VERSION ""

NS_ :

BS_:

BU_: Engine2 Aftertreatment_1_GasOutlet BrakesSystemController Transmission1 Engine1
VAL_TABLE_ FMI 22 "Data Drifted Low" 21 "Data Drifted High" 20 "Received Network Data In Error" 0 "Above normal (most severe)" 1 "Below normal (most severe)" 2 "Data erratic" 3 "Voltage above normal" 4 "Voltage below normal" 5 "Current below normal" 6 "Current above normal" 7 "Mechanical system not responding" 8 "Abnormal frequency" 9 "Abnormal update rate" 10 "Abnormal rate of change" 11 "Root cause not known" 12 "Bad intelligent device" 13 "Out of calibration" 14 "Special intstructions" 15 "Above normal (least severe)" 16 "Above normal (moderately severe)" 17 "Below normal (least severe)" 18 "Below normal (moderately severe)" 19 "Received network data in error" 31 "Condition Exists" ;
VAL_TABLE_ TireLocation_MUX 51 "TirePress_33_MUX_51" 50 "TirePress_32_MUX_50" 49 "TirePress_31_MUX_49" 48 "TirePress_30_MUX_48" 35 "TirePress_23_MUX_35" 34 "TirePress_22_MUX_34" 33 "TirePress_21_MUX_33" 32 "TirePress_20_MUX_32" 19 "TirePress_13_MUX_19" 18 "TirePress_12_MUX_18" 17 "TirePress_11_MUX_17" 16 "TirePress_10_MUX_16" 1 "TirePress_01_MUX_1" 0 "TirePress_00_MUX_0" ;

BO_ 3221225472 VECTOR__INDEPENDENT_SIG_MSG: 0 Vector__XXX
 SG_ NumberOfMembersInWorkingSet : 0|8@1+ (1,0) [0|0] "" Vector__XXX
 SG_ NncntnuslyMonitoredSystemsStatus : 0|16@1+ (1,0) [0|0] "" Vector__XXX
 SG_ NncntnslyMonitoredSystemsSupport : 0|16@1+ (1,0) [0|0] "" Vector__XXX
 SG_ CntnslyMntrdSystmsSupport_Status : 0|8@1+ (1,0) [0|0] "" Vector__XXX
 SG_ AETCTorqueValue : 0|16@1+ (1,0) [0|64255] "Nm" Vector__XXX
 SG_ TrailerWeight : 0|16@1+ (2,0) [0|128510] "kg" Vector__XXX
 SG_ ReferenceTirePressSetting : 0|8@1+ (8,0) [0|2000] "kPa" Vector__XXX
 SG_ ReferenceTirePress : 0|8@1+ (8,0) [0|2000] "kPa" Vector__XXX
 SG_ TirePressThresholdDetection : 0|3@1+ (1,0) [0|7] "" Vector__XXX
 SG_ TireAirLeakageRate : 0|16@1+ (0.1,0) [0|6425.5] "Pa/s" Vector__XXX
 SG_ CTIWheelEndElectricalFault : 0|2@1+ (1,0) [0|3] "" Vector__XXX
 SG_ CTITireStatus : 0|2@1+ (1,0) [0|3] "" Vector__XXX
 SG_ CTIWheelSensorStatus : 0|2@1+ (1,0) [0|3] "" Vector__XXX
 SG_ TireTemp : 0|16@1+ (0.03125,-273) [-273|1734.96875] "deg C" Vector__XXX
 SG_ TirePress : 0|8@1+ (4,0) [0|1000] "kPa" Vector__XXX
 SG_ EngTurningGearEngaged : 0|2@1+ (1,0) [0|3] "" Vector__XXX
 SG_ AETCSpeedValue : 0|16@1+ (0.125,0) [0|8031.875] "rpm" Vector__XXX
 SG_ DTC5 : 0|32@1+ (1,0) [0|4294967295] "" Vector__XXX
 SG_ DTC4 : 0|32@1+ (1,0) [0|4294967295] "" Vector__XXX
 SG_ DTC3 : 0|32@1+ (1,0) [0|4294967295] "" Vector__XXX
 SG_ DTC2 : 0|32@1+ (1,0) [0|4294967295] "" Vector__XXX
 SG_ DTC5 : 0|32@1+ (1,0) [0|4294967295] "" Vector__XXX
 SG_ DTC4 : 0|32@1+ (1,0) [0|4294967295] "" Vector__XXX
 SG_ DTC3 : 0|32@1+ (1,0) [0|4294967295] "" Vector__XXX
 SG_ DTC2 : 0|32@1+ (1,0) [0|4294967295] "" Vector__XXX

BO_ 2365534462 MOP: 42 Vector__XXX

BO_ 2566834689 DM01_Eng2: 8 Engine2
 SG_ FlashRedStopLamp : 12|2@1+ (1,0) [0|3] "" Vector__XXX
 SG_ FlashProtectLamp : 8|2@1+ (1,0) [0|3] "" Vector__XXX
 SG_ FlashMalfuncIndicatorLamp : 14|2@1+ (1,0) [0|3] "" Vector__XXX
 SG_ FlashAmberWarningLamp : 10|2@1+ (1,0) [0|3] "" Vector__XXX
 SG_ MalfunctionIndicatorLampStatus : 6|2@1+ (1,0) [0|3] "" Vector__XXX
 SG_ AmberWarningLampStatus : 2|2@1+ (1,0) [0|3] "" Vector__XXX
 SG_ RedStopLampState : 4|2@1+ (1,0) [0|3] "" Vector__XXX
 SG_ ProtectLampStatus : 0|2@1+ (1,0) [0|3] "" Vector__XXX
 SG_ DTC5 : 144|32@1+ (1,0) [0|4294967295] "" Vector__XXX
 SG_ DTC4 : 112|32@1+ (1,0) [0|4294967295] "" Vector__XXX
 SG_ DTC3 : 80|32@1+ (1,0) [0|4294967295] "" Vector__XXX
 SG_ DTC2 : 48|32@1+ (1,0) [0|4294967295] "" Vector__XXX
 SG_ DTC1 : 16|32@1+ (1,0) [0|4294967295] "" Vector__XXX

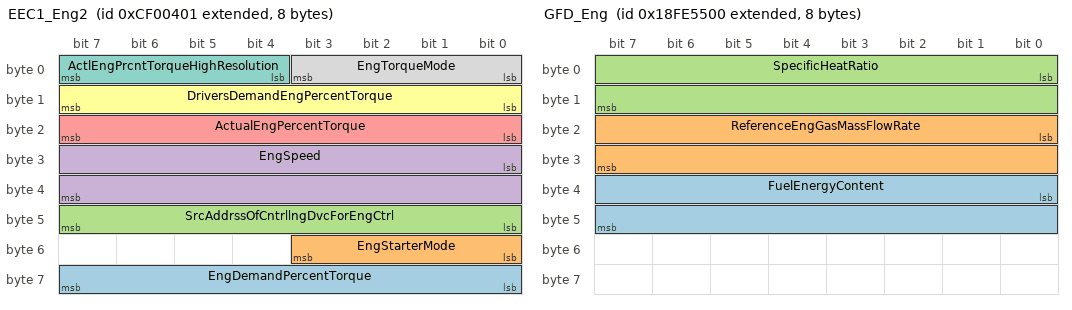
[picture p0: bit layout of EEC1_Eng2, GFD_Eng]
BO_ 2364539905 EEC1_Eng2: 8 Engine2
 SG_ EngDemandPercentTorque : 56|8@1+ (1,-125) [-125|125] "%" Vector__XXX
 SG_ EngStarterMode : 48|4@1+ (1,0) [0|15] "" Vector__XXX
 SG_ SrcAddrssOfCntrllngDvcForEngCtrl : 40|8@1+ (1,0) [0|253] "" Vector__XXX
 SG_ EngSpeed : 24|16@1+ (0.125,0) [0|8031.875] "rpm" Vector__XXX
 SG_ ActualEngPercentTorque : 16|8@1+ (1,-125) [0|125] "%" Vector__XXX
 SG_ DriversDemandEngPercentTorque : 8|8@1+ (1,-125) [0|125] "%" Vector__XXX
 SG_ ActlEngPrcntTorqueHighResolution : 4|4@1+ (0.125,0) [0|0.875] "%" Vector__XXX
 SG_ EngTorqueMode : 0|4@1+ (1,0) [0|15] "" Vector__XXX

BO_ 2364473089 AC_Eng2: 8 Engine2
 SG_ ArbitraryAddressCapable : 63|1@1+ (1,0) [0|1] "" Vector__XXX
 SG_ IndustryGroup M : 60|3@1+ (1,0) [0|7] "" Vector__XXX
 SG_ VehicleSystemInstance : 56|4@1+ (1,0) [0|15] "" Vector__XXX
 SG_ Function : 40|8@1+ (1,0) [0|255] "" Vector__XXX
 SG_ FunctionInstance : 35|5@1+ (1,0) [0|31] "" Vector__XXX
 SG_ ECUInstance : 32|3@1+ (1,0) [0|7] "" Vector__XXX
 SG_ ManufacturerCode : 21|11@1+ (1,0) [0|2047] "" Vector__XXX
 SG_ IdentityNumber : 0|21@1+ (1,0) [0|2097152] "" Vector__XXX
 SG_ VehicleSystem m0 : 49|7@1+ (1,0) [0|127] "" Vector__XXX
 SG_ VehicleSystem5 m5 : 49|7@1+ (1,0) [0|127] "" Vector__XXX
 SG_ VehicleSystem4 m4 : 49|7@1+ (1,0) [0|127] "" Vector__XXX
 SG_ VehicleSystem3 m3 : 49|7@1+ (1,0) [0|127] "" Vector__XXX
 SG_ VehicleSystem2 m2 : 49|7@1+ (1,0) [0|127] "" Vector__XXX
 SG_ VehicleSystem1 m1 : 49|7@1+ (1,0) [0|127] "" Vector__XXX

BO_ 2364145746 RQST_At1Out: 3 Aftertreatment_1_GasOutlet
 SG_ ParameterGroupNumber : 0|24@1+ (1,0) [0|16777215] ""  Engine1

BO_ 2566804736 GFD_Eng: 8 Engine1
 SG_ FuelEnergyContent : 32|16@1+ (0.00390625,0) [0|250.996] "MJ/Nm³" Vector__XXX
 SG_ ReferenceEngGasMassFlowRate : 16|16@1+ (0.05,0) [0|3212.75] "kg/h" Vector__XXX
 SG_ SpecificHeatRatio : 0|16@1+ (0.001,0) [0|2] "" Vector__XXX

BO_ 2633936640 GFC_Eng: 8 Engine1
 SG_ TotalFuelUsed : 32|32@1+ (0.5,0) [0|2105540607.5] "kg" Vector__XXX
 SG_ TripFuel : 0|32@1+ (0.5,0) [0|2105540607.5] "kg" Vector__XXX

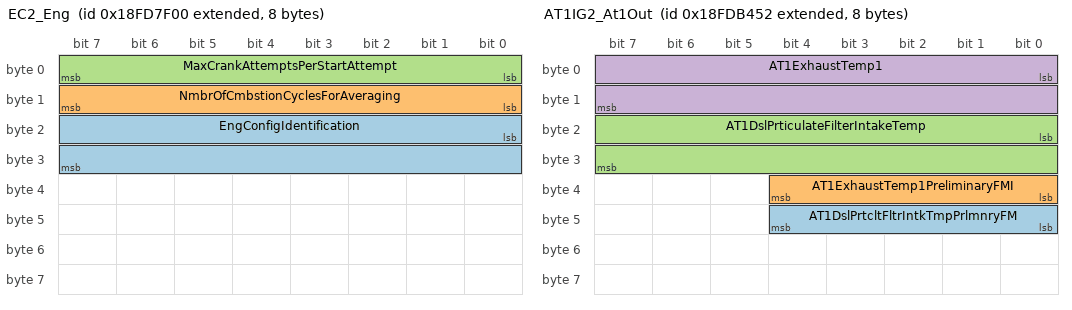
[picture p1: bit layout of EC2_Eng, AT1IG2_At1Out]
BO_ 2566749952 EC2_Eng: 8 Engine1
 SG_ EngConfigIdentification : 16|16@1+ (1,0) [0|64255] "" Vector__XXX
 SG_ NmbrOfCmbstionCyclesForAveraging : 8|8@1+ (1,0) [1|250] "" Vector__XXX
 SG_ MaxCrankAttemptsPerStartAttempt : 0|8@1+ (1,0) [0|250] "" Vector__XXX

BO_ 2566841088 EC1_Eng: 39 Engine1
 SG_ SupportTSC1CtrlPurposeGroup4 : 304|8@1+ (1,0) [0|255] "" Vector__XXX
 SG_ SupportTSC1CtrlPurposeGroup3 : 296|8@1+ (1,0) [0|255] "" Vector__XXX
 SG_ SupportTSC1CtrlPurposeGroup2 : 288|8@1+ (1,0) [0|255] "" Vector__XXX
 SG_ SupportTSC1CtrlPurposeGroup1 : 280|8@1+ (1,0) [0|255] "" Vector__XXX
 SG_ SupportVariableRateTSC1Message : 272|8@1+ (1,0) [0|255] "" Vector__XXX
 SG_ EngDefaultTorqueLimit : 256|16@1+ (1,0) [0|64255] "Nm" Vector__XXX
 SG_ EngMomentOfInertia : 240|16@1+ (0.004,0) [0|257.02] "kg/m²" Vector__XXX
 SG_ EngExRngRqstdSpdCtrlRngUpprLimit : 224|16@1+ (0.125,0) [0|8031.875] "rpm" Vector__XXX
 SG_ EngRqstdTrqueCtrlRangeUpperLimit : 216|8@1+ (1,-125) [0|125] "%" Vector__XXX
 SG_ EngRqstdTrqueCtrlRangeLowerLimit : 208|8@1+ (1,-125) [0|125] "%" Vector__XXX
 SG_ EngRqstdSpeedCtrlRangeUpperLimit : 200|8@1+ (10,0) [0|2500] "rpm" Vector__XXX
 SG_ EngRqstdSpeedCtrlRangeLowerLimit : 192|8@1+ (10,0) [0|2500] "rpm" Vector__XXX
 SG_ EngMaxMomentaryOverrideTimeLimit : 184|8@1+ (0.1,0) [0|25] "s" Vector__XXX
 SG_ EngMxMmentaryOverrideSpeedPoint7 : 168|16@1+ (0.125,0) [0|8031.875] "rpm" Vector__XXX
 SG_ EngReferenceTorque : 152|16@1+ (1,0) [0|64255] "Nm" Vector__XXX
 SG_ EngGain : 136|16@1+ (0.00078125,0) [0|50.2] "%/rpm" Vector__XXX
 SG_ EngSpeedAtHighIdlePoint6 : 120|16@1+ (0.125,0) [0|8031.875] "rpm" Vector__XXX
 SG_ EngPercentTorqueAtPoint5 : 112|8@1+ (1,-125) [0|125] "%" Vector__XXX
 SG_ EngSpeedAtPoint5 : 96|16@1+ (0.125,0) [0|8031.875] "rpm" Vector__XXX
 SG_ EngPercentTorqueAtPoint4 : 88|8@1+ (1,-125) [0|125] "%" Vector__XXX
 SG_ EngSpeedAtPoint4 : 72|16@1+ (0.125,0) [0|8031.875] "rpm" Vector__XXX
 SG_ EngPercentTorqueAtPoint3 : 64|8@1+ (1,-125) [0|125] "%" Vector__XXX
 SG_ EngSpeedAtPoint3 : 48|16@1+ (0.125,0) [0|8031.875] "rpm" Vector__XXX
 SG_ EngPercentTorqueAtPoint2 : 40|8@1+ (1,-125) [0|125] "%" Vector__XXX
 SG_ EngSpeedAtPoint2 : 24|16@1+ (0.125,0) [0|8031.875] "rpm" Vector__XXX
 SG_ EngPercentTorqueAtIdlePoint1 : 16|8@1+ (1,-125) [0|125] "%" Vector__XXX
 SG_ EngSpeedAtIdlePoint1 : 0|16@1+ (0.125,0) [0|8031.875] "rpm" Vector__XXX

BO_ 2566763602 AT1IG2_At1Out: 8 Aftertreatment_1_GasOutlet
 SG_ AT1DslPrtcltFltrIntkTmpPrlmnryFM : 40|5@1+ (1,0) [0|31] "" Vector__XXX
 SG_ AT1ExhaustTemp1PreliminaryFMI : 32|5@1+ (1,0) [0|31] "" Vector__XXX
 SG_ AT1DslPrticulateFilterIntakeTemp : 16|16@1+ (0.03125,-273) [-273|1734.96875] "°C" Vector__XXX
 SG_ AT1ExhaustTemp1 : 0|16@1+ (0.03125,-273) [-273|1734.96875] "°C" Vector__XXX

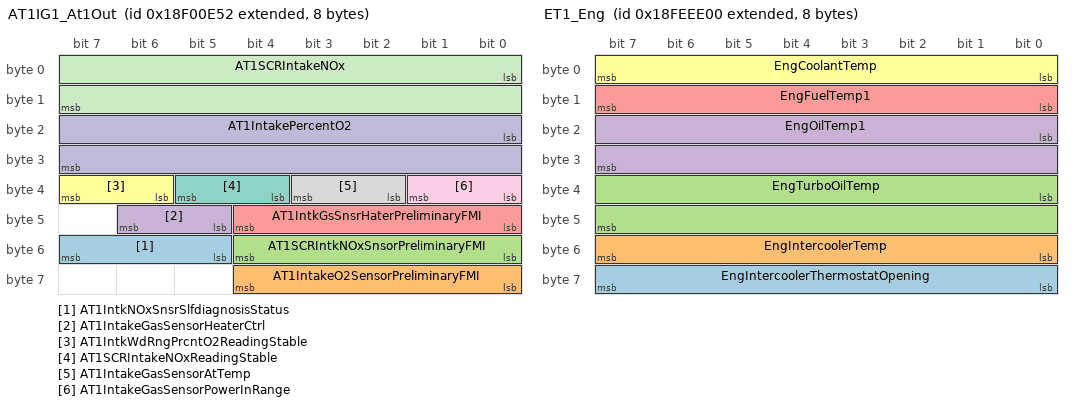
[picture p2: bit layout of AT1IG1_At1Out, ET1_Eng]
BO_ 2565869138 AT1IG1_At1Out: 8 Aftertreatment_1_GasOutlet
 SG_ AT1IntkNOxSnsrSlfdiagnosisStatus : 53|3@1+ (1,0) [0|7] "" Vector__XXX
 SG_ AT1IntakeO2SensorPreliminaryFMI : 56|5@1+ (1,0) [0|31] "" Vector__XXX
 SG_ AT1SCRIntkNOxSnsorPreliminaryFMI : 48|5@1+ (1,0) [0|31] "" Vector__XXX
 SG_ AT1IntakeGasSensorHeaterCtrl : 45|2@1+ (1,0) [0|3] "" Vector__XXX
 SG_ AT1IntkGsSnsrHaterPreliminaryFMI : 40|5@1+ (1,0) [0|31] "" Vector__XXX
 SG_ AT1IntkWdRngPrcntO2ReadingStable : 38|2@1+ (1,0) [0|3] "" Vector__XXX
 SG_ AT1SCRIntakeNOxReadingStable : 36|2@1+ (1,0) [0|3] "" Vector__XXX
 SG_ AT1IntakeGasSensorAtTemp : 34|2@1+ (1,0) [0|3] "" Vector__XXX
 SG_ AT1IntakeGasSensorPowerInRange : 32|2@1+ (1,0) [0|3] "" Vector__XXX
 SG_ AT1IntakePercentO2 : 16|16@1+ (0.000514,-12) [-12|21.02707] "%" Vector__XXX
 SG_ AT1SCRIntakeNOx : 0|16@1+ (0.05,-200) [-200|3012.75] "ppm" Vector__XXX

BO_ 2566670674 AT1HI2_At1Out: 8 Vector__XXX
 SG_ AT1SCRSystmAvrgDstncBtwnSystmCln : 160|32@1+ (0.125,0) [0|526385151.875] "km" Vector__XXX
 SG_ AT1SCRSystmAvrgTmBtwnSystmClnngE : 128|32@1+ (1,0) [0|4211081215] "s" Vector__XXX
 SG_ AT1SCRSystmTtlNmbrOfSystmClnngMn : 96|32@1+ (1,0) [0|4211081215] "" Vector__XXX
 SG_ AT1SCRSystmTtlNmbrOfSystmClnngIn : 64|32@1+ (1,0) [0|4211081215] "" Vector__XXX
 SG_ AT1SCRSystmTtlNmbrOfSystmClnngEv : 32|32@1+ (1,0) [0|4211081215] "" Vector__XXX
 SG_ AT1SCRSystemTotalCleaningTime : 0|32@1+ (1,0) [0|4211081215] "s" Vector__XXX

BO_ 2566756434 AT1HI1_At1Out: 8 Vector__XXX
 SG_ AT1DslPrtcltFltrAvrgDstncBtwnAct : 288|32@1+ (0.125,0) [0|526385151.875] "km" Vector__XXX
 SG_ AT1DslPrtcltFltrAvrgTmBtwnActvRg : 256|32@1+ (1,0) [0|4211081215] "s" Vector__XXX
 SG_ AT1DslPrtcltFltrTtlNmbrOfAct3728 : 224|32@1+ (1,0) [0|4211081215] "" Vector__XXX
 SG_ AT1DslPrtcltFltrTtlNmbrOfActvRgn : 192|32@1+ (1,0) [0|4211081215] "" Vector__XXX
 SG_ AT1DslPrtcltFltrTtlNmbrOfPssvRgn : 160|32@1+ (1,0) [0|4211081215] "" Vector__XXX
 SG_ AT1DslPrtcltFltrTtlPssvRgnrtnTme : 128|32@1+ (1,0) [0|4211081215] "s" Vector__XXX
 SG_ AT1TtlNmberOfActiveRegenerations : 96|32@1+ (1,0) [0|4211081215] "" Vector__XXX
 SG_ AT1TotalDisabledTime : 64|32@1+ (1,0) [0|4211081215] "s" Vector__XXX
 SG_ AT1TotalRegenerationTime : 32|32@1+ (1,0) [0|4211081215] "s" Vector__XXX
 SG_ AT1TotalFuelUsed : 0|32@1+ (0.5,0) [0|2105540607.5] "L" Vector__XXX

BO_ 2566843904 ET1_Eng: 8 Engine1
 SG_ EngIntercoolerThermostatOpening : 56|8@1+ (0.4,0) [0|100] "%" Vector__XXX
 SG_ EngIntercoolerTemp : 48|8@1+ (1,-40) [-40|210] "°C" Vector__XXX
 SG_ EngTurboOilTemp : 32|16@1+ (0.03125,-273) [-273|1734.96875] "°C" Vector__XXX
 SG_ EngOilTemp1 : 16|16@1+ (0.03125,-273) [-273|1734.96875] "°C" Vector__XXX
 SG_ EngFuelTemp1 : 8|8@1+ (1,-40) [-40|210] "°C" Vector__XXX
 SG_ EngCoolantTemp : 0|8@1+ (1,-40) [-40|210] "°C" Vector__XXX

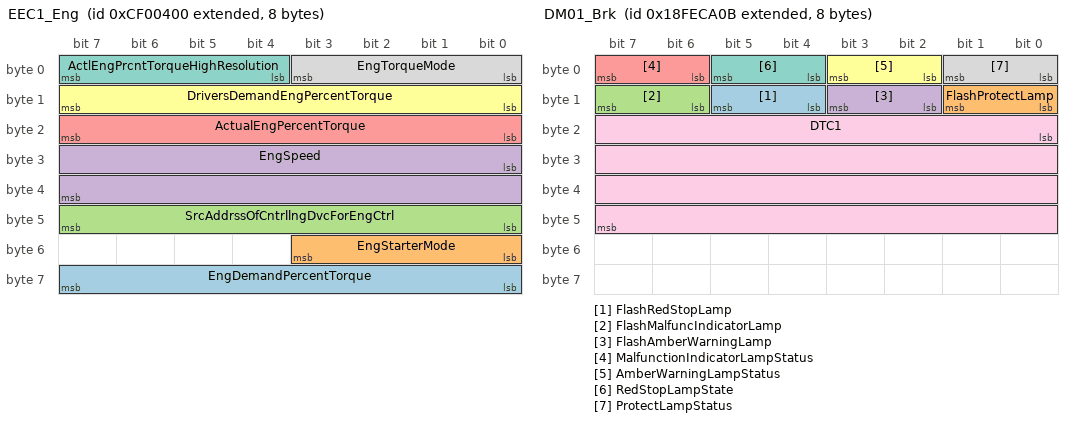
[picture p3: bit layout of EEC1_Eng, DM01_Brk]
BO_ 2364539904 EEC1_Eng: 8 Engine1
 SG_ EngDemandPercentTorque : 56|8@1+ (1,-125) [-125|125] "%" Vector__XXX
 SG_ EngStarterMode : 48|4@1+ (1,0) [0|15] "" Vector__XXX
 SG_ SrcAddrssOfCntrllngDvcForEngCtrl : 40|8@1+ (1,0) [0|253] "" Vector__XXX
 SG_ EngSpeed : 24|16@1+ (0.125,0) [0|8031.875] "rpm" Vector__XXX
 SG_ ActualEngPercentTorque : 16|8@1+ (1,-125) [0|125] "%" Vector__XXX
 SG_ DriversDemandEngPercentTorque : 8|8@1+ (1,-125) [0|125] "%" Vector__XXX
 SG_ ActlEngPrcntTorqueHighResolution : 4|4@1+ (0.125,0) [0|0.875] "%" Vector__XXX
 SG_ EngTorqueMode : 0|4@1+ (1,0) [0|15] "" Vector__XXX

BO_ 2566834770 DM01_At1Out: 14 Aftertreatment_1_GasOutlet
 SG_ FlashRedStopLamp : 12|2@1+ (1,0) [0|3] "" Vector__XXX
 SG_ FlashProtectLamp : 8|2@1+ (1,0) [0|3] "" Vector__XXX
 SG_ FlashMalfuncIndicatorLamp : 14|2@1+ (1,0) [0|3] "" Vector__XXX
 SG_ FlashAmberWarningLamp : 10|2@1+ (1,0) [0|3] "" Vector__XXX
 SG_ MalfunctionIndicatorLampStatus : 6|2@1+ (1,0) [0|3] "" Vector__XXX
 SG_ AmberWarningLampStatus : 2|2@1+ (1,0) [0|3] "" Vector__XXX
 SG_ RedStopLampState : 4|2@1+ (1,0) [0|3] "" Vector__XXX
 SG_ ProtectLampStatus : 0|2@1+ (1,0) [0|3] "" Vector__XXX
 SG_ DTC3 : 80|32@1+ (1,0) [0|4294967295] "" Vector__XXX
 SG_ DTC2 : 48|32@1+ (1,0) [0|4294967295] "" Vector__XXX
 SG_ DTC1 : 16|32@1+ (1,0) [0|4294967295] "" Vector__XXX

BO_ 2566834699 DM01_Brk: 8 BrakesSystemController
 SG_ FlashRedStopLamp : 12|2@1+ (1,0) [0|3] "" Vector__XXX
 SG_ FlashProtectLamp : 8|2@1+ (1,0) [0|3] "" Vector__XXX
 SG_ FlashMalfuncIndicatorLamp : 14|2@1+ (1,0) [0|3] "" Vector__XXX
 SG_ FlashAmberWarningLamp : 10|2@1+ (1,0) [0|3] "" Vector__XXX
 SG_ MalfunctionIndicatorLampStatus : 6|2@1+ (1,0) [0|3] "" Vector__XXX
 SG_ AmberWarningLampStatus : 2|2@1+ (1,0) [0|3] "" Vector__XXX
 SG_ RedStopLampState : 4|2@1+ (1,0) [0|3] "" Vector__XXX
 SG_ ProtectLampStatus : 0|2@1+ (1,0) [0|3] "" Vector__XXX
 SG_ DTC1 : 16|32@1+ (1,0) [0|4294967295] "" Vector__XXX

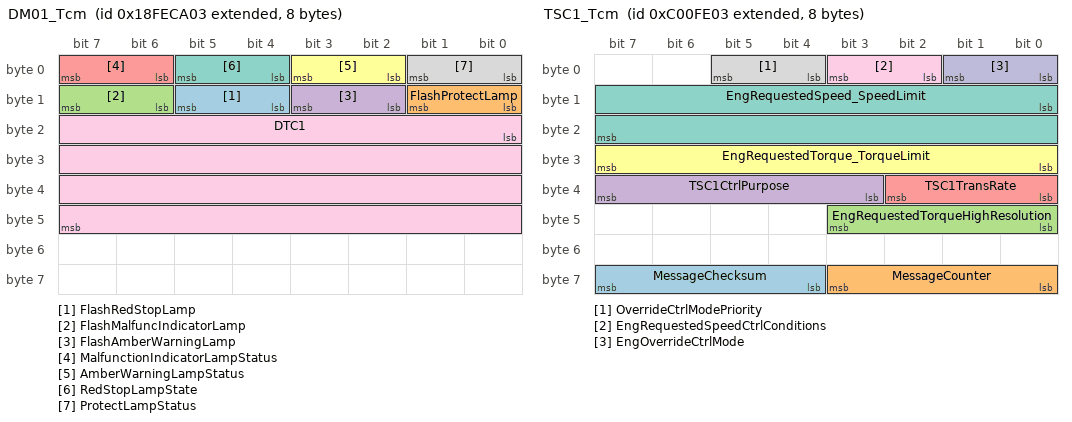
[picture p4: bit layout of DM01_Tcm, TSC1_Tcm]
BO_ 2566834691 DM01_Tcm: 8 Transmission1
 SG_ FlashRedStopLamp : 12|2@1+ (1,0) [0|3] "" Vector__XXX
 SG_ FlashProtectLamp : 8|2@1+ (1,0) [0|3] "" Vector__XXX
 SG_ FlashMalfuncIndicatorLamp : 14|2@1+ (1,0) [0|3] "" Vector__XXX
 SG_ FlashAmberWarningLamp : 10|2@1+ (1,0) [0|3] "" Vector__XXX
 SG_ MalfunctionIndicatorLampStatus : 6|2@1+ (1,0) [0|3] "" Vector__XXX
 SG_ AmberWarningLampStatus : 2|2@1+ (1,0) [0|3] "" Vector__XXX
 SG_ RedStopLampState : 4|2@1+ (1,0) [0|3] "" Vector__XXX
 SG_ ProtectLampStatus : 0|2@1+ (1,0) [0|3] "" Vector__XXX
 SG_ DTC1 : 16|32@1+ (1,0) [0|4294967295] "" Vector__XXX

BO_ 2566834688 DM01_Eng: 8 Engine1
 SG_ FlashRedStopLamp : 12|2@1+ (1,0) [0|3] "" Vector__XXX
 SG_ FlashProtectLamp : 8|2@1+ (1,0) [0|3] "" Vector__XXX
 SG_ FlashMalfuncIndicatorLamp : 14|2@1+ (1,0) [0|3] "" Vector__XXX
 SG_ FlashAmberWarningLamp : 10|2@1+ (1,0) [0|3] "" Vector__XXX
 SG_ MalfunctionIndicatorLampStatus : 6|2@1+ (1,0) [0|3] "" Vector__XXX
 SG_ AmberWarningLampStatus : 2|2@1+ (1,0) [0|3] "" Vector__XXX
 SG_ RedStopLampState : 4|2@1+ (1,0) [0|3] "" Vector__XXX
 SG_ ProtectLampStatus : 0|2@1+ (1,0) [0|3] "" Vector__XXX
 SG_ DTC5 : 144|32@1+ (1,0) [0|4294967295] "" Vector__XXX
 SG_ DTC4 : 112|32@1+ (1,0) [0|4294967295] "" Vector__XXX
 SG_ DTC3 : 80|32@1+ (1,0) [0|4294967295] "" Vector__XXX
 SG_ DTC2 : 48|32@1+ (1,0) [0|4294967295] "" Vector__XXX
 SG_ DTC1 : 16|32@1+ (1,0) [0|4294967295] "" Vector__XXX

BO_ 2348875267 TSC1_Tcm: 8 Transmission1
 SG_ MessageChecksum : 60|4@1+ (1,0) [0|15] "" Vector__XXX
 SG_ MessageCounter : 56|4@1+ (1,0) [0|15] "" Vector__XXX
 SG_ EngRequestedTorqueHighResolution : 40|4@1+ (0.125,0) [0|0.875] "%" Vector__XXX
 SG_ TSC1CtrlPurpose : 35|5@1+ (1,0) [0|31] "" Vector__XXX
 SG_ TSC1TransRate : 32|3@1+ (1,0) [0|7] "" Vector__XXX
 SG_ EngRequestedTorque_TorqueLimit : 24|8@1+ (1,-125) [-125|125] "%" Vector__XXX
 SG_ EngRequestedSpeed_SpeedLimit : 8|16@1+ (0.125,0) [0|8031.875] "rpm" Vector__XXX
 SG_ OverrideCtrlModePriority : 4|2@1+ (1,0) [0|3] "" Vector__XXX
 SG_ EngRequestedSpeedCtrlConditions : 2|2@1+ (1,0) [0|3] "" Vector__XXX
 SG_ EngOverrideCtrlMode : 0|2@1+ (1,0) [0|3] "" Vector__XXX

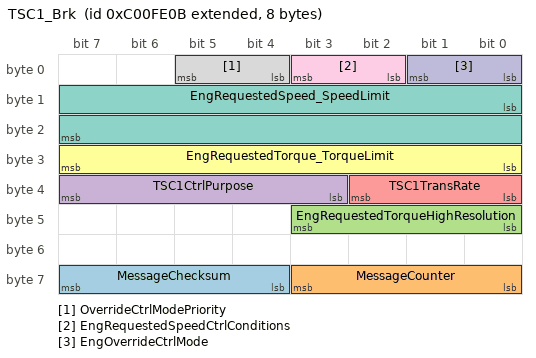
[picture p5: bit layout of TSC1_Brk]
BO_ 2348875275 TSC1_Brk: 8 BrakesSystemController
 SG_ MessageChecksum : 60|4@1+ (1,0) [0|15] "" Vector__XXX
 SG_ MessageCounter : 56|4@1+ (1,0) [0|15] "" Vector__XXX
 SG_ EngRequestedTorqueHighResolution : 40|4@1+ (0.125,0) [0|0.875] "%" Vector__XXX
 SG_ TSC1CtrlPurpose : 35|5@1+ (1,0) [0|31] "" Vector__XXX
 SG_ TSC1TransRate : 32|3@1+ (1,0) [0|7] "" Vector__XXX
 SG_ EngRequestedTorque_TorqueLimit : 24|8@1+ (1,-125) [-125|125] "%" Vector__XXX
 SG_ EngRequestedSpeed_SpeedLimit : 8|16@1+ (0.125,0) [0|8031.875] "rpm" Vector__XXX
 SG_ OverrideCtrlModePriority : 4|2@1+ (1,0) [0|3] "" Vector__XXX
 SG_ EngRequestedSpeedCtrlConditions : 2|2@1+ (1,0) [0|3] "" Vector__XXX
 SG_ EngOverrideCtrlMode : 0|2@1+ (1,0) [0|3] "" Vector__XXX

BO_ 2364473091 AC_Tcm: 8 Transmission1
 SG_ ArbitraryAddressCapable : 63|1@1+ (1,0) [0|1] "" Vector__XXX
 SG_ IndustryGroup M : 60|3@1+ (1,0) [0|7] "" Vector__XXX
 SG_ VehicleSystemInstance : 56|4@1+ (1,0) [0|15] "" Vector__XXX
 SG_ Function : 40|8@1+ (1,0) [0|255] "" Vector__XXX
 SG_ FunctionInstance : 35|5@1+ (1,0) [0|31] "" Vector__XXX
 SG_ ECUInstance : 32|3@1+ (1,0) [0|7] "" Vector__XXX
 SG_ ManufacturerCode : 21|11@1+ (1,0) [0|2047] "" Vector__XXX
 SG_ IdentityNumber : 0|21@1+ (1,0) [0|2097152] "" Vector__XXX
 SG_ VehicleSystem m0 : 49|7@1+ (1,0) [0|127] "" Vector__XXX
 SG_ VehicleSystem5 m5 : 49|7@1+ (1,0) [0|127] "" Vector__XXX
 SG_ VehicleSystem4 m4 : 49|7@1+ (1,0) [0|127] "" Vector__XXX
 SG_ VehicleSystem3 m3 : 49|7@1+ (1,0) [0|127] "" Vector__XXX
 SG_ VehicleSystem2 m2 : 49|7@1+ (1,0) [0|127] "" Vector__XXX
 SG_ VehicleSystem1 m1 : 49|7@1+ (1,0) [0|127] "" Vector__XXX

BO_ 2364473088 AC_Eng: 8 Engine1
 SG_ ArbitraryAddressCapable : 63|1@1+ (1,0) [0|1] "" Vector__XXX
 SG_ IndustryGroup M : 60|3@1+ (1,0) [0|7] "" Vector__XXX
 SG_ VehicleSystemInstance : 56|4@1+ (1,0) [0|15] "" Vector__XXX
 SG_ Function : 40|8@1+ (1,0) [0|255] "" Vector__XXX
 SG_ FunctionInstance : 35|5@1+ (1,0) [0|31] "" Vector__XXX
 SG_ ECUInstance : 32|3@1+ (1,0) [0|7] "" Vector__XXX
 SG_ ManufacturerCode : 21|11@1+ (1,0) [0|2047] "" Vector__XXX
 SG_ IdentityNumber : 0|21@1+ (1,0) [0|2097152] "" Vector__XXX
 SG_ VehicleSystem m0 : 49|7@1+ (1,0) [0|127] "" Vector__XXX
 SG_ VehicleSystem5 m5 : 49|7@1+ (1,0) [0|127] "" Vector__XXX
 SG_ VehicleSystem4 m4 : 49|7@1+ (1,0) [0|127] "" Vector__XXX
 SG_ VehicleSystem3 m3 : 49|7@1+ (1,0) [0|127] "" Vector__XXX
 SG_ VehicleSystem2 m2 : 49|7@1+ (1,0) [0|127] "" Vector__XXX
 SG_ VehicleSystem1 m1 : 49|7@1+ (1,0) [0|127] "" Vector__XXX

BO_ 2364473099 AC_Brk: 8 BrakesSystemController
 SG_ ArbitraryAddressCapable : 63|1@1+ (1,0) [0|1] "" Vector__XXX
 SG_ IndustryGroup M : 60|3@1+ (1,0) [0|7] "" Vector__XXX
 SG_ VehicleSystemInstance : 56|4@1+ (1,0) [0|15] "" Vector__XXX
 SG_ Function : 40|8@1+ (1,0) [0|255] "" Vector__XXX
 SG_ FunctionInstance : 35|5@1+ (1,0) [0|31] "" Vector__XXX
 SG_ ECUInstance : 32|3@1+ (1,0) [0|7] "" Vector__XXX
 SG_ ManufacturerCode : 21|11@1+ (1,0) [0|2047] "" Vector__XXX
 SG_ IdentityNumber : 0|21@1+ (1,0) [0|2097152] "" Vector__XXX
 SG_ VehicleSystem m0 : 49|7@1+ (1,0) [0|127] "" Vector__XXX
 SG_ VehicleSystem5 m5 : 49|7@1+ (1,0) [0|127] "" Vector__XXX
 SG_ VehicleSystem4 m4 : 49|7@1+ (1,0) [0|127] "" Vector__XXX
 SG_ VehicleSystem3 m3 : 49|7@1+ (1,0) [0|127] "" Vector__XXX
 SG_ VehicleSystem2 m2 : 49|7@1+ (1,0) [0|127] "" Vector__XXX
 SG_ VehicleSystem1 m1 : 49|7@1+ (1,0) [0|127] "" Vector__XXX

CM_ BO_ 3221225472 "This is a message for not used signals, created by Vector CANdb++ DBC OLE DB Provider.";
CM_ SG_ 3221225472 NumberOfMembersInWorkingSet "The number of members in a particular Working Set.";
CM_ SG_ 3221225472 NncntnuslyMonitoredSystemsStatus "Identifies the non-continuously monitored systems status. Each bit identifies whether a particular test is complete for a given controller.
";
CM_ SG_ 3221225472 NncntnslyMonitoredSystemsSupport "Identifies the non-continuously monitored systems support.
";
CM_ SG_ 3221225472 CntnslyMntrdSystmsSupport_Status "Identifies the continuously monitored system support and status.
";
CM_ SG_ 3221225472 AETCTorqueValue "Engine torque value of the data points in PGN 64912 – Advertised Engine Torque Curve (AETC).";
CM_ SG_ 3221225472 TrailerWeight "Total mass of freight-carrying vehicle designed to be pulled by truck, including the weight of the contents.";
CM_ SG_ 3221225472 ReferenceTirePressSetting "Reference value of the tire pressure setting as basis for the tire pressure monitoring ...";
CM_ SG_ 3221225472 ReferenceTirePress "Reference value of the tire pressure as basis for the tire pressure monitoring ...";
CM_ SG_ 3221225472 TirePressThresholdDetection "Signal indicating the pressure level of the tire.  The levels defined represent different pressure conditions of the tire: 000 Extreme over pressure - The tire pressure is at a level where the safety of the vehicle may be jeopardised.";
CM_ SG_ 3221225472 TireAirLeakageRate "The pressure loss rate of a tire.";
CM_ SG_ 3221225472 CTIWheelEndElectricalFault "Indicates the status of electrical fault on CTI wheel interface.";
CM_ SG_ 3221225472 CTITireStatus "Indicates the status of the tire.";
CM_ SG_ 3221225472 CTIWheelSensorStatus "Indicates whether the wheel is being monitored by the CTI controller.";
CM_ SG_ 3221225472 TireTemp "Temperature at the surface of the tire sidewall.";
CM_ SG_ 3221225472 TirePress "Pressure at which air is contained in cavity formed by tire and rim.";
CM_ SG_ 3221225472 EngTurningGearEngaged "Status signal which indicates that the turning gear is engaged.  The turning gear is used to turn the flywheel/crankshaft, ...";
CM_ SG_ 3221225472 AETCSpeedValue "Engine speed value of the data points in PGN 64912 – Advertised Engine Torque Curve (AETC).";
CM_ SG_ 3221225472 DTC5 "Diagnostic Trouble CodeDiagnostic Trouble Code";
CM_ SG_ 3221225472 DTC4 "Diagnostic Trouble CodeDiagnostic Trouble Code";
CM_ SG_ 3221225472 DTC3 "Diagnostic Trouble CodeDiagnostic Trouble Code";
CM_ SG_ 3221225472 DTC2 "Diagnostic Trouble CodeDiagnostic Trouble Code";
CM_ BO_ 2566834689 "Active Diagnostic Trouble Codes";
CM_ SG_ 2566834689 FlashRedStopLamp "This parameter provides the capability to flash the RSL


00 - Slow Flash (1 Hz, 50 % duty cycle)
01 - Fast Flash (2 Hz or faster, 50% duty cycle)
10 - Reserved
11 - Unavailable / Do Not Flash";
CM_ SG_ 2566834689 FlashProtectLamp "This parameter provides the capability to flash the engine protect lamp


00 - Slow Flash (1 Hz, 50 % duty cycle)
01 - Fast Flash (2 Hz or faster, 50% duty cycle)
10 - Reserved
11 - Unavailable / Do Not Flash";
CM_ SG_ 2566834689 FlashMalfuncIndicatorLamp "This parameter provides the capability to flash the MIL
00 - Slow Flash (1 Hz, 50 % duty cycle)
01 - Fast Flash (2 Hz or faster, 50% duty cycle)
10 - Class C DTC
11 - Unavailable / Do Not Flash
Note:  State 10 is for WWH OBD discriminatory ...";
CM_ SG_ 2566834689 FlashAmberWarningLamp "This parameter provides the capability to flash the AWL

00 - Slow Flash (1 Hz, 50 % duty cycle)
01 - Fast Flash (2 Hz or faster, 50% duty cycle)
10 - Reserved
11 - Unavailable / Do Not Flash";
CM_ SG_ 2566834689 MalfunctionIndicatorLampStatus "A lamp used to relay only emissions-related trouble code information. This lamp is only illuminated when there is an emission-related trouble code active.
00     Lamp Off
01     Lamp On
10     Short MIL for WWH OBD
11     Not available
Note ...";
CM_ SG_ 2566834689 AmberWarningLampStatus "This lamp is used to relay trouble code information that is reporting a problem with the vehicle system but the vehicle need not be immediately stopped. 

00     Lamp Off
01     Lamp On
10     Reserved
11     Not available";
CM_ SG_ 2566834689 RedStopLampState "This lamp is used to relay trouble code information that is of a severe enough condition that it warrants stopping the vehicle.

00     Lamp Off
01     Lamp On
10     Reserved
11     Not available";
CM_ SG_ 2566834689 ProtectLampStatus "This lamp is used to relay trouble code information that is reporting a problem with a vehicle system that is most probably not electronic subsystem related. For instance, engine coolant temperature is exceeding its prescribed temperature range.
00 ...";
CM_ SG_ 2566834689 DTC5 "Diagnostic Trouble Code";
CM_ SG_ 2566834689 DTC4 "Diagnostic Trouble Code";
CM_ SG_ 2566834689 DTC3 "Diagnostic Trouble Code";
CM_ SG_ 2566834689 DTC2 "Diagnostic Trouble Code";
CM_ SG_ 2566834689 DTC1 "Diagnostic Trouble Code";
CM_ BO_ 2364539905 "Engine related parameters";
CM_ SG_ 2364539905 EngDemandPercentTorque "The requested torque output of the engine by all dynamic internal inputs, including smoke control, noise control and low and high speed governing.";
CM_ SG_ 2364539905 EngStarterMode "There are several phases in a starting action and different reasons why a start cannot take place.
0000 start not requested
0001 starter active, gear not engaged
0010 starter active, gear engaged
0011 start finished; starter not active after ...";
CM_ SG_ 2364539905 SrcAddrssOfCntrllngDvcForEngCtrl "The source address of the SAE J1939 device currently controlling the engine.  It is used to expand the torque mode parameter (see SPN 899) in cases where control is in response to an ECU that is not listed in Table SPN899_A.  Its value may be the ...";
CM_ SG_ 2364539905 EngSpeed "Actual engine speed which is calculated over a minimum crankshaft angle of 720 degrees divided by the number of cylinders.";
CM_ SG_ 2364539905 ActualEngPercentTorque "The calculated output torque of the engine.  The data is transmitted in indicated torque as a percent of reference engine torque (see the engine configuration message, PGN 65251).  The engine percent torque value will not be less than zero and it ...";
CM_ SG_ 2364539905 DriversDemandEngPercentTorque "The requested torque output of the engine by the driver. It is based on input from the following requestors external to the powertrain: operator (via the accelerator pedal), cruise control and/or road speed limit governor. Dynamic commands from ...";
CM_ SG_ 2364539905 ActlEngPrcntTorqueHighResolution "This parameter displays an additional torque in percent of the reference engine torque.
When the MSB is set to 1, this parameter is not available.  When the MSB is set to 0, bits 1 to 3 indicate the desired torque with resolution of 0.125%/bit  ...";
CM_ SG_ 2364539905 EngTorqueMode "State signal which indicates which engine torque mode is currently generating, limiting, or controlling the torque.  Note that the modes are not in prioritized order. Not all modes may be relevant for a given device.  Some devices may not implement ...";
CM_ BO_ 2364473089 "Message used to claim an address for a Controller Application.";
CM_ SG_ 2364473089 IndustryGroup "0 = Global; 
   1  = On-Highway; 
   2  = Agricultural and Forestry; 
   3  = Construction; 
   4  = Marine;
   5  = Industrial - Process
          Control - Stationary (Gen-Sets)
   6  = Reserve for SAE
   7  = Reserve for SAE";
CM_ SG_ 2364473089 ManufacturerCode "Assigned by NMEA 2000 Committee";
CM_ BO_ 2364145746 "This message type, identified by the PGN, provides the capability to request information globally or from a specific destination.";
CM_ SG_ 2364145746 ParameterGroupNumber "Whenever it is necessary to identify a Parameter Group in the data field of a CAN data frame, it will be expressed in 24 bits.  The Parameter Group Number is a 24 bit value that has the following constituent components:  Reserved bit, Data Page bit, ...";
CM_ BO_ 2566804736 "Gaseous Fuel Properties";
CM_ SG_ 2566804736 FuelEnergyContent "Energy content (lower heating value) of the gaseous fuel.
Note:  For gaseous fuels, the fuel's energy content (lower heating value) is commonly defined in terms of energy / volume. The gas volume is defined for regular pressure and temperature ...";
CM_ SG_ 2566804736 ReferenceEngGasMassFlowRate "Configuration of the mass flow rate of gaseous fuel expected for 100% engine fuel valve control command.
Note:  The actuator will request this parameter from the ECU in order to determine what mass fuel flow to associate with a command of 100% from ...";
CM_ SG_ 2566804736 SpecificHeatRatio "The specific heat ratio of the fuel.";
CM_ BO_ 2633936640 "Fuel Consumption (Gaseous)";
CM_ SG_ 2633936640 TotalFuelUsed "Total fuel consumed (trip drive fuel + trip PTO governor moving fuel + trip PTO governor non-moving fuel + trip idle fuel) over the life of the engine.";
CM_ SG_ 2633936640 TripFuel "Total fuel consumed (trip drive fuel + trip PTO governor moving fuel + trip PTO governor non-moving fuel + trip idle fuel) since the last trip reset.";
CM_ BO_ 2566749952 "Contains static information about the engine.  To be used with data that will not change during vehicle operation.
.";
CM_ SG_ 2566749952 EngConfigIdentification "Used to identify the hardware configuration of engine family. Each number will have a reference to set of parameters such as, but not limited to, number of cylinders, piston displacement, bore size and firing angles.";
CM_ SG_ 2566749952 NmbrOfCmbstionCyclesForAveraging "Defined number of combustion cycles used for calculating average parameters of combustion in each cylinder.";
CM_ SG_ 2566749952 MaxCrankAttemptsPerStartAttempt "The number of cranking cycles that will be performed before ending the start attempt.  This is intended to be used in conjunction with Crank Attempt Count on Present Start Attempt, in order to give a FMI 0 diagnostic on the latter.";
CM_ BO_ 2566841088 "This map describes the stationary behavior of the engine and the speed dependent available indicated torque.  This map should reflect the effect of changes due to barometric pressure, engine temperature, and any other stationary changes (sensor ...";
CM_ SG_ 2566841088 SupportTSC1CtrlPurposeGroup4 "This parameter indicates which TSC1 control purposes are supported in group 4 of 4. One bit is used to convey the support of each Control Purpose. A value of 0 equals supported and a value of 1 equals not supported. This bit logic is used to allow ...";
CM_ SG_ 2566841088 SupportTSC1CtrlPurposeGroup3 "This parameter indicates which TSC1 control purposes are supported in group 3 of 4. One bit is used to convey the support of each Control Purpose. A value of 0 equals supported and a value of 1 equals not supported. This bit logic is used to allow ...";
CM_ SG_ 2566841088 SupportTSC1CtrlPurposeGroup2 "This parameter indicates which TSC1 control purposes are supported in group 2 of 4. One bit is used to convey the support of each Control Purpose. A value of 0 equals supported and a value of 1 equals not supported. This bit logic is used to allow ...";
CM_ SG_ 2566841088 SupportTSC1CtrlPurposeGroup1 "This parameter indicates which TSC1 control purposes are supported in group 1 of 4. One bit is used to convey the support of each Control Purpose. A value of 0 equals supported and a value of 1 equals not supported. This bit logic is used to allow ...";
CM_ SG_ 2566841088 SupportVariableRateTSC1Message "This parameter indicates which TSC1 transmission rates are supported by the engine ECU in addition to the required 10ms transmission rate for temporary powertrain control purposes.
Bit Position      Transmission Rate
1                      1000 ms ...";
CM_ SG_ 2566841088 EngDefaultTorqueLimit "Companion parameter to Transmission Torque Limit (SPN 1845).  This “echo” parameter provides confirmation to the transmission that the engine has received and will invoke the requested Transmission Torque Limit in the event that J1939 communication ...";
CM_ SG_ 2566841088 EngMomentOfInertia "Moment of inertia for the engine, including items driven full-time by the engine such as fuel, oil and cooling pumps.  The inertia from the following items are not included: flywheel, alternator, compressor, fan, and other engine-driven accessories.";
CM_ SG_ 2566841088 EngExRngRqstdSpdCtrlRngUpprLimit "The maximum engine speed regardless of load that the engine will allow when operating in a speed control/limit mode, excluding any maximum momentary engine override speed, if supported.
When the limit is higher than 2500 RPM the 'Requested Speed ...";
CM_ SG_ 2566841088 EngRqstdTrqueCtrlRangeUpperLimit "The maximum engine torque that the engine will allow when operating in a torque control/limit mode.";
CM_ SG_ 2566841088 EngRqstdTrqueCtrlRangeLowerLimit "The minimum engine torque that the engine will allow when operating in a torque control/limit mode.";
CM_ SG_ 2566841088 EngRqstdSpeedCtrlRangeUpperLimit "The maximum engine speed regardless of load that the engine will allow when operating in a speed control/limit mode, excluding any maximum momentary engine override speed, if supported.";
CM_ SG_ 2566841088 EngRqstdSpeedCtrlRangeLowerLimit "The minimum engine speed that the engine will allow when operating in a speed control/limit mode.";
CM_ SG_ 2566841088 EngMaxMomentaryOverrideTimeLimit "The maximum time limit allowed to override the engine's high idle speed.";
CM_ SG_ 2566841088 EngMxMmentaryOverrideSpeedPoint7 "The maximum engine speed above high idle allowed by the engine control during a momentary high idle override.  This duration of the override is limited by the maximum momentary override time limit, SPN 534.";
CM_ SG_ 2566841088 EngReferenceTorque "This parameter is the 100% reference value for all defined indicated engine torque parameters.  It is only defined once and doesn't change if a different engine torque map becomes valid.";
CM_ SG_ 2566841088 EngGain "The endspeed governor is defined as a linear line with the following equations (Capital letters mean physical values, small letters mean normalized values).  Refer to Figures PGN65251_A and PGN65251_B.
The gain KP/kp is defined as a positive value ...";
CM_ SG_ 2566841088 EngSpeedAtHighIdlePoint6 "Engine speed of high idle (point 6) of the engine torque map (see PGN 65251 and supporting document).  In engine configuration mode 3 (see Figure PGN65251_C), point 6 is not defined by the engine torque map but by the governor characteristic and the ...";
CM_ SG_ 2566841088 EngPercentTorqueAtPoint5 "The torque limit that indicates the available engine torque which can be provided by the engine at point 3, 4, and 5 of the engine map (see PGN 65251 and supporting documents).  It is required that one of these points indicate the peak torque point ...";
CM_ SG_ 2566841088 EngSpeedAtPoint5 "Engine speed of point 3, 4, and 5 of the engine torque map (see PGN 65251 and supporting document).  It is recommended that one of these points indicate the peak torque point for the current engine torque map.  Points 3, 4, and 5 are optional and ...";
CM_ SG_ 2566841088 EngPercentTorqueAtPoint4 "The torque limit that indicates the available engine torque which can be provided by the engine at point 3, 4, and 5 of the engine map (see PGN 65251 and supporting documents).  It is required that one of these points indicate the peak torque point ...";
CM_ SG_ 2566841088 EngSpeedAtPoint4 "Engine speed of point 3, 4, and 5 of the engine torque map (see PGN 65251 and supporting document).  It is recommended that one of these points indicate the peak torque point for the current engine torque map.  Points 3, 4, and 5 are optional and ...";
CM_ SG_ 2566841088 EngPercentTorqueAtPoint3 "The torque limit that indicates the available engine torque which can be provided by the engine at point 3, 4, and 5 of the engine map (see PGN 65251 and supporting documents)..  It is required that one of these points indicate the peak torque point ...";
CM_ SG_ 2566841088 EngSpeedAtPoint3 "Engine speed of point 3, 4, and 5 of the engine torque map (see PGN 65251 and supporting document).  It is recommended that one of these points indicate the peak torque point for the current engine torque map.  Points 3, 4, and 5 are optional and ...";
CM_ SG_ 2566841088 EngPercentTorqueAtPoint2 "The torque limit that indicates the available engine torque which can be provided by the engine at point 2 of the engine map (see PGN 65251 and supporting documents).  In engine configuration mode 1 and 3 (see Table PGN65251_A see PGN 65251), point ...";
CM_ SG_ 2566841088 EngSpeedAtPoint2 "Engine speed of point 2 of the engine torque map (see PGN 65251 and supporting document).  In engine configuration mode 1 and 3, point 2 is defined as the kick-in point from which torque is reduced to zero.  In mode 2 (see Table PGN65251_A), there ...";
CM_ SG_ 2566841088 EngPercentTorqueAtIdlePoint1 "The torque limit that indicates the available engine torque which can be provided by the engine at idle speed.  This parameter may be influenced by engine temperature (after power up) and other stationary changes (calibration offsets, sensor ...";
CM_ SG_ 2566841088 EngSpeedAtIdlePoint1 "Stationary low idle speed of engine which includes influences due to engine temperature (after power up) and other stationary changes (calibration offsets, sensor failures, etc).  This parameter is point 1 of the engine configuration map (see PGN ...";
CM_ BO_ 2566763602 "The purpose of this PGN is to group the aftertreatment intake gas temperature messages for bank 1.";
CM_ SG_ 2566763602 AT1DslPrtcltFltrIntkTmpPrlmnryFM "Used to identify the applicable J1939-73 FMI detected in the diesel particulate filter intake temperature sensor by the manufacturer’s sensor control software in exhaust bank 1.  When there is no failure FMI 31 is sent.  In the case of multiple ...";
CM_ SG_ 2566763602 AT1ExhaustTemp1PreliminaryFMI "Used to identify the applicable J1939-73 FMI detected in the exhaust temperature 1 sensor by the manufacturer’s sensor control software in exhaust bank 1.  When there is no failure FMI 31 is sent.  In the case of multiple failures the most severe is ...";
CM_ SG_ 2566763602 AT1DslPrticulateFilterIntakeTemp "Temperature of engine combustion byproducts entering the diesel particulate filter in exhaust bank 1.";
CM_ SG_ 2566763602 AT1ExhaustTemp1 "The reading from the exhaust temperature sensor located farthest upstream in the aftertreatment system in exhaust bank 1.";
CM_ BO_ 2565869138 "The purpose of this PGN is to group the aftertreatment intake sensor data for bank 1.  These values include the NOx, %O2 , Status's of the sensors with respect to the power being supplied and the heating element, errors and stability of the ...";
CM_ SG_ 2565869138 AT1IntkNOxSnsrSlfdiagnosisStatus "Self-diagnosis result status for NOx sensor ATI1 (Aftertreatment Intake Bank 1)
000 Diagnosis not active
001 NOx Sensor ATI1 Self Diagnosis active flag
010 NOx Sensor ATI1 Self Diagnosis Result Complete
011 NOx Sensor ATI1 Self Diagnosis aborted
 ...";
CM_ SG_ 2565869138 AT1IntakeO2SensorPreliminaryFMI "Used to identify the applicable J1939-73 FMI detected in the aftertreatment intake oxygen sensor by the manufacturer’s sensor control software in exhaust bank 1.  When there is no failure FMI 31 is sent.  In the case of multiple failures the most ...";
CM_ SG_ 2565869138 AT1SCRIntkNOxSnsorPreliminaryFMI "Used to identify the applicable J1939-73 FMI detected in the aftertreatment intake NOx sensor by the manufacturer’s sensor control software in exhaust bank 1.  When there is no failure FMI 31 is sent.  In the case of multiple failures the most ...";
CM_ SG_ 2565869138 AT1IntakeGasSensorHeaterCtrl "Indicates the heater status in the warm-up process.  Upon receiving a power-up command, the gas sensor ramps up according to a manufacturer defined profile.  The Preheat 1, Preheat 2, and Automatic messages are regions within this profile in exhaust ...";
CM_ SG_ 2565869138 AT1IntkGsSnsrHaterPreliminaryFMI "Used to identify the applicable J1939-73 FMI detected in the heater of the intake exhaust gas sensor, either NOx or O2, by the manufacturer’s sensor control software in exhaust bank 1.  When there is no failure FMI 31 is sent.  In the case of ...";
CM_ SG_ 2565869138 AT1IntkWdRngPrcntO2ReadingStable "Indicates that the %O2 reading of the aftertreatment intake gas sensor, either NOx or O2, is stable as determined by the manufacturer's control software in exhaust bank 1.

00 - Not stable
01 - Stable
10 - Error
11 - Not available";
CM_ SG_ 2565869138 AT1SCRIntakeNOxReadingStable "Indicates that the NOx reading of the aftertreatment intake NOx sensor is stable as determined by the manufacturer’s control software in exhaust bank 1.

00 - Not stable
01 - Stable
10 - Error
11 - Not available";
CM_ SG_ 2565869138 AT1IntakeGasSensorAtTemp "Indicates that the heater element of the aftertreatment intake gas sensor, either NOx or O2, is within the manufacturer’s specified range for accurate measurements in exhaust bank 1.
00 - Not in range
01 - In range
10 - Error
11 - Not available
 ...";
CM_ SG_ 2565869138 AT1IntakeGasSensorPowerInRange "Indicates that the power supplied to the aftertreatment intake gas sensor, either NOx or O2, is within the manufacturer’s specification in exhaust bank 1.  This parameter reports the status as reported by the sensor.
00 - Not in range
01 - In ...";
CM_ SG_ 2565869138 AT1IntakePercentO2 "The actual oxidation factor (%O2) of the gas within the exhaust stream.  For positive values, the parameter represents the percent oxygen in excess of the amount required for stoichiometric combustion.  For negative values, the parameter is ...";
CM_ SG_ 2565869138 AT1SCRIntakeNOx "The amount of combined NO and NO2 in the exhaust entering the aftertreatment system measured by a NOx sensor at the aftertreatment intake, represented in NOx molecule parts per million non-NOx molecules in exhaust bank 1.
SPN 3216 shall display the ...";
CM_ BO_ 2566670674 "Contains information about the history of the aftertreatment 1 system";
CM_ SG_ 2566670674 AT1SCRSystmAvrgDstncBtwnSystmCln "Indicates the average distance since last reset between cleaning events for the SCR system in bank 1.

If the manufacturer allows this parameter to be reset, this distance is the average since last reset.";
CM_ SG_ 2566670674 AT1SCRSystmAvrgTmBtwnSystmClnngE "Indicates the average time since last reset between cleaning events for the SCR system in bank 1.
 
If the manufacturer allows this parameter to be reset, this time is the average since last reset.";
CM_ SG_ 2566670674 AT1SCRSystmTtlNmbrOfSystmClnngMn "Total number of manual cleaning requests on the SCR system in bank 1 by the operator over the lifetime of the device.";
CM_ SG_ 2566670674 AT1SCRSystmTtlNmbrOfSystmClnngIn "Total number of cleaning inhibit requests on the SCR system in bank 1 by the operator over the lifetime of the device.";
CM_ SG_ 2566670674 AT1SCRSystmTtlNmbrOfSystmClnngEv "Total number of cleaning events that have occurred on the SCR system in bank 1 over the lifetime of the device.";
CM_ SG_ 2566670674 AT1SCRSystemTotalCleaningTime "Total amount of time that a cleaning event has been active in the SCR system in bank 1 over the lifetime of the device.";
CM_ BO_ 2566756434 "Contains information about the history of the aftertreatment 1 system";
CM_ SG_ 2566756434 AT1DslPrtcltFltrAvrgDstncBtwnAct "Indicates the average distance since last reset between active regenerations, that have not been forced to occur by manual request, for aftertreatment device 1.
If the manufacturer allows this parameter to be reset, this distance is the average ...";
CM_ SG_ 2566756434 AT1DslPrtcltFltrAvrgTmBtwnActvRg "Indicates the average time since last reset between active regenerations, that have not been forced to occur by manual request, for Aftertreatment device 1.
If the manufacturer allows this parameter to be reset, this time is the average since last ...";
CM_ SG_ 2566756434 AT1DslPrtcltFltrTtlNmbrOfAct3728 "Total number of aftertreatment device 1 active regeneration manual requests by the operator over the lifetime of the device.";
CM_ SG_ 2566756434 AT1DslPrtcltFltrTtlNmbrOfActvRgn "Total number of aftertreatment device 1 active regeneration inhibit requests by the operator over the lifetime of the device.";
CM_ SG_ 2566756434 AT1DslPrtcltFltrTtlNmbrOfPssvRgn "Total number of passive regenerations by aftertreatment device 1 over the lifetime of the device.";
CM_ SG_ 2566756434 AT1DslPrtcltFltrTtlPssvRgnrtnTme "Total amount of time that aftertreatment 1 diesel particulate filter has been in passive regeneration over the lifetime of the device.";
CM_ SG_ 2566756434 AT1TtlNmberOfActiveRegenerations "Total number of active regenerations by aftertreatment device 1 over the lifetime of the device.";
CM_ SG_ 2566756434 AT1TotalDisabledTime "Total amount of time that aftertreatment 1 regeneration has been manually disabled.";
CM_ SG_ 2566756434 AT1TotalRegenerationTime "Total amount of time that aftertreatment device 1 has been regenerating over the lifetime of the device.";
CM_ SG_ 2566756434 AT1TotalFuelUsed "Total amount of fuel used by aftertreatment device 1 over the lifetime of the device.";
CM_ BO_ 2566843904 "Engine Temperature 1";
CM_ SG_ 2566843904 EngIntercoolerThermostatOpening "The current position of the thermostat used to regulate the temperature of the engine charge air cooler.  A value of 0% represents the thermostat being completely closed and 100% represents the thermostat being completely open.";
CM_ SG_ 2566843904 EngIntercoolerTemp "Temperature of liquid found in the intercooler located after the turbocharger.";
CM_ SG_ 2566843904 EngTurboOilTemp "Temperature of the turbocharger lubricant.";
CM_ SG_ 2566843904 EngOilTemp1 "Temperature of the engine lubricant.
Note:  If there is only one engine oil temperature measurement, this SPN should be used.  This is the SPN that is typically displayed on an on-highway truck instrument cluster.
See also SPNs 1135 and 5925 for ...";
CM_ SG_ 2566843904 EngFuelTemp1 "Temperature of fuel (or gas) passing through the first fuel control system.  See SPN 3468 for the second control system";
CM_ SG_ 2566843904 EngCoolantTemp "Temperature of liquid found in engine cooling system.";
CM_ BO_ 2364539904 "Engine related parameters";
CM_ SG_ 2364539904 EngDemandPercentTorque "The requested torque output of the engine by all dynamic internal inputs, including smoke control, noise control and low and high speed governing.";
CM_ SG_ 2364539904 EngStarterMode "There are several phases in a starting action and different reasons why a start cannot take place.
0000 start not requested
0001 starter active, gear not engaged
0010 starter active, gear engaged
0011 start finished; starter not active after ...";
CM_ SG_ 2364539904 SrcAddrssOfCntrllngDvcForEngCtrl "The source address of the SAE J1939 device currently controlling the engine.  It is used to expand the torque mode parameter (see SPN 899) in cases where control is in response to an ECU that is not listed in Table SPN899_A.  Its value may be the ...";
CM_ SG_ 2364539904 EngSpeed "Actual engine speed which is calculated over a minimum crankshaft angle of 720 degrees divided by the number of cylinders.";
CM_ SG_ 2364539904 ActualEngPercentTorque "The calculated output torque of the engine.  The data is transmitted in indicated torque as a percent of reference engine torque (see the engine configuration message, PGN 65251).  The engine percent torque value will not be less than zero and it ...";
CM_ SG_ 2364539904 DriversDemandEngPercentTorque "The requested torque output of the engine by the driver. It is based on input from the following requestors external to the powertrain: operator (via the accelerator pedal), cruise control and/or road speed limit governor. Dynamic commands from ...";
CM_ SG_ 2364539904 ActlEngPrcntTorqueHighResolution "This parameter displays an additional torque in percent of the reference engine torque.
When the MSB is set to 1, this parameter is not available.  When the MSB is set to 0, bits 1 to 3 indicate the desired torque with resolution of 0.125%/bit  ...";
CM_ SG_ 2364539904 EngTorqueMode "State signal which indicates which engine torque mode is currently generating, limiting, or controlling the torque.  Note that the modes are not in prioritized order. Not all modes may be relevant for a given device.  Some devices may not implement ...";
CM_ BO_ 2566834770 "Active Diagnostic Trouble Codes";
CM_ SG_ 2566834770 FlashRedStopLamp "This parameter provides the capability to flash the RSL


00 - Slow Flash (1 Hz, 50 % duty cycle)
01 - Fast Flash (2 Hz or faster, 50% duty cycle)
10 - Reserved
11 - Unavailable / Do Not Flash";
CM_ SG_ 2566834770 FlashProtectLamp "This parameter provides the capability to flash the engine protect lamp


00 - Slow Flash (1 Hz, 50 % duty cycle)
01 - Fast Flash (2 Hz or faster, 50% duty cycle)
10 - Reserved
11 - Unavailable / Do Not Flash";
CM_ SG_ 2566834770 FlashMalfuncIndicatorLamp "This parameter provides the capability to flash the MIL
00 - Slow Flash (1 Hz, 50 % duty cycle)
01 - Fast Flash (2 Hz or faster, 50% duty cycle)
10 - Class C DTC
11 - Unavailable / Do Not Flash
Note:  State 10 is for WWH OBD discriminatory ...";
CM_ SG_ 2566834770 FlashAmberWarningLamp "This parameter provides the capability to flash the AWL

00 - Slow Flash (1 Hz, 50 % duty cycle)
01 - Fast Flash (2 Hz or faster, 50% duty cycle)
10 - Reserved
11 - Unavailable / Do Not Flash";
CM_ SG_ 2566834770 MalfunctionIndicatorLampStatus "A lamp used to relay only emissions-related trouble code information. This lamp is only illuminated when there is an emission-related trouble code active.
00     Lamp Off
01     Lamp On
10     Short MIL for WWH OBD
11     Not available
Note ...";
CM_ SG_ 2566834770 AmberWarningLampStatus "This lamp is used to relay trouble code information that is reporting a problem with the vehicle system but the vehicle need not be immediately stopped. 

00     Lamp Off
01     Lamp On
10     Reserved
11     Not available";
CM_ SG_ 2566834770 RedStopLampState "This lamp is used to relay trouble code information that is of a severe enough condition that it warrants stopping the vehicle.

00     Lamp Off
01     Lamp On
10     Reserved
11     Not available";
CM_ SG_ 2566834770 ProtectLampStatus "This lamp is used to relay trouble code information that is reporting a problem with a vehicle system that is most probably not electronic subsystem related. For instance, engine coolant temperature is exceeding its prescribed temperature range.
00 ...";
CM_ SG_ 2566834770 DTC3 "Diagnostic Trouble Code";
CM_ SG_ 2566834770 DTC2 "Diagnostic Trouble Code";
CM_ SG_ 2566834770 DTC1 "Diagnostic Trouble Code";
CM_ BO_ 2566834699 "Active Diagnostic Trouble Codes";
CM_ SG_ 2566834699 FlashRedStopLamp "This parameter provides the capability to flash the RSL


00 - Slow Flash (1 Hz, 50 % duty cycle)
01 - Fast Flash (2 Hz or faster, 50% duty cycle)
10 - Reserved
11 - Unavailable / Do Not Flash";
CM_ SG_ 2566834699 FlashProtectLamp "This parameter provides the capability to flash the engine protect lamp


00 - Slow Flash (1 Hz, 50 % duty cycle)
01 - Fast Flash (2 Hz or faster, 50% duty cycle)
10 - Reserved
11 - Unavailable / Do Not Flash";
CM_ SG_ 2566834699 FlashMalfuncIndicatorLamp "This parameter provides the capability to flash the MIL
00 - Slow Flash (1 Hz, 50 % duty cycle)
01 - Fast Flash (2 Hz or faster, 50% duty cycle)
10 - Class C DTC
11 - Unavailable / Do Not Flash
Note:  State 10 is for WWH OBD discriminatory ...";
CM_ SG_ 2566834699 FlashAmberWarningLamp "This parameter provides the capability to flash the AWL

00 - Slow Flash (1 Hz, 50 % duty cycle)
01 - Fast Flash (2 Hz or faster, 50% duty cycle)
10 - Reserved
11 - Unavailable / Do Not Flash";
CM_ SG_ 2566834699 MalfunctionIndicatorLampStatus "A lamp used to relay only emissions-related trouble code information. This lamp is only illuminated when there is an emission-related trouble code active.
00     Lamp Off
01     Lamp On
10     Short MIL for WWH OBD
11     Not available
Note ...";
CM_ SG_ 2566834699 AmberWarningLampStatus "This lamp is used to relay trouble code information that is reporting a problem with the vehicle system but the vehicle need not be immediately stopped. 

00     Lamp Off
01     Lamp On
10     Reserved
11     Not available";
CM_ SG_ 2566834699 RedStopLampState "This lamp is used to relay trouble code information that is of a severe enough condition that it warrants stopping the vehicle.

00     Lamp Off
01     Lamp On
10     Reserved
11     Not available";
CM_ SG_ 2566834699 ProtectLampStatus "This lamp is used to relay trouble code information that is reporting a problem with a vehicle system that is most probably not electronic subsystem related. For instance, engine coolant temperature is exceeding its prescribed temperature range.
00 ...";
CM_ SG_ 2566834699 DTC1 "Diagnostic Trouble Code";
CM_ BO_ 2566834691 "Active Diagnostic Trouble Codes";
CM_ SG_ 2566834691 FlashRedStopLamp "This parameter provides the capability to flash the RSL


00 - Slow Flash (1 Hz, 50 % duty cycle)
01 - Fast Flash (2 Hz or faster, 50% duty cycle)
10 - Reserved
11 - Unavailable / Do Not Flash";
CM_ SG_ 2566834691 FlashProtectLamp "This parameter provides the capability to flash the engine protect lamp


00 - Slow Flash (1 Hz, 50 % duty cycle)
01 - Fast Flash (2 Hz or faster, 50% duty cycle)
10 - Reserved
11 - Unavailable / Do Not Flash";
CM_ SG_ 2566834691 FlashMalfuncIndicatorLamp "This parameter provides the capability to flash the MIL
00 - Slow Flash (1 Hz, 50 % duty cycle)
01 - Fast Flash (2 Hz or faster, 50% duty cycle)
10 - Class C DTC
11 - Unavailable / Do Not Flash
Note:  State 10 is for WWH OBD discriminatory ...";
CM_ SG_ 2566834691 FlashAmberWarningLamp "This parameter provides the capability to flash the AWL

00 - Slow Flash (1 Hz, 50 % duty cycle)
01 - Fast Flash (2 Hz or faster, 50% duty cycle)
10 - Reserved
11 - Unavailable / Do Not Flash";
CM_ SG_ 2566834691 MalfunctionIndicatorLampStatus "A lamp used to relay only emissions-related trouble code information. This lamp is only illuminated when there is an emission-related trouble code active.
00     Lamp Off
01     Lamp On
10     Short MIL for WWH OBD
11     Not available
Note ...";
CM_ SG_ 2566834691 AmberWarningLampStatus "This lamp is used to relay trouble code information that is reporting a problem with the vehicle system but the vehicle need not be immediately stopped. 

00     Lamp Off
01     Lamp On
10     Reserved
11     Not available";
CM_ SG_ 2566834691 RedStopLampState "This lamp is used to relay trouble code information that is of a severe enough condition that it warrants stopping the vehicle.

00     Lamp Off
01     Lamp On
10     Reserved
11     Not available";
CM_ SG_ 2566834691 ProtectLampStatus "This lamp is used to relay trouble code information that is reporting a problem with a vehicle system that is most probably not electronic subsystem related. For instance, engine coolant temperature is exceeding its prescribed temperature range.
00 ...";
CM_ SG_ 2566834691 DTC1 "Diagnostic Trouble Code";
CM_ BO_ 2566834688 "Active Diagnostic Trouble Codes";
CM_ SG_ 2566834688 FlashRedStopLamp "This parameter provides the capability to flash the RSL


00 - Slow Flash (1 Hz, 50 % duty cycle)
01 - Fast Flash (2 Hz or faster, 50% duty cycle)
10 - Reserved
11 - Unavailable / Do Not Flash";
CM_ SG_ 2566834688 FlashProtectLamp "This parameter provides the capability to flash the engine protect lamp


00 - Slow Flash (1 Hz, 50 % duty cycle)
01 - Fast Flash (2 Hz or faster, 50% duty cycle)
10 - Reserved
11 - Unavailable / Do Not Flash";
CM_ SG_ 2566834688 FlashMalfuncIndicatorLamp "This parameter provides the capability to flash the MIL
00 - Slow Flash (1 Hz, 50 % duty cycle)
01 - Fast Flash (2 Hz or faster, 50% duty cycle)
10 - Class C DTC
11 - Unavailable / Do Not Flash
Note:  State 10 is for WWH OBD discriminatory ...";
CM_ SG_ 2566834688 FlashAmberWarningLamp "This parameter provides the capability to flash the AWL

00 - Slow Flash (1 Hz, 50 % duty cycle)
01 - Fast Flash (2 Hz or faster, 50% duty cycle)
10 - Reserved
11 - Unavailable / Do Not Flash";
CM_ SG_ 2566834688 MalfunctionIndicatorLampStatus "A lamp used to relay only emissions-related trouble code information. This lamp is only illuminated when there is an emission-related trouble code active.
00     Lamp Off
01     Lamp On
10     Short MIL for WWH OBD
11     Not available
Note ...";
CM_ SG_ 2566834688 AmberWarningLampStatus "This lamp is used to relay trouble code information that is reporting a problem with the vehicle system but the vehicle need not be immediately stopped. 

00     Lamp Off
01     Lamp On
10     Reserved
11     Not available";
CM_ SG_ 2566834688 RedStopLampState "This lamp is used to relay trouble code information that is of a severe enough condition that it warrants stopping the vehicle.

00     Lamp Off
01     Lamp On
10     Reserved
11     Not available";
CM_ SG_ 2566834688 ProtectLampStatus "This lamp is used to relay trouble code information that is reporting a problem with a vehicle system that is most probably not electronic subsystem related. For instance, engine coolant temperature is exceeding its prescribed temperature range.
00 ...";
CM_ SG_ 2566834688 DTC5 "Diagnostic Trouble Code";
CM_ SG_ 2566834688 DTC4 "Diagnostic Trouble Code";
CM_ SG_ 2566834688 DTC3 "Diagnostic Trouble Code";
CM_ SG_ 2566834688 DTC2 "Diagnostic Trouble Code";
CM_ SG_ 2566834688 DTC1 "Diagnostic Trouble Code";
CM_ BO_ 2348875267 "NOTE - Retarder may be disabled by commanding a torque limit of 0%.  Use of the limit mode allows the use of the retarder only up to the limit specified in the request.  This can be used to permit retarding of up to 50%, for example, if that limit ...";
CM_ SG_ 2348875267 MessageChecksum "The message checksum is used to verify the signal path from the transmitting device to the receiving device.
The message checksum is calculated using the first 7 data bytes, the message counter and the bytes of the message identifier. It is ...";
CM_ SG_ 2348875267 MessageCounter "The message counter is used to detect situations where the transmitting ECU malfunction repeats the same frame all the time.  The receiver of the information may use the counter parameter to detect this situation.  The transmitting device will ...";
CM_ SG_ 2348875267 EngRequestedTorqueHighResolution "This parameter displays an additional torque in percent of the reference engine torque.
When the MSB is set to 1, this parameter is not available.  When the MSB is set to 0, bits 1 to 3 indicate the desired torque with resolution of 0.125%/bit  ...";
CM_ SG_ 2348875267 TSC1CtrlPurpose "State signal which indicates which control mode the sending device is using to generate the TSC1 command.  Note that the modes are not in prioritized order. Not all modes may be relevant for a given device. Some devices may not implement all ...";
CM_ SG_ 2348875267 TSC1TransRate "This parameter indicates the transmission rate at which the sending device will transmit the TSC1 message.  The engine shall adjust its timeout for TSC1 messages accordingly. Variable TSC1 transmission rates shall only apply to messages sent to the ...";
CM_ SG_ 2348875267 EngRequestedTorque_TorqueLimit "Parameter provided to the engine or retarder in the torque/speed control message for controlling or limiting the output torque.
Requested torque to the engine is measured in indicated torque as a percentage of reference engine torque (see the ...";
CM_ SG_ 2348875267 EngRequestedSpeed_SpeedLimit "Parameter provided to the engine from external sources in the torque/speed control message.  This is the engine speed which the engine is expected to operate at if the speed control mode is active or the engine speed which the engine is not expected ...";
CM_ SG_ 2348875267 OverrideCtrlModePriority "This field is used as an input to the engine or retarder to determine the priority of the Override Control Mode received in the Torque/Speed Control message (see PGN 0).  The default is 11 (Low priority).  It is not required to use the same priority ...";
CM_ SG_ 2348875267 EngRequestedSpeedCtrlConditions "This mode tells the engine control system the governor characteristics that are desired during speed control.  The four characteristics defined are:
00 Transient Optimized for driveline disengaged and non-lockup conditions
01 Stability Optimized ...";
CM_ SG_ 2348875267 EngOverrideCtrlMode "The override control mode defines which sort of command is used:
00 Override disabled - Disable any existing control commanded by the source of this command.
01 Speed control - Govern speed to the included “desired speed” value.
10 Torque control ...";
CM_ BO_ 2348875275 "NOTE - Retarder may be disabled by commanding a torque limit of 0%.  Use of the limit mode allows the use of the retarder only up to the limit specified in the request.  This can be used to permit retarding of up to 50%, for example, if that limit ...";
CM_ SG_ 2348875275 MessageChecksum "The message checksum is used to verify the signal path from the transmitting device to the receiving device.
The message checksum is calculated using the first 7 data bytes, the message counter and the bytes of the message identifier. It is ...";
CM_ SG_ 2348875275 MessageCounter "The message counter is used to detect situations where the transmitting ECU malfunction repeats the same frame all the time.  The receiver of the information may use the counter parameter to detect this situation.  The transmitting device will ...";
CM_ SG_ 2348875275 EngRequestedTorqueHighResolution "This parameter displays an additional torque in percent of the reference engine torque.
When the MSB is set to 1, this parameter is not available.  When the MSB is set to 0, bits 1 to 3 indicate the desired torque with resolution of 0.125%/bit  ...";
CM_ SG_ 2348875275 TSC1CtrlPurpose "State signal which indicates which control mode the sending device is using to generate the TSC1 command.  Note that the modes are not in prioritized order. Not all modes may be relevant for a given device. Some devices may not implement all ...";
CM_ SG_ 2348875275 TSC1TransRate "This parameter indicates the transmission rate at which the sending device will transmit the TSC1 message.  The engine shall adjust its timeout for TSC1 messages accordingly. Variable TSC1 transmission rates shall only apply to messages sent to the ...";
CM_ SG_ 2348875275 EngRequestedTorque_TorqueLimit "Parameter provided to the engine or retarder in the torque/speed control message for controlling or limiting the output torque.
Requested torque to the engine is measured in indicated torque as a percentage of reference engine torque (see the ...";
CM_ SG_ 2348875275 EngRequestedSpeed_SpeedLimit "Parameter provided to the engine from external sources in the torque/speed control message.  This is the engine speed which the engine is expected to operate at if the speed control mode is active or the engine speed which the engine is not expected ...";
CM_ SG_ 2348875275 OverrideCtrlModePriority "This field is used as an input to the engine or retarder to determine the priority of the Override Control Mode received in the Torque/Speed Control message (see PGN 0).  The default is 11 (Low priority).  It is not required to use the same priority ...";
CM_ SG_ 2348875275 EngRequestedSpeedCtrlConditions "This mode tells the engine control system the governor characteristics that are desired during speed control.  The four characteristics defined are:
00 Transient Optimized for driveline disengaged and non-lockup conditions
01 Stability Optimized ...";
CM_ SG_ 2348875275 EngOverrideCtrlMode "The override control mode defines which sort of command is used:
00 Override disabled - Disable any existing control commanded by the source of this command.
01 Speed control - Govern speed to the included “desired speed” value.
10 Torque control ...";
CM_ BO_ 2364473091 "Message used to claim an address for a Controller Application.";
CM_ SG_ 2364473091 IndustryGroup "0 = Global; 
   1  = On-Highway; 
   2  = Agricultural and Forestry; 
   3  = Construction; 
   4  = Marine;
   5  = Industrial - Process
          Control - Stationary (Gen-Sets)
   6  = Reserve for SAE
   7  = Reserve for SAE";
CM_ SG_ 2364473091 ManufacturerCode "Assigned by NMEA 2000 Committee";
CM_ BO_ 2364473088 "Message used to claim an address for a Controller Application.";
CM_ SG_ 2364473088 IndustryGroup "0 = Global; 
   1  = On-Highway; 
   2  = Agricultural and Forestry; 
   3  = Construction; 
   4  = Marine;
   5  = Industrial - Process
          Control - Stationary (Gen-Sets)
   6  = Reserve for SAE
   7  = Reserve for SAE";
CM_ SG_ 2364473088 ManufacturerCode "Assigned by NMEA 2000 Committee";
CM_ BO_ 2364473099 "Message used to claim an address for a Controller Application.";
CM_ SG_ 2364473099 IndustryGroup "0 = Global; 
   1  = On-Highway; 
   2  = Agricultural and Forestry; 
   3  = Construction; 
   4  = Marine;
   5  = Industrial - Process
          Control - Stationary (Gen-Sets)
   6  = Reserve for SAE
   7  = Reserve for SAE";
CM_ SG_ 2364473099 ManufacturerCode "Assigned by NMEA 2000 Committee";
BA_DEF_ SG_  "SigType" ENUM  "Default","Range","RangeSigned","ASCII","Discrete","Control","ReferencePGN","DTC","StringDelimiter","StringLength","StringLengthControl","MessageCounter","MessageChecksum";
BA_DEF_ SG_  "GenSigStartValue" INT 0 10000;
BA_DEF_ SG_  "GenSigSendType" ENUM  "Cyclic","OnWrite","OnWriteWithRepetition","OnChange","OnChangeWithRepetition","IfActive","IfActiveWithRepetition","NoSigSendType";
BA_DEF_ SG_  "GenSigILSupport" ENUM  "No","Yes";
BA_DEF_ SG_  "GenSigEVName" STRING ;
BA_DEF_ SG_  "SPN" INT 0 524287;
BA_DEF_ BO_  "TpJ1939VarDlc" ENUM  "No","Yes";
BA_DEF_ BO_  "GenMsgStartDelayTime" INT 0 100000;
BA_DEF_ BO_  "GenMsgILSupport" ENUM  "No","Yes";
BA_DEF_ BO_  "GenMsgDelayTime" INT 0 1000;
BA_DEF_ BO_  "GenMsgRequestable" INT 0 1;
BA_DEF_ BO_  "GenMsgSendType" ENUM  "cyclic","NotUsed","NotUsed","NotUsed","NotUsed","NotUsed","NotUsed","IfActive","noMsgSendType";
BA_DEF_ BO_  "VFrameFormat" ENUM  "StandardCAN","ExtendedCAN","reserved","J1939PG";
BA_DEF_ BO_  "GenMsgCycleTime" INT 0 3600000;
BA_DEF_ BU_  "NodeLayerModules" STRING ;
BA_DEF_ BU_  "NmStationAddress" INT 0 255;
BA_DEF_ BU_  "NmJ1939IndustryGroup" INT 0 7;
BA_DEF_ BU_  "NmJ1939Function" INT 0 255;
BA_DEF_ BU_  "NmJ1939FunctionInstance" INT 0 7;
BA_DEF_ BU_  "NmJ1939ECUInstance" INT 0 3;
BA_DEF_ BU_  "NmJ1939ManufacturerCode" INT 0 2047;
BA_DEF_ BU_  "NmJ1939IdentityNumber" INT 0 2097151;
BA_DEF_  "SAE_J1939_DA_SpecVersion" STRING ;
BA_DEF_  "SAE_J1939_81_SpecVersion" STRING ;
BA_DEF_  "DatabaseVersion" STRING ;
BA_DEF_  "BusType" STRING ;
BA_DEF_  "ProtocolType" STRING ;
BA_DEF_  "SAE_J1939_75_SpecVersion" STRING ;
BA_DEF_  "SAE_J1939_21_SpecVersion" STRING ;
BA_DEF_  "SAE_J1939_73_SpecVersion" STRING ;
BA_DEF_  "SAE_J1939_71_SpecVersion" STRING ;
BA_DEF_ SG_  "SystemSignalLongSymbol" STRING ;
BA_DEF_DEF_  "SigType" "Default";
BA_DEF_DEF_  "GenSigStartValue" 0;
BA_DEF_DEF_  "GenSigSendType" "NoSigSendType";
BA_DEF_DEF_  "GenSigILSupport" "Yes";
BA_DEF_DEF_  "GenSigEVName" "Env@Nodename_@Signame";
BA_DEF_DEF_  "SPN" 0;
BA_DEF_DEF_  "TpJ1939VarDlc" "No";
BA_DEF_DEF_  "GenMsgStartDelayTime" 0;
BA_DEF_DEF_  "GenMsgILSupport" "Yes";
BA_DEF_DEF_  "GenMsgDelayTime" 0;
BA_DEF_DEF_  "GenMsgRequestable" 1;
BA_DEF_DEF_  "GenMsgSendType" "noMsgSendType";
BA_DEF_DEF_  "VFrameFormat" "J1939PG";
BA_DEF_DEF_  "GenMsgCycleTime" 0;
BA_DEF_DEF_  "NodeLayerModules" "J1939_IL.dll";
BA_DEF_DEF_  "NmStationAddress" 254;
BA_DEF_DEF_  "NmJ1939IndustryGroup" 0;
BA_DEF_DEF_  "NmJ1939Function" 0;
BA_DEF_DEF_  "NmJ1939FunctionInstance" 0;
BA_DEF_DEF_  "NmJ1939ECUInstance" 0;
BA_DEF_DEF_  "NmJ1939ManufacturerCode" 0;
BA_DEF_DEF_  "NmJ1939IdentityNumber" 0;
BA_DEF_DEF_  "SAE_J1939_DA_SpecVersion" "";
BA_DEF_DEF_  "SAE_J1939_81_SpecVersion" "";
BA_DEF_DEF_  "DatabaseVersion" "";
BA_DEF_DEF_  "BusType" "";
BA_DEF_DEF_  "ProtocolType" "";
BA_DEF_DEF_  "SAE_J1939_75_SpecVersion" "";
BA_DEF_DEF_  "SAE_J1939_21_SpecVersion" "";
BA_DEF_DEF_  "SAE_J1939_73_SpecVersion" "";
BA_DEF_DEF_  "SAE_J1939_71_SpecVersion" "";
BA_DEF_DEF_  "SystemSignalLongSymbol" "";
BA_ "SAE_J1939_71_SpecVersion" "2012-10";
BA_ "SAE_J1939_73_SpecVersion" "2012-10";
BA_ "SAE_J1939_21_SpecVersion" "2006-10";
BA_ "SAE_J1939_75_SpecVersion" "2012-05";
BA_ "ProtocolType" "J1939";
BA_ "BusType" "CAN";
BA_ "DatabaseVersion" "8.2 SP3";
BA_ "SAE_J1939_81_SpecVersion" "2012-05";
BA_ "SAE_J1939_DA_SpecVersion" "2014-07";
BA_ "NmStationAddress" BU_ Engine2 1;
BA_ "NmJ1939IndustryGroup" BU_ Engine2 1;
BA_ "NmJ1939ManufacturerCode" BU_ Engine2 1861;
BA_ "NmJ1939IdentityNumber" BU_ Engine2 23221;
BA_ "NmJ1939ECUInstance" BU_ Aftertreatment_1_GasOutlet 1;
BA_ "NmJ1939Function" BU_ Aftertreatment_1_GasOutlet 68;
BA_ "NmStationAddress" BU_ Aftertreatment_1_GasOutlet 82;
BA_ "NmJ1939Function" BU_ BrakesSystemController 9;
BA_ "NmStationAddress" BU_ BrakesSystemController 11;
BA_ "NmJ1939Function" BU_ Transmission1 3;
BA_ "NmStationAddress" BU_ Transmission1 3;
BA_ "NmStationAddress" BU_ Engine1 0;
BA_ "NmJ1939ManufacturerCode" BU_ Engine1 1861;
BA_ "NmJ1939IdentityNumber" BU_ Engine1 122143;
BA_ "GenMsgCycleTime" BO_ 2566834689 1000;
BA_ "GenMsgSendType" BO_ 2566834689 0;
BA_ "GenMsgCycleTime" BO_ 2364539905 100;
BA_ "GenMsgSendType" BO_ 2364539905 0;
BA_ "GenMsgRequestable" BO_ 2364145746 0;
BA_ "GenMsgSendType" BO_ 2566841088 0;
BA_ "GenMsgCycleTime" BO_ 2566841088 5000;
BA_ "GenMsgCycleTime" BO_ 2566763602 500;
BA_ "GenMsgSendType" BO_ 2566763602 0;
BA_ "GenMsgCycleTime" BO_ 2565869138 50;
BA_ "GenMsgSendType" BO_ 2565869138 0;
BA_ "GenMsgCycleTime" BO_ 2566843904 1000;
BA_ "GenMsgSendType" BO_ 2566843904 0;
BA_ "GenMsgCycleTime" BO_ 2364539904 100;
BA_ "GenMsgSendType" BO_ 2364539904 0;
BA_ "GenMsgStartDelayTime" BO_ 2364539904 420;
BA_ "GenMsgCycleTime" BO_ 2566834770 1000;
BA_ "GenMsgStartDelayTime" BO_ 2566834770 60;
BA_ "GenMsgSendType" BO_ 2566834770 0;
BA_ "GenMsgSendType" BO_ 2566834699 0;
BA_ "GenMsgCycleTime" BO_ 2566834699 1000;
BA_ "GenMsgSendType" BO_ 2566834691 0;
BA_ "GenMsgCycleTime" BO_ 2566834691 1000;
BA_ "GenMsgStartDelayTime" BO_ 2566834691 287;
BA_ "GenMsgSendType" BO_ 2566834688 0;
BA_ "GenMsgCycleTime" BO_ 2566834688 1000;
BA_ "GenMsgStartDelayTime" BO_ 2566834688 121;
BA_ "GenMsgCycleTime" BO_ 2348875267 70;
BA_ "GenMsgSendType" BO_ 2348875267 0;
BA_ "GenMsgCycleTime" BO_ 2348875275 110;
BA_ "GenMsgSendType" BO_ 2348875275 0;
BA_ "SPN" SG_ 3221225472 NumberOfMembersInWorkingSet 2409;
BA_ "SigType" SG_ 3221225472 NumberOfMembersInWorkingSet 3;
BA_ "SPN" SG_ 3221225472 NncntnuslyMonitoredSystemsStatus 1223;
BA_ "SPN" SG_ 3221225472 NncntnslyMonitoredSystemsSupport 1222;
BA_ "SPN" SG_ 3221225472 CntnslyMntrdSystmsSupport_Status 1221;
BA_ "SPN" SG_ 3221225472 AETCTorqueValue 3561;
BA_ "SigType" SG_ 3221225472 AETCTorqueValue 1;
BA_ "SPN" SG_ 3221225472 TrailerWeight 180;
BA_ "SigType" SG_ 3221225472 TrailerWeight 1;
BA_ "SPN" SG_ 3221225472 ReferenceTirePressSetting 3193;
BA_ "SPN" SG_ 3221225472 ReferenceTirePress 3191;
BA_ "SPN" SG_ 3221225472 TirePressThresholdDetection 2587;
BA_ "SPN" SG_ 3221225472 TireAirLeakageRate 2586;
BA_ "SigType" SG_ 3221225472 TireAirLeakageRate 1;
BA_ "SPN" SG_ 3221225472 CTIWheelEndElectricalFault 1697;
BA_ "SigType" SG_ 3221225472 CTIWheelEndElectricalFault 4;
BA_ "SPN" SG_ 3221225472 CTITireStatus 1698;
BA_ "SigType" SG_ 3221225472 CTITireStatus 4;
BA_ "SPN" SG_ 3221225472 CTIWheelSensorStatus 1699;
BA_ "SigType" SG_ 3221225472 CTIWheelSensorStatus 4;
BA_ "SPN" SG_ 3221225472 TireTemp 242;
BA_ "SigType" SG_ 3221225472 TireTemp 1;
BA_ "SPN" SG_ 3221225472 TirePress 241;
BA_ "SigType" SG_ 3221225472 TirePress 1;
BA_ "SPN" SG_ 3221225472 EngTurningGearEngaged 1206;
BA_ "SigType" SG_ 3221225472 EngTurningGearEngaged 4;
BA_ "SPN" SG_ 3221225472 AETCSpeedValue 3560;
BA_ "SigType" SG_ 3221225472 AETCSpeedValue 1;
BA_ "SigType" SG_ 3221225472 DTC5 7;
BA_ "SigType" SG_ 3221225472 DTC4 7;
BA_ "SigType" SG_ 3221225472 DTC3 7;
BA_ "SigType" SG_ 3221225472 DTC2 7;
BA_ "SPN" SG_ 2566834689 FlashRedStopLamp 3039;
BA_ "SigType" SG_ 2566834689 FlashRedStopLamp 5;
BA_ "SPN" SG_ 2566834689 FlashProtectLamp 3041;
BA_ "SigType" SG_ 2566834689 FlashProtectLamp 5;
BA_ "SPN" SG_ 2566834689 FlashMalfuncIndicatorLamp 3038;
BA_ "SigType" SG_ 2566834689 FlashMalfuncIndicatorLamp 5;
BA_ "SPN" SG_ 2566834689 FlashAmberWarningLamp 3040;
BA_ "SigType" SG_ 2566834689 FlashAmberWarningLamp 5;
BA_ "SPN" SG_ 2566834689 MalfunctionIndicatorLampStatus 1213;
BA_ "SigType" SG_ 2566834689 MalfunctionIndicatorLampStatus 5;
BA_ "SPN" SG_ 2566834689 AmberWarningLampStatus 624;
BA_ "SigType" SG_ 2566834689 AmberWarningLampStatus 5;
BA_ "SPN" SG_ 2566834689 RedStopLampState 623;
BA_ "SigType" SG_ 2566834689 RedStopLampState 4;
BA_ "SPN" SG_ 2566834689 ProtectLampStatus 987;
BA_ "SigType" SG_ 2566834689 ProtectLampStatus 5;
BA_ "SigType" SG_ 2566834689 DTC5 7;
BA_ "SigType" SG_ 2566834689 DTC4 7;
BA_ "SigType" SG_ 2566834689 DTC3 7;
BA_ "SigType" SG_ 2566834689 DTC2 7;
BA_ "SigType" SG_ 2566834689 DTC1 7;
BA_ "SPN" SG_ 2364539905 EngDemandPercentTorque 2432;
BA_ "SigType" SG_ 2364539905 EngDemandPercentTorque 1;
BA_ "SPN" SG_ 2364539905 EngStarterMode 1675;
BA_ "SPN" SG_ 2364539905 SrcAddrssOfCntrllngDvcForEngCtrl 1483;
BA_ "SPN" SG_ 2364539905 EngSpeed 190;
BA_ "SigType" SG_ 2364539905 EngSpeed 1;
BA_ "SPN" SG_ 2364539905 ActualEngPercentTorque 513;
BA_ "GenSigStartValue" SG_ 2364539905 ActualEngPercentTorque 125;
BA_ "SigType" SG_ 2364539905 ActualEngPercentTorque 1;
BA_ "SPN" SG_ 2364539905 DriversDemandEngPercentTorque 512;
BA_ "GenSigStartValue" SG_ 2364539905 DriversDemandEngPercentTorque 125;
BA_ "SigType" SG_ 2364539905 DriversDemandEngPercentTorque 1;
BA_ "SPN" SG_ 2364539905 ActlEngPrcntTorqueHighResolution 4154;
BA_ "SPN" SG_ 2364539905 EngTorqueMode 899;
BA_ "SPN" SG_ 2364473089 ArbitraryAddressCapable 2844;
BA_ "SPN" SG_ 2364473089 IndustryGroup 2846;
BA_ "SPN" SG_ 2364473089 VehicleSystemInstance 2843;
BA_ "SPN" SG_ 2364473089 Function 2841;
BA_ "SPN" SG_ 2364473089 FunctionInstance 2839;
BA_ "SPN" SG_ 2364473089 ECUInstance 2840;
BA_ "SPN" SG_ 2364473089 ManufacturerCode 2838;
BA_ "SigType" SG_ 2364473089 ManufacturerCode 1;
BA_ "SPN" SG_ 2364473089 IdentityNumber 2837;
BA_ "SPN" SG_ 2364145746 ParameterGroupNumber 2540;
BA_ "SigType" SG_ 2364145746 ParameterGroupNumber 6;
BA_ "GenSigSendType" SG_ 2364145746 ParameterGroupNumber 1;
BA_ "SPN" SG_ 2566804736 FuelEnergyContent 4245;
BA_ "SigType" SG_ 2566804736 FuelEnergyContent 1;
BA_ "SPN" SG_ 2566804736 ReferenceEngGasMassFlowRate 5684;
BA_ "SigType" SG_ 2566804736 ReferenceEngGasMassFlowRate 1;
BA_ "SPN" SG_ 2566804736 SpecificHeatRatio 1767;
BA_ "SigType" SG_ 2566804736 SpecificHeatRatio 1;
BA_ "SPN" SG_ 2633936640 TotalFuelUsed 1040;
BA_ "SigType" SG_ 2633936640 TotalFuelUsed 1;
BA_ "SPN" SG_ 2633936640 TripFuel 1039;
BA_ "SigType" SG_ 2633936640 TripFuel 1;
BA_ "SPN" SG_ 2566749952 EngConfigIdentification 6395;
BA_ "SigType" SG_ 2566749952 EngConfigIdentification 1;
BA_ "SPN" SG_ 2566749952 NmbrOfCmbstionCyclesForAveraging 6394;
BA_ "GenSigStartValue" SG_ 2566749952 NmbrOfCmbstionCyclesForAveraging 1;
BA_ "SigType" SG_ 2566749952 NmbrOfCmbstionCyclesForAveraging 1;
BA_ "SPN" SG_ 2566749952 MaxCrankAttemptsPerStartAttempt 3670;
BA_ "SigType" SG_ 2566749952 MaxCrankAttemptsPerStartAttempt 1;
BA_ "SPN" SG_ 2566841088 SupportTSC1CtrlPurposeGroup4 3348;
BA_ "SPN" SG_ 2566841088 SupportTSC1CtrlPurposeGroup3 3347;
BA_ "SPN" SG_ 2566841088 SupportTSC1CtrlPurposeGroup2 3346;
BA_ "SPN" SG_ 2566841088 SupportTSC1CtrlPurposeGroup1 3345;
BA_ "SPN" SG_ 2566841088 SupportVariableRateTSC1Message 3344;
BA_ "SPN" SG_ 2566841088 EngDefaultTorqueLimit 1846;
BA_ "SigType" SG_ 2566841088 EngDefaultTorqueLimit 1;
BA_ "SPN" SG_ 2566841088 EngMomentOfInertia 1794;
BA_ "SigType" SG_ 2566841088 EngMomentOfInertia 1;
BA_ "SPN" SG_ 2566841088 EngExRngRqstdSpdCtrlRngUpprLimit 1712;
BA_ "SigType" SG_ 2566841088 EngExRngRqstdSpdCtrlRngUpprLimit 1;
BA_ "SPN" SG_ 2566841088 EngRqstdTrqueCtrlRangeUpperLimit 538;
BA_ "GenSigStartValue" SG_ 2566841088 EngRqstdTrqueCtrlRangeUpperLimit 125;
BA_ "SigType" SG_ 2566841088 EngRqstdTrqueCtrlRangeUpperLimit 1;
BA_ "SPN" SG_ 2566841088 EngRqstdTrqueCtrlRangeLowerLimit 537;
BA_ "GenSigStartValue" SG_ 2566841088 EngRqstdTrqueCtrlRangeLowerLimit 125;
BA_ "SigType" SG_ 2566841088 EngRqstdTrqueCtrlRangeLowerLimit 1;
BA_ "SPN" SG_ 2566841088 EngRqstdSpeedCtrlRangeUpperLimit 536;
BA_ "SigType" SG_ 2566841088 EngRqstdSpeedCtrlRangeUpperLimit 1;
BA_ "SPN" SG_ 2566841088 EngRqstdSpeedCtrlRangeLowerLimit 535;
BA_ "SigType" SG_ 2566841088 EngRqstdSpeedCtrlRangeLowerLimit 1;
BA_ "SPN" SG_ 2566841088 EngMaxMomentaryOverrideTimeLimit 534;
BA_ "SigType" SG_ 2566841088 EngMaxMomentaryOverrideTimeLimit 1;
BA_ "SPN" SG_ 2566841088 EngMxMmentaryOverrideSpeedPoint7 533;
BA_ "SigType" SG_ 2566841088 EngMxMmentaryOverrideSpeedPoint7 1;
BA_ "SPN" SG_ 2566841088 EngReferenceTorque 544;
BA_ "SigType" SG_ 2566841088 EngReferenceTorque 1;
BA_ "SPN" SG_ 2566841088 EngGain 545;
BA_ "SigType" SG_ 2566841088 EngGain 1;
BA_ "SPN" SG_ 2566841088 EngSpeedAtHighIdlePoint6 532;
BA_ "SigType" SG_ 2566841088 EngSpeedAtHighIdlePoint6 1;
BA_ "SPN" SG_ 2566841088 EngPercentTorqueAtPoint5 543;
BA_ "GenSigStartValue" SG_ 2566841088 EngPercentTorqueAtPoint5 125;
BA_ "SigType" SG_ 2566841088 EngPercentTorqueAtPoint5 1;
BA_ "SPN" SG_ 2566841088 EngSpeedAtPoint5 531;
BA_ "SigType" SG_ 2566841088 EngSpeedAtPoint5 1;
BA_ "SPN" SG_ 2566841088 EngPercentTorqueAtPoint4 542;
BA_ "GenSigStartValue" SG_ 2566841088 EngPercentTorqueAtPoint4 125;
BA_ "SigType" SG_ 2566841088 EngPercentTorqueAtPoint4 1;
BA_ "SPN" SG_ 2566841088 EngSpeedAtPoint4 530;
BA_ "SigType" SG_ 2566841088 EngSpeedAtPoint4 1;
BA_ "SPN" SG_ 2566841088 EngPercentTorqueAtPoint3 541;
BA_ "GenSigStartValue" SG_ 2566841088 EngPercentTorqueAtPoint3 125;
BA_ "SigType" SG_ 2566841088 EngPercentTorqueAtPoint3 1;
BA_ "SPN" SG_ 2566841088 EngSpeedAtPoint3 529;
BA_ "SigType" SG_ 2566841088 EngSpeedAtPoint3 1;
BA_ "SPN" SG_ 2566841088 EngPercentTorqueAtPoint2 540;
BA_ "GenSigStartValue" SG_ 2566841088 EngPercentTorqueAtPoint2 125;
BA_ "SigType" SG_ 2566841088 EngPercentTorqueAtPoint2 1;
BA_ "SPN" SG_ 2566841088 EngSpeedAtPoint2 528;
BA_ "SigType" SG_ 2566841088 EngSpeedAtPoint2 1;
BA_ "SPN" SG_ 2566841088 EngPercentTorqueAtIdlePoint1 539;
BA_ "GenSigStartValue" SG_ 2566841088 EngPercentTorqueAtIdlePoint1 125;
BA_ "SigType" SG_ 2566841088 EngPercentTorqueAtIdlePoint1 1;
BA_ "SPN" SG_ 2566841088 EngSpeedAtIdlePoint1 188;
BA_ "SigType" SG_ 2566841088 EngSpeedAtIdlePoint1 1;
BA_ "SPN" SG_ 2566763602 AT1DslPrtcltFltrIntkTmpPrlmnryFM 3244;
BA_ "SPN" SG_ 2566763602 AT1ExhaustTemp1PreliminaryFMI 3243;
BA_ "SPN" SG_ 2566763602 AT1DslPrticulateFilterIntakeTemp 3242;
BA_ "SigType" SG_ 2566763602 AT1DslPrticulateFilterIntakeTemp 1;
BA_ "SPN" SG_ 2566763602 AT1ExhaustTemp1 3241;
BA_ "SigType" SG_ 2566763602 AT1ExhaustTemp1 1;
BA_ "SPN" SG_ 2565869138 AT1IntkNOxSnsrSlfdiagnosisStatus 5714;
BA_ "SPN" SG_ 2565869138 AT1IntakeO2SensorPreliminaryFMI 3225;
BA_ "SPN" SG_ 2565869138 AT1SCRIntkNOxSnsorPreliminaryFMI 3224;
BA_ "SPN" SG_ 2565869138 AT1IntakeGasSensorHeaterCtrl 3223;
BA_ "SigType" SG_ 2565869138 AT1IntakeGasSensorHeaterCtrl 5;
BA_ "SPN" SG_ 2565869138 AT1IntkGsSnsrHaterPreliminaryFMI 3222;
BA_ "SPN" SG_ 2565869138 AT1IntkWdRngPrcntO2ReadingStable 3221;
BA_ "SigType" SG_ 2565869138 AT1IntkWdRngPrcntO2ReadingStable 5;
BA_ "SPN" SG_ 2565869138 AT1SCRIntakeNOxReadingStable 3220;
BA_ "SigType" SG_ 2565869138 AT1SCRIntakeNOxReadingStable 5;
BA_ "SPN" SG_ 2565869138 AT1IntakeGasSensorAtTemp 3219;
BA_ "SigType" SG_ 2565869138 AT1IntakeGasSensorAtTemp 5;
BA_ "SPN" SG_ 2565869138 AT1IntakeGasSensorPowerInRange 3218;
BA_ "SigType" SG_ 2565869138 AT1IntakeGasSensorPowerInRange 5;
BA_ "SPN" SG_ 2565869138 AT1IntakePercentO2 3217;
BA_ "SigType" SG_ 2565869138 AT1IntakePercentO2 1;
BA_ "SPN" SG_ 2565869138 AT1SCRIntakeNOx 3216;
BA_ "SigType" SG_ 2565869138 AT1SCRIntakeNOx 1;
BA_ "SPN" SG_ 2566670674 AT1SCRSystmAvrgDstncBtwnSystmCln 6940;
BA_ "SigType" SG_ 2566670674 AT1SCRSystmAvrgDstncBtwnSystmCln 1;
BA_ "SPN" SG_ 2566670674 AT1SCRSystmAvrgTmBtwnSystmClnngE 6939;
BA_ "SigType" SG_ 2566670674 AT1SCRSystmAvrgTmBtwnSystmClnngE 1;
BA_ "SPN" SG_ 2566670674 AT1SCRSystmTtlNmbrOfSystmClnngMn 6938;
BA_ "SigType" SG_ 2566670674 AT1SCRSystmTtlNmbrOfSystmClnngMn 1;
BA_ "SPN" SG_ 2566670674 AT1SCRSystmTtlNmbrOfSystmClnngIn 6937;
BA_ "SigType" SG_ 2566670674 AT1SCRSystmTtlNmbrOfSystmClnngIn 1;
BA_ "SPN" SG_ 2566670674 AT1SCRSystmTtlNmbrOfSystmClnngEv 6936;
BA_ "SigType" SG_ 2566670674 AT1SCRSystmTtlNmbrOfSystmClnngEv 1;
BA_ "SPN" SG_ 2566670674 AT1SCRSystemTotalCleaningTime 6935;
BA_ "SigType" SG_ 2566670674 AT1SCRSystemTotalCleaningTime 1;
BA_ "SPN" SG_ 2566756434 AT1DslPrtcltFltrAvrgDstncBtwnAct 5827;
BA_ "SigType" SG_ 2566756434 AT1DslPrtcltFltrAvrgDstncBtwnAct 1;
BA_ "SPN" SG_ 2566756434 AT1DslPrtcltFltrAvrgTmBtwnActvRg 5454;
BA_ "SigType" SG_ 2566756434 AT1DslPrtcltFltrAvrgTmBtwnActvRg 1;
BA_ "SPN" SG_ 2566756434 AT1DslPrtcltFltrTtlNmbrOfAct3728 3728;
BA_ "SigType" SG_ 2566756434 AT1DslPrtcltFltrTtlNmbrOfAct3728 1;
BA_ "SPN" SG_ 2566756434 AT1DslPrtcltFltrTtlNmbrOfActvRgn 3727;
BA_ "SigType" SG_ 2566756434 AT1DslPrtcltFltrTtlNmbrOfActvRgn 1;
BA_ "SPN" SG_ 2566756434 AT1DslPrtcltFltrTtlNmbrOfPssvRgn 3726;
BA_ "SigType" SG_ 2566756434 AT1DslPrtcltFltrTtlNmbrOfPssvRgn 1;
BA_ "SPN" SG_ 2566756434 AT1DslPrtcltFltrTtlPssvRgnrtnTme 3725;
BA_ "SigType" SG_ 2566756434 AT1DslPrtcltFltrTtlPssvRgnrtnTme 1;
BA_ "SPN" SG_ 2566756434 AT1TtlNmberOfActiveRegenerations 3525;
BA_ "SigType" SG_ 2566756434 AT1TtlNmberOfActiveRegenerations 1;
BA_ "SPN" SG_ 2566756434 AT1TotalDisabledTime 3524;
BA_ "SigType" SG_ 2566756434 AT1TotalDisabledTime 1;
BA_ "SPN" SG_ 2566756434 AT1TotalRegenerationTime 3523;
BA_ "SigType" SG_ 2566756434 AT1TotalRegenerationTime 1;
BA_ "SPN" SG_ 2566756434 AT1TotalFuelUsed 3522;
BA_ "SigType" SG_ 2566756434 AT1TotalFuelUsed 1;
BA_ "SPN" SG_ 2566843904 EngIntercoolerThermostatOpening 1134;
BA_ "SigType" SG_ 2566843904 EngIntercoolerThermostatOpening 1;
BA_ "SPN" SG_ 2566843904 EngIntercoolerTemp 52;
BA_ "SigType" SG_ 2566843904 EngIntercoolerTemp 1;
BA_ "SPN" SG_ 2566843904 EngTurboOilTemp 176;
BA_ "SigType" SG_ 2566843904 EngTurboOilTemp 1;
BA_ "SPN" SG_ 2566843904 EngOilTemp1 175;
BA_ "SigType" SG_ 2566843904 EngOilTemp1 1;
BA_ "SPN" SG_ 2566843904 EngFuelTemp1 174;
BA_ "SigType" SG_ 2566843904 EngFuelTemp1 1;
BA_ "SPN" SG_ 2566843904 EngCoolantTemp 110;
BA_ "SigType" SG_ 2566843904 EngCoolantTemp 1;
BA_ "SPN" SG_ 2364539904 EngDemandPercentTorque 2432;
BA_ "SigType" SG_ 2364539904 EngDemandPercentTorque 1;
BA_ "SPN" SG_ 2364539904 EngStarterMode 1675;
BA_ "SPN" SG_ 2364539904 SrcAddrssOfCntrllngDvcForEngCtrl 1483;
BA_ "SPN" SG_ 2364539904 EngSpeed 190;
BA_ "SigType" SG_ 2364539904 EngSpeed 1;
BA_ "SPN" SG_ 2364539904 ActualEngPercentTorque 513;
BA_ "GenSigStartValue" SG_ 2364539904 ActualEngPercentTorque 125;
BA_ "SigType" SG_ 2364539904 ActualEngPercentTorque 1;
BA_ "SPN" SG_ 2364539904 DriversDemandEngPercentTorque 512;
BA_ "GenSigStartValue" SG_ 2364539904 DriversDemandEngPercentTorque 125;
BA_ "SigType" SG_ 2364539904 DriversDemandEngPercentTorque 1;
BA_ "SPN" SG_ 2364539904 ActlEngPrcntTorqueHighResolution 4154;
BA_ "SPN" SG_ 2364539904 EngTorqueMode 899;
BA_ "SPN" SG_ 2566834770 FlashRedStopLamp 3039;
BA_ "SigType" SG_ 2566834770 FlashRedStopLamp 5;
BA_ "SPN" SG_ 2566834770 FlashProtectLamp 3041;
BA_ "SigType" SG_ 2566834770 FlashProtectLamp 5;
BA_ "SPN" SG_ 2566834770 FlashMalfuncIndicatorLamp 3038;
BA_ "SigType" SG_ 2566834770 FlashMalfuncIndicatorLamp 5;
BA_ "SPN" SG_ 2566834770 FlashAmberWarningLamp 3040;
BA_ "SigType" SG_ 2566834770 FlashAmberWarningLamp 5;
BA_ "SPN" SG_ 2566834770 MalfunctionIndicatorLampStatus 1213;
BA_ "SigType" SG_ 2566834770 MalfunctionIndicatorLampStatus 5;
BA_ "SPN" SG_ 2566834770 AmberWarningLampStatus 624;
BA_ "SigType" SG_ 2566834770 AmberWarningLampStatus 5;
BA_ "SPN" SG_ 2566834770 RedStopLampState 623;
BA_ "SigType" SG_ 2566834770 RedStopLampState 4;
BA_ "SPN" SG_ 2566834770 ProtectLampStatus 987;
BA_ "SigType" SG_ 2566834770 ProtectLampStatus 5;
BA_ "SigType" SG_ 2566834770 DTC3 7;
BA_ "SigType" SG_ 2566834770 DTC2 7;
BA_ "SigType" SG_ 2566834770 DTC1 7;
BA_ "SPN" SG_ 2566834699 FlashRedStopLamp 3039;
BA_ "SigType" SG_ 2566834699 FlashRedStopLamp 5;
BA_ "SPN" SG_ 2566834699 FlashProtectLamp 3041;
BA_ "SigType" SG_ 2566834699 FlashProtectLamp 5;
BA_ "SPN" SG_ 2566834699 FlashMalfuncIndicatorLamp 3038;
BA_ "SigType" SG_ 2566834699 FlashMalfuncIndicatorLamp 5;
BA_ "SPN" SG_ 2566834699 FlashAmberWarningLamp 3040;
BA_ "SigType" SG_ 2566834699 FlashAmberWarningLamp 5;
BA_ "SPN" SG_ 2566834699 MalfunctionIndicatorLampStatus 1213;
BA_ "SigType" SG_ 2566834699 MalfunctionIndicatorLampStatus 5;
BA_ "SPN" SG_ 2566834699 AmberWarningLampStatus 624;
BA_ "SigType" SG_ 2566834699 AmberWarningLampStatus 5;
BA_ "SPN" SG_ 2566834699 RedStopLampState 623;
BA_ "SigType" SG_ 2566834699 RedStopLampState 4;
BA_ "SPN" SG_ 2566834699 ProtectLampStatus 987;
BA_ "SigType" SG_ 2566834699 ProtectLampStatus 5;
BA_ "SigType" SG_ 2566834699 DTC1 7;
BA_ "SPN" SG_ 2566834691 FlashRedStopLamp 3039;
BA_ "SigType" SG_ 2566834691 FlashRedStopLamp 5;
BA_ "SPN" SG_ 2566834691 FlashProtectLamp 3041;
BA_ "SigType" SG_ 2566834691 FlashProtectLamp 5;
BA_ "SPN" SG_ 2566834691 FlashMalfuncIndicatorLamp 3038;
BA_ "SigType" SG_ 2566834691 FlashMalfuncIndicatorLamp 5;
BA_ "SPN" SG_ 2566834691 FlashAmberWarningLamp 3040;
BA_ "SigType" SG_ 2566834691 FlashAmberWarningLamp 5;
BA_ "SPN" SG_ 2566834691 MalfunctionIndicatorLampStatus 1213;
BA_ "SigType" SG_ 2566834691 MalfunctionIndicatorLampStatus 5;
BA_ "SPN" SG_ 2566834691 AmberWarningLampStatus 624;
BA_ "SigType" SG_ 2566834691 AmberWarningLampStatus 5;
BA_ "SPN" SG_ 2566834691 RedStopLampState 623;
BA_ "SigType" SG_ 2566834691 RedStopLampState 4;
BA_ "SPN" SG_ 2566834691 ProtectLampStatus 987;
BA_ "SigType" SG_ 2566834691 ProtectLampStatus 5;
BA_ "SigType" SG_ 2566834691 DTC1 7;
BA_ "SPN" SG_ 2566834688 FlashRedStopLamp 3039;
BA_ "SigType" SG_ 2566834688 FlashRedStopLamp 5;
BA_ "SPN" SG_ 2566834688 FlashProtectLamp 3041;
BA_ "SigType" SG_ 2566834688 FlashProtectLamp 5;
BA_ "SPN" SG_ 2566834688 FlashMalfuncIndicatorLamp 3038;
BA_ "SigType" SG_ 2566834688 FlashMalfuncIndicatorLamp 5;
BA_ "SPN" SG_ 2566834688 FlashAmberWarningLamp 3040;
BA_ "SigType" SG_ 2566834688 FlashAmberWarningLamp 5;
BA_ "SPN" SG_ 2566834688 MalfunctionIndicatorLampStatus 1213;
BA_ "SigType" SG_ 2566834688 MalfunctionIndicatorLampStatus 5;
BA_ "SPN" SG_ 2566834688 AmberWarningLampStatus 624;
BA_ "SigType" SG_ 2566834688 AmberWarningLampStatus 5;
BA_ "SPN" SG_ 2566834688 RedStopLampState 623;
BA_ "SigType" SG_ 2566834688 RedStopLampState 4;
BA_ "SPN" SG_ 2566834688 ProtectLampStatus 987;
BA_ "SigType" SG_ 2566834688 ProtectLampStatus 5;
BA_ "SigType" SG_ 2566834688 DTC5 7;
BA_ "SigType" SG_ 2566834688 DTC4 7;
BA_ "SigType" SG_ 2566834688 DTC3 7;
BA_ "SigType" SG_ 2566834688 DTC2 7;
BA_ "SigType" SG_ 2566834688 DTC1 7;
BA_ "SPN" SG_ 2348875267 MessageChecksum 4207;
BA_ "SigType" SG_ 2348875267 MessageChecksum 12;
BA_ "SPN" SG_ 2348875267 MessageCounter 4206;
BA_ "SigType" SG_ 2348875267 MessageCounter 11;
BA_ "SPN" SG_ 2348875267 EngRequestedTorqueHighResolution 4191;
BA_ "SPN" SG_ 2348875267 TSC1CtrlPurpose 3350;
BA_ "SPN" SG_ 2348875267 TSC1TransRate 3349;
BA_ "SPN" SG_ 2348875267 EngRequestedTorque_TorqueLimit 518;
BA_ "SigType" SG_ 2348875267 EngRequestedTorque_TorqueLimit 1;
BA_ "SPN" SG_ 2348875267 EngRequestedSpeed_SpeedLimit 898;
BA_ "SigType" SG_ 2348875267 EngRequestedSpeed_SpeedLimit 1;
BA_ "SPN" SG_ 2348875267 OverrideCtrlModePriority 897;
BA_ "SigType" SG_ 2348875267 OverrideCtrlModePriority 5;
BA_ "SPN" SG_ 2348875267 EngRequestedSpeedCtrlConditions 696;
BA_ "SigType" SG_ 2348875267 EngRequestedSpeedCtrlConditions 5;
BA_ "SPN" SG_ 2348875267 EngOverrideCtrlMode 695;
BA_ "SigType" SG_ 2348875267 EngOverrideCtrlMode 5;
BA_ "SPN" SG_ 2348875275 MessageChecksum 4207;
BA_ "SigType" SG_ 2348875275 MessageChecksum 12;
BA_ "SPN" SG_ 2348875275 MessageCounter 4206;
BA_ "SigType" SG_ 2348875275 MessageCounter 11;
BA_ "SPN" SG_ 2348875275 EngRequestedTorqueHighResolution 4191;
BA_ "SPN" SG_ 2348875275 TSC1CtrlPurpose 3350;
BA_ "SPN" SG_ 2348875275 TSC1TransRate 3349;
BA_ "SPN" SG_ 2348875275 EngRequestedTorque_TorqueLimit 518;
BA_ "SigType" SG_ 2348875275 EngRequestedTorque_TorqueLimit 1;
BA_ "SPN" SG_ 2348875275 EngRequestedSpeed_SpeedLimit 898;
BA_ "SigType" SG_ 2348875275 EngRequestedSpeed_SpeedLimit 1;
BA_ "SPN" SG_ 2348875275 OverrideCtrlModePriority 897;
BA_ "SigType" SG_ 2348875275 OverrideCtrlModePriority 5;
BA_ "SPN" SG_ 2348875275 EngRequestedSpeedCtrlConditions 696;
BA_ "SigType" SG_ 2348875275 EngRequestedSpeedCtrlConditions 5;
BA_ "SPN" SG_ 2348875275 EngOverrideCtrlMode 695;
BA_ "SigType" SG_ 2348875275 EngOverrideCtrlMode 5;
BA_ "SPN" SG_ 2364473091 ArbitraryAddressCapable 2844;
BA_ "SPN" SG_ 2364473091 IndustryGroup 2846;
BA_ "SPN" SG_ 2364473091 VehicleSystemInstance 2843;
BA_ "SPN" SG_ 2364473091 Function 2841;
BA_ "SPN" SG_ 2364473091 FunctionInstance 2839;
BA_ "SPN" SG_ 2364473091 ECUInstance 2840;
BA_ "SPN" SG_ 2364473091 ManufacturerCode 2838;
BA_ "SigType" SG_ 2364473091 ManufacturerCode 1;
BA_ "SPN" SG_ 2364473091 IdentityNumber 2837;
BA_ "SPN" SG_ 2364473088 ArbitraryAddressCapable 2844;
BA_ "SPN" SG_ 2364473088 IndustryGroup 2846;
BA_ "SPN" SG_ 2364473088 VehicleSystemInstance 2843;
BA_ "SPN" SG_ 2364473088 Function 2841;
BA_ "SPN" SG_ 2364473088 FunctionInstance 2839;
BA_ "SPN" SG_ 2364473088 ECUInstance 2840;
BA_ "SPN" SG_ 2364473088 ManufacturerCode 2838;
BA_ "SigType" SG_ 2364473088 ManufacturerCode 1;
BA_ "SPN" SG_ 2364473088 IdentityNumber 2837;
BA_ "SPN" SG_ 2364473099 ArbitraryAddressCapable 2844;
BA_ "SPN" SG_ 2364473099 IndustryGroup 2846;
BA_ "SPN" SG_ 2364473099 VehicleSystemInstance 2843;
BA_ "SPN" SG_ 2364473099 Function 2841;
BA_ "SPN" SG_ 2364473099 FunctionInstance 2839;
BA_ "SPN" SG_ 2364473099 ECUInstance 2840;
BA_ "SPN" SG_ 2364473099 ManufacturerCode 2838;
BA_ "SigType" SG_ 2364473099 ManufacturerCode 1;
BA_ "SPN" SG_ 2364473099 IdentityNumber 2837;
VAL_ 3221225472 TirePressThresholdDetection 7 "Not available" 6 "Error indicator" 5 "Not defined" 4 "Extreme under pressure  The tire pressure is at a level where the safety of the vehicle may be jeopardised" 3 "Under pressure  The tire pressure is lower than the pressure defined by the vehicle or tire manufacturer" 2 "No warning pressure  The tire pressure is within the thresholds defined by the vehicle or tire manufacturer" 1 "Over pressure  The tire pressure is higher than the pressure defined by the vehicle or tire manufacturer" 0 "Extreme over pressure  The tire pressure is at a level where the safety of the vehicle may be jeopardised" ;
VAL_ 3221225472 CTIWheelEndElectricalFault 3 "Not Supported" 2 "Error" 1 "Not Defined" 0 "Ok  No Fault" ;
VAL_ 3221225472 CTITireStatus 3 "Not Supported" 2 "Error" 1 "Tire leak detected" 0 "Ok no fault" ;
VAL_ 3221225472 CTIWheelSensorStatus 3 "Not Supported" 2 "Not Defined" 1 "On tire is polled" 0 "Off / isolated from CTI Pressure Controller" ;
VAL_ 3221225472 EngTurningGearEngaged 1 "Engaged" 0 "Not engaged" 3 "Not available" 2 "Error" ;
VAL_ 2566834689 FlashRedStopLamp 3 "Unavailable / Do Not Flash" 2 "Reserved" 1 "Fast Flash" 0 "Slow Flash" ;
VAL_ 2566834689 FlashProtectLamp 3 "Unavailable / Do Not Flash" 2 "Reserved" 1 "Fast Flash" 0 "Slow Flash" ;
VAL_ 2566834689 FlashMalfuncIndicatorLamp 3 "Unavailable / Do Not Flash" 2 "Reserved" 1 "Fast Flash" 0 "Slow Flash" ;
VAL_ 2566834689 FlashAmberWarningLamp 3 "Unavailable / Do Not Flash" 2 "Reserved" 1 "Fast Flash" 0 "Slow Flash" ;
VAL_ 2566834689 MalfunctionIndicatorLampStatus 3 "Not available" 2 "Reserved" 1 "Lamp on" 0 "Lamp off" ;
VAL_ 2566834689 AmberWarningLampStatus 3 "Not available" 2 "Reserved" 1 "Lamp on" 0 "Lamp off" ;
VAL_ 2566834689 RedStopLampState 3 "Not available" 2 "Reserved" 1 "Lamp on" 0 "Lamp off" ;
VAL_ 2566834689 ProtectLampStatus 3 "Not available" 2 "Reserved" 1 "Lamp on" 0 "Lamp off" ;
VAL_ 2364539905 EngStarterMode 11 "Reserved" 10 "starter inhibited due to active SCR inducement" 9 "starter inhibited due to intake air shutoff valve being active" 13 "error legacy implementation only use 1110" 15 "not available" 14 "error" 12 "starter inhibited  reason unknown" 8 "starter inhibited due to starter overtemp" 7 "starter inhibited due to active immobilizer" 6 "starter inhibited due to driveline engaged or other transmission inhibit" 5 "starter inhibited due to engine not ready for start preheating" 4 "starter inhibited due to engine already running" 3 "start finished starter not active after having been actively engaged after 50ms mode goes to 0000" 2 "starter active gear engaged" 1 "starter active gear not engaged" 0 "start not requested" ;
VAL_ 2364539905 ActlEngPrcntTorqueHighResolution 7 "0875" 1 "0125" 0 "0000" ;
VAL_ 2364473089 IndustryGroup 6 "Reserved for SAE" 7 "Reserved for SAE" 5 "IndustrialProcessCtrlStationary" 4 "Marine" 3 "Construction" 2 "Agricultural and Forestry" 1 "On-Highway" 0 "Global" ;
VAL_ 2364473089 Function 127 "Reserved" 126 "Reserved" 125 "Reserved" 124 "Reserved" 123 "Reserved" 122 "Reserved" 121 "Reserved" 120 "Reserved" 119 "Reserved" 118 "Reserved" 117 "Reserved" 116 "Reserved" 115 "Reserved" 114 "Reserved" 113 "Reserved" 112 "Reserved" 111 "Reserved" 110 "Reserved" 109 "Reserved" 108 "Reserved" 107 "Reserved" 106 "Reserved" 105 "Reserved" 104 "Reserved" 103 "Reserved" 102 "Reserved" 101 "Reserved" 42 "Water Pump Control" 41 "Lighting - Operator Controls" 40 "Seat Control" 39 "Ignition Control Module" 38 "Tire Pressure Control" 37 "Cab Controller" 36 "Pneumatic - System Controller" 35 "Suspension - System Controller" 34 "Hydraulic Pump Controller" 33 "System Monitor" 32 "Headway Controller" 31 "Propulsion Battery Charger" 30 "Management Computer" 29 "Virtual Terminal (in cab)" 28 "Off Vehicle Gateway" 27 "Power TakeOff (Secondary or Front)" 26 "Body Controller" 25 "Network Interconnect ECU" 24 "Vehicle Security" 23 "Vehicle Navigation" 22 "Aerodynamic Control" 21 "Cab Climate Control" 20 "Trip Recorder" 19 "Instrument Cluster" 18 "Suspension - Drive Axle" 17 "Suspension - Steer Axle" 16 "Steering Controller" 15 "Fuel System" 14 "Cruise Control" 13 "Retarder - Driveline" 12 "Retarder - Engine" 11 "Brakes - Drive Axle" 10 "Brakes - Steer Axle" 9 "Brakes - System Controller" 8 "Axle - Drive" 7 "Axle - Steering" 6 "Power TakeOff - (Main or Rear)" 5 "Shift Control/Console" 4 "Battery Pack Monitor" 3 "Transmission" 2 "Electric Propulsion Control" 1 "Auxiliary Power Unit (APU)" 0 "Engine" 100 "Reserved" 99 "Reserved" 98 "Reserved" 97 "Reserved" 96 "Reserved" 95 "Reserved" 94 "Reserved" 93 "Reserved" 92 "Reserved" 91 "Reserved" 90 "Reserved" 89 "Reserved" 88 "Reserved" 87 "Reserved" 86 "Reserved" 85 "Reserved" 84 "Reserved" 83 "Reserved" 82 "Reserved" 81 "Reserved" 80 "Reserved" 79 "Reserved" 78 "Fire Suppression System" 77 "Fuel Properties Sensor" 76 "Temperature Sensor" 75 "Supplemental Fan" 74 "Lubrication System" 73 "Rollover Detection Control" 72 "Coolant Valve Controller" 71 "Transfer Case Control" 70 "Auxiliary Regeneration Device" 69 "Engine Emission Aftertreatement System" 68 "Aftertreatment system gas measurement" 67 "Electrical System Controller" 66 "I/O Controller" 65 "Gas Flow Measurement" 64 "Endurance Braking" 63 "Engine Valve Controller" 62 "On-Board Diagnostic Unit" 61 "File Server/Printer" 60 "Cab Display" 59 "Starter" 58 "Fan Drive Control" 57 "Steering Column Unit" 56 "Communications Unit, Radio" 55 "Communications Unit, Satellite" 54 "Communications Unit, Cellular" 53 "Alternator/Charging System" 52 "Chassis Controller" 51 "Forward-Looking Collision Warning System" 50 "Auxiliary Heater" 49 "Clutch/Converter Control" 48 "Ramp Control" 47 "Information System Controller" 46 "Oil Sensor Unit" 45 "Vehicle Dynamic Stability Control" 44 "Exhaust Emission Control" 43 "Transmission Display" ;
VAL_ 2364473089 ManufacturerCode 454 "NGK Spark Plug Co. Ltd" 453 "Cooper Bussmann" 452 "WIKA Alexander Wiegand SE & Co. KG" 451 "Parker Hannifin Corp" 450 "Dycor Technologies Ltd." 449 "Polaris Industries Inc" 448 "Stanadyne Corporation, Electronics Systems" 447 "Great Plains Mfg." 446 "CertTech, L.L.C." 445 "KAT MECHATRONIC, Electronic Product Division" 444 "ITT Power Solutions" 443 "SignalQuest, Inc." 442 "Horsch Maschinen GmbH" 441 "PTG Reifendruckregelsysteme GmbH" 440 "Cummins Power Generation" 439 "Hyundai Heavy Industries" 438 "Comar Systems Ltd" 437 "Digital Yacht Limited" 436 "Kinze Manufacturing" 435 "Zunhammer GmbH" 434 "Stored Energy Systems" 433 "Rowe Electronics" 432 "S&A Systems, Inc." 431 "Tohatsu Corporation" 430 "Auteq Telematica S.A." 520 "Trapeze" 519 "Peeters Landbouwmachines b.v." 518 "Transas USA Inc." 517 "Noland Engineering" 516 "AVAT Automation GmbH" 515 "GINAF Trucks Nederland B.V." 514 "DISTek Integration, Inc." 513 "FarmscanAg" 512 "Inpower LLC" 511 "Sulky" 510 "Marinesoft Co. Ltd" 509 "MOTORTECH GmbH" 508 "Transtech Innovations" 507 "Test Center ISOBUS" 506 "IHI STAR Machinery Corporation" 505 "Yetter Farm Equipment" 504 "Vesper Marine" 503 "Naviop S.R.L." 502 "Attwood Corporation" 501 "Agrotronix S.A." 500 "Oxbo International Corporation" 499 "LCJ Capteurs" 498 "Innovative Design Solutions, Inc" 497 "SENTRON Sistemas Embarcados" 496 "W. Gessmann GmbH" 495 "HOLMER Maschinenbau GmbH" 494 "Synerject" 493 "Watcheye" 492 "Inergy Automotive Systems" 491 "Penny and Giles Ltd" 490 "QuikQ" 489 "Appareo Systems" 488 "The Charles Machine Works, Inc." 487 "DSE Test Solutions A/S" 486 "Westport Innovations Inc." 485 "MATT automotive" 484 "Headsight Inc." 483 "Valeo" 482 "Tricon Electronics" 481 "Chetco Digital Instruments" 480 "EnerDel, Inc." 479 "Vapor Bus International" 478 "OceanSat BV" 477 "OilQuick AB" 476 "Hummingbird Marine Electronics" 475 "GME" 474 "Persen Technologies Inc." 473 "Boss Industries, Inc." 472 "Tenneco Inc." 471 "Sea Cross Marine AB" 470 "SI-TEX Marine Electronics" 469 "RA Consulting GmbH" 468 "Tyco Fire Protection Products" 467 "Lely Industries N.V." 466 "Veethree Electronics and Marine LLC" 465 "Ashcroft Inc" 464 "Leach International Corporation" 463 "PROBOTIQ" 462 "IHI Shibaura Machinery Corporation" 461 "HAWE Hydraulik SE" 460 "San Giorgio S.E.I.N." 459 "Alltek Marine Electronics Corp" 458 "Control Solutions, Inc." 457 "RUSELPROM-ElectricDrive Ltd" 456 "General Kinetics" 455 "ADZ NAGANO GmbH" 429 "Rota Engineering Ltd." 428 "Mfg_428" 427 "em-trak Marine Electronics Ltd" 426 "Egersund Marine Electronics AS" 425 "Methode Electronics Inc, MDI" 424 "Odyne LLC" 423 "BSM Wireless, Inc." 422 "True Heading AB" 421 "Vertex Standard Co, Ltd" 420 "Vermeer Corporation, ACS Group" 419 "Fusion Electronics Ltd" 418 "Intellistick Inc" 417 "KZValve" 416 "Kubota Corporation" 415 "Valid Manufacturing Ltd." 414 "Cattron Group International" 413 "Datapross Nijbroek bv" 412 "WebTech Wireless Inc." 411 "Hy-Drive Technologies Ltd." 410 "COBO S.p.A. Divisione 3B6" 409 "Transfluid S.r.L." 408 "Corvus Energy Ltd." 407 "Comtech Mobile Datacom" 406 "Vecima Networks Inc." 405 "Wema System AS" 404 "Com Nav Marine Ltd" 403 "Trackwell ADS, Inc." 402 "Simma Software, Inc." 401 "Torqeedo GmbH" 400 "Livorsi Marine" 399 "ISEKI & Co., Ltd." 398 "Hilite International" 397 "Sanyo-kiki Co Ltd." 396 "Beyond Measure" 395 "GENTEC S.R.L." 394 "Capi 2 Nederland BV" 393 "Harvest Tec, Inc" 392 "Tianyuan Technology Co Ltd." 391 "Electronic Design for Industry, Inc" 390 "Partech Inc." 389 "Benchmark Electronics, Minnesota Division" 388 "Innomatix, LLC" 387 "Orscheln Products, LLC" 386 "JLG Automation BVBA" 385 "Johnson Outdoor Marine Electronics" 384 "Camano Light" 383 "MCL Industries" 382 "National Agricultural and Food Research Organization" 380 "Suntech International Ltd." 379 "Yamabiko Corporation" 378 "Glendinning Marine Products" 377 "ifm electronic gmbh" 376 "Quake Global" 375 "Williams Controls Inc." 372 "Delphi" 381 "B&G" 374 "Northern Lights, Inc." 373 "Electronic Design Inc." 371 "Heinzmann GmbH & Co. KG" 370 "Rolls-Royce Marine AS" 369 "Power Torque Engineering Ltd" 368 "HANSENHOF_electronic" 367 "Fliegl Agrartechnik" 366 "Viewnyx Corp." 365 "Digi-Star, LLC" 364 "OEM Controls Inc." 363 "BEI Duncan" 362 "Alois Poettinger Maschinenfabrik GmbH" 361 "InMach" 360 "HJS Emission Technology GmbH & Co KG" 359 "Ludwig Bergmann GmbH" 358 "Victron Energy BV" 357 "Hardi International A/S" 356 "Fischer Panda Generators, Inc" 355 "Mastervolt International B.V." 354 "Junkkari OY" 353 "Hegemon Electronics, Inc." 352 "SAME DEUTZ-FAHR" 351 "Thrane & Thrane" 350 "Noris Marine Systems GmbH & Co KG" 349 "Suonentiet" 348 "Amazonen Werke H. Dreyer" 347 "Honeywell" 346 "Control Solutions" 345 "Korean Maritime University" 344 "Parvus Corporation" 343 "Baumer Group" 342 "THOMAS MAGNETE GmbH" 341 "Boning GmbH & Co" 340 "Continental AG" 339 "Competence Center ISOBUS e.V." 338 "GRAF-SYTECO" 337 "Carraro S.p.A." 336 "APE s.r.o." 335 "Evo Electric Ltd" 334 "Takata-Petri AG" 333 "Hadley Products Corporation" 332 "HWH Corporation" 331 "Horton, Inc." 330 "Kidde Aerospace and Defense" 329 "Deif A/S" 328 "Qwerty Electronik AB" 252 "Sensor-Technik Wiedemann GmbH" 251 "German Agricultural Society" 250 "Kuhn Group" 249 "Schaltbau GmbH" 233 "Yacht Monitoring Solutions Inc." 232 "TSD Integrated Controls" 1863 "Thomas G. Faria Co." 1862 "Sanshin" 1861 "Vector CANtech" 1860 "MMP" 1859 "Kvasar AB" 1858 "Litton" 1857 "Simrad" 1856 "Trimble" 1855 "Furuno USA" 1854 "Northstar Technologies" 1853 "Japan Radio Co." 1852 "Navionics" 1851 "Raymarine" 1850 "Teleflex" 222 "Generac Power Systems, Inc." 221 "SiE" 220 "Beede Electrical Instrument Company, Inc." 219 "Cat OEM Solutions" 218 "Gits Manufacturing Company" 217 "RM Michaelides Software & Elektronik GmbH" 216 "Paneltronics Inc." 215 "Aetna Engineering/Fireboy-Xintex" 214 "MC elettronica Srl" 213 "CNH Belgium N.V." 212 "Sure Power Industries, Inc." 211 "DNA Group" 210 "Iteris, Inc." 209 "Bell Equip. Co. SA (PTY) LTD" 208 "Drew Technologies, Inc." 207 "Otto Engineering" 206 "port GmbH" 205 "SmarTire Systems Inc" 204 "The Morey Corporation" 203 "MILtronik GmbH" 202 "Curtis Instruments, Inc." 201 "Disenos y Tecnologia S.A." 200 "MGM Brakes" 199 "Actia Corp." 198 "Mystic Valley Communications" 197 "Mechron Power Systems" 196 "LEMKEN GmbH & Co. KG" 195 "General Engine Products" 194 "TriMark Corporation" 193 "Nobletec" 192 "Floscan" 191 "XRS Corporation" 190 "Hella KGaA Hueck & Co." 189 "QUALCOMM" 188 "EMP Corp." 187 "Air-Weigh" 186 "Altronic, Inc." 185 "Beede Electrical Instrument Company" 184 "EIA Electronics" 183 "KDS Controls, Inc." 182 "Vehicle Systems Engineering B.V." 181 "Coretronics, Inc." 180 "Smart Power Systems" 179 "TeeJet Technologies Denmark" 178 "Siemens VDO Automotive AG" 177 "Diagnostic System Associates" 176 "Moritz Aerospace" 175 "Veris Technologies, Inc." 174 "AB Volvo Penta" 173 "Ryeso, Inc." 172 "Yanmar Marine USA" 171 "Wachendorff Elektronik GmbH & Co. KG" 170 "Computronics Corporation Ltd." 169 "Marlin Technologies Inc." 168 "Xantrex" 167 "JLG Industries Inc." 166 "Phoenix International" 165 "CPAC Systems AB" 164 "DaimlerChrysler Off-Highway" 163 "BRP Inc." 162 "Axiomatic Technologies" 161 "Offshore Systems (UK) Limited" 160 "Nido" 159 "NTech Industries Inc." 158 "Firestone Industrial Products Company" 157 "ISSPRO Inc." 156 "ITT Industries - Cannon" 155 "Vetronix Corporation" 154 "Westerbeke Corporation" 153 "Woodward, Industrial Controls Division" 152 "elobau GmbH & Co. KG" 151 "Raven Industries Inc. - Flow Controls Division" 150 "Fleetguard" 149 "Holset" 148 "Blue Water Data, Inc." 147 "Nautibus Electronic GmbH" 146 "Maxima Technologies" 145 "MurCal Controls" 144 "Mercury Marine" 143 "W. Gmeiner GmbH & Co." 142 "TRW Automotive (Commercial Steering Systems)" 141 "Thales Navigation Ltd." 140 "Lowrance Electronics, Inc." 139 "Caterpillar Trimble Control Technologies (CTCT), LLC" 138 "Georg Fritzmeier GmbH & Co. KG" 137 "Maretron" 136 "Komatsu Ltd." 135 "Airmar Technology Corporation" 134 "Iris Technology Ltd." 133 "Bucher Schoerling GmbH" 132 "Mulag-Fahrzeugwerk" 131 "ITT Industries" 130 "Nido - Universal Machines B.V." 129 "OMNEX Control Systems, Inc." 128 "Gerhard Duecker GmbH & Co. KG" 127 "Holland USA" 126 "Driver Tech" 125 "Nevada Automotive Test Center" 124 "Hydac Electronic" 123 "Basler Electric" 122 "FG Wilson (Engineering) Limited" 121 "HED (Hydro Electronic Devices, Inc.)" 120 "RDS Technology Ltd." 119 "IntegriNautics" 118 "Intron GmbH" 117 "HUSCO International" 116 "BEELINE Technologies" 115 "NACCO Materials Handling Group, Inc." 114 "EControls, Inc." 113 "Stress-Tek, Inc." 112 "MECALAC" 111 "Maschinenfabrik Bernard Krone GmbH" 110 "EPIQ Sensor-Nite" 109 "TeeJet Technologies Denmark" 108 "WTK-Elecktronik GmbH" 107 "Grimme Landmaschinen GmbH & Co. KG" 106 "BAE Systems Controls, Inc." 105 "Kiepe Elektrik GmbH & Co. KG" 104 "Claas Selbstfahrende Erntemaschinen GmbH" 103 "CLAAS Agrosystems GmbH & Co. KG" 102 "AGCO GmbH & Co." 101 "Sensoria" 100 "VDO Technik AG" 99 "International Transmissions Ltd (ITL)" 98 "Mueller-Elektronik GmbH & Co." 97 "Ag Leader Technology, Inc." 96 "Mech@tronic IT GmbH" 95 "Pacific Insight Electronics Corp." 94 "CNH Global N.V." 93 "Perkins Engines Company Ltd." 92 "Ag-Chem Equipment Co., Inc." 91 "BSG Bodensee Steuergeraete GmbH" 90 "Knorr-Bremse SfN GmbH" 89 "Kverneland Group, Electronics Division" 88 "Satloc Precision GPS" 87 "J.C. Bamford Excavators Ltd (JCB)" 86 "C.E. Niehoff & Company" 85 "Kohler Co." 84 "New Holland UK Limited" 83 "Bendix VORAD Technologies" 82 "Bobcat/Ingersoll-Rand" 81 "Fire Research Corp" 80 "Twin Disc, Inc." 79 "Daimler Benz AG - Engine Division (PBM)" 78 "Frank W. Murphy Manufacturing, Inc." 77 "Deere Power Systems Group" 76 "unused" 75 "Deere & Co. Agricultural Division" 74 "Eaton Axle-Brake Division" 73 "LeTourneau, Inc." 72 "Sisu Corporation" 71 "Vansco Electronics Ltd." 70 "Flex-Coil Limited" 69 "Trimble Navigation" 68 "Scania" 67 "Funk Manufacturing Company" 66 "John Deere Construction Equipment Division" 65 "MAN Nutzfahrzeuge AG" 64 "unused" 63 "ZF Industries Inc." 62 "Wabco" 61 "Volvo Truck Corp." 60 "Volvo Trucks North America Inc." 59 "VES Inc." 58 "SPX Corporation, OTC Division" 57 "Sauer-Danfoss Co." 56 "SAIC" 55 "Ryder System Inc." 54 "Meritor Wabco" 53 "Continental Automotive Systems US, Inc." 52 "Meritor Automotive, Inc." 51 "Robert Bosch GmbH" 50 "Robert Bosch Corp" 49 "RE America Inc." 48 "Pollak Alphabet" 47 "Phillips Semiconductor" 46 "Noregon Systems, Inc" 45 "PACCAR" 44 "Nippondenso Co. Ltd." 43 "International Truck and Engine Corp. Vehicle Electronics" 42 "International Truck and Engine Corp. Engine Electronics" 41 "Motorola Inc." 40 "Motorola AIEG Inc." 39 "Microfirm Inc." 38 "Micro Processor Systems Inc." 37 "Mack Trucks Inc." 36 "Lucas Ltd." 35 "Kenworth Truck Co." 34 "Kelsey Hayes Co." 33 "John Deere" 32 "Jacobs Vehicle Systems" 31 "J Pollak Corp." 30 "Isuzu Motors Ltd." 29 "Hino Motors Ltd." 28 "Grote Ind. Inc." 27 "GMC" 26 "General Motors Corp., Service Technology Group" 25 "Daimler Trucks North America LLC" 24 "Ford Motor Co., Vehicle Controls" 23 "Ford Motor Co., Heavy Truck" 22 "Ford Motor Co., Electronic Concepts $ Systems" 21 "Echilin Inc., Midland Brake Inc." 20 "Eaton Ltd" 19 "Eaton Corp. Trucking Info Services" 18 "Eaton Corp, Transmission Division" 17 "Eaton Corp. Res & Dev" 16 "Eaton Corp." 15 "Dickey-John Corp." 14 "Detroit Diesel Corporation" 13 "Delco Electronics" 12 "Deere & Company, Precision Farming" 11 "Dearborn Group Inc." 10 "Cummins Engine Co." 9 "Chrysler Corp." 8 "Caterpillar Inc." 7 "Case Corp." 6 "Berifors Electronics AB" 5 "AMP Inc." 4 "Ametek-Dixson" 3 "Ametek, US Gauge Division" 2 "Allison Transmission, GMC" 1 "Allied Signal Inc." 0 "Reserved" 231 "Topcon Positioning Systems, Inc." 230 "Saucon Technologies" 229 "Garmin International Inc." 228 "ZF Marine Electronics" 227 "Lykketronic A/S" 226 "Monaco Coach Corporation" 225 "SKF" 224 "EMMI Network, S.L." 223 "Vaueo Retarder Co., Ltd." 263 "IMMI" 262 "HydraForce, Inc" 261 "Red Dot Corporation" 260 "Reichhardt GmbH" 259 "Jetter AG" 258 "ARAG" 257 "Honda Motor Co., Ltd" 256 "Tyco Electronics AMP" 255 "MEAS France" 254 "GE Sensing" 253 "Mobile Control Systems" 298 "Holley Performance" 297 "Zonar Systems Inc" 296 "micro dynamics GmbH" 295 "BEP Marine" 294 "Grayhill Inc." 293 "Spyder Controls Corp." 292 "IKUSI - Angel Iglesias S.A." 291 "Groeneveld Transport Efficiency BV" 290 "Kuebler GmbH" 289 "Watlow" 288 "Mitsubishi FUSO Truck & Bus Corp." 287 "NTech Industries, Inc" 286 "Coelmo srl" 285 "Sea Recovery Corp" 284 "Mobile Tech Chile" 283 "CWF Hamilton & Co Ltd" 282 "Medallion Instrumentation Systems" 281 "Precision Governors LLC" 311 "Patrick Power Products" 310 "TECNORD srl" 309 "Krauss-Maffei Wegmann GmbH & Co. KG" 308 "Cyntrx" 307 "MBW Technologies" 306 "Sleipner Motor AB" 305 "NovAtel Inc" 304 "EmpirBus AB" 303 "CTS Corporation" 302 "Nissin Kogyo Co., LTD" 301 "Parker Hannifin (UK) Ltd FDE group" 300 "Systron Donner Automotive" 299 "Rauch Landmaschinen GmbH" 280 "Leica Geosystems Pty Ltd" 279 "Geometris LP" 278 "Takata Electronics" 277 "LHP Telematics" 276 "Aqua-Hot Heating Systems" 275 "Navico Egersund AS" 274 "LTW Technology Co., LTD" 273 "Active Research Limited" 272 "Gross Mechanical Laboratories, Inc" 327 "Sonceboz SA" 326 "Akron Brass Company" 325 "ASM Automation Sensorik Messtechnik GmbH" 324 "Snap-on Diagnostics" 323 "Mobileye Vision Technologies Ltd." 322 "MICHENKA s.r.o." 321 "Ultra Electronics, Electrics" 320 "Miedema Landbouwwerktuigenfabriek B.V." 319 "Cadec Global" 318 "SAT Plan" 317 "Navtronics Bvba" 316 "ITT Flow Control" 315 "Icom Incorporated" 314 "CSM GmbH" 313 "Ilmor Engineering, Inc" 312 "Lectronix, Inc." 271 "Cole Hersee" 270 "Tennant" 269 "Saft America Inc.,  Space & Defense Division" 268 "Accurate Technologies" 267 "Red Lion Controls, Inc" 266 "International Thermal Research Ltd" 265 "MTS Sensor Technologie GmbH" 264 "Autolync" 248 "Cooper Standard Automotive Active Systems Group" 247 "ePULSE" 246 "Class 1, Inc" 245 "Capstan Ag Systems, Inc." 244 "Techno-Matic" 243 "eRide, Inc." 242 "Kokusandenki Co. Ltd" 241 "Schneider Automation SAS " 240 "Vanair Mfg" 239 "May & Scofield Ltd" 238 "ZF Friedrichshafen AG" 237 "Agtron Enterprises Inc" 236 "Norac Systems International Inc" 235 "SailorMade Marine Telemetry - Tetra Technology Ltd." 234 "Mondial electronic GmbH" ;
VAL_ 2364473089 VehicleSystem 0 "Non-specific System" 127 "Not Available" ;
VAL_ 2364473089 VehicleSystem5 127 "Not Available" 0 "Ind. Process Control Stationary" ;
VAL_ 2364473089 VehicleSystem4 125 "Entertainment" 120 "Display" 85 "External Environment" 75 "Sensor Communication Interface" 35 "Electrical Generation" 100 "Deck, Cargo and Fishing Equipment" 90 "Internal Environment" 80 "Instrumentation/General Systems (deprecate)" 70 "Communications" 60 "Navigation" 50 "Propulsion" 40 "Steering and Control Surfaces" 30 "Electrical Distribution" 25 "Inter/Intranetwork Device" 20 "Safety Systems" 10 "System Tools" 127 "Not Available" 0 "Non-specific System" ;
VAL_ 2364473089 VehicleSystem3 8 "Grader" 7 "Four Wheel Drive Loader" 6 "Forklift" 5 "Excavator" 4 "Crawler" 3 "Backhoe" 2 "Articulated Dump Truck" 1 "Skid Steer Loader" 127 "Not Available" 0 "Non-specific System" ;
VAL_ 2364473089 VehicleSystem2 25 "Slurry Applicators" 24 "Utility Vehicles" 23 "Mulchers" 22 "Timber Processing Machines" 21 "Timber loaders" 20 "Forwarders" 19 "Timber Harvesters" 17 "Sensor Systems" 16 "Skidder" 15 "Earth Work" 14 "Special Crops" 13 "Powered Auxiliary Device" 12 "Farm Yard Operations" 11 "Transport/Trailer" 10 "Irrigation" 9 "Forage" 8 "Root Harvesters" 7 "Harvesters" 6 "Sprayers" 5 "Fertilizers" 4 "Planters/Seeders" 3 "Secondary Tillage" 2 "Tillage" 1 "Tractor" 127 "Not Available" 0 "Non-specific System" ;
VAL_ 2364473089 VehicleSystem1 2 "Trailer" 1 "Tractor" 127 "Not Available" 0 "Non-specific System" ;
VAL_ 2565869138 AT1IntkNOxSnsrSlfdiagnosisStatus 7 "Not Supported" 4 "NOx Sensor ATI1 Self Diagnosis not possible" 3 "NOx Sensor ATI1 Self Diagnosis aborted" 2 "NOx Sensor ATI1 Self Diagnosis Result Complete" 1 "NOx Sensor ATI1 Self Diagnosis active flag" 0 "Diagnosis not active" ;
VAL_ 2565869138 AT1IntakeGasSensorHeaterCtrl 3 "Heater off" 2 "Preheat 1" 1 "Preheat 2" 0 "Automatic" ;
VAL_ 2565869138 AT1IntkWdRngPrcntO2ReadingStable 3 "Not available" 2 "Error" 1 "Stable" 0 "Not stable" ;
VAL_ 2565869138 AT1SCRIntakeNOxReadingStable 3 "Not available" 2 "Error" 1 "Stable" 0 "Not stable" ;
VAL_ 2565869138 AT1IntakeGasSensorAtTemp 3 "Not available" 2 "Error" 1 "In range" 0 "Not in range" ;
VAL_ 2565869138 AT1IntakeGasSensorPowerInRange 3 "Not available" 2 "Error" 1 "In range" 0 "Not in range" ;
VAL_ 2364539904 EngStarterMode 11 "Reserved" 10 "starter inhibited due to active SCR inducement" 9 "starter inhibited due to intake air shutoff valve being active" 13 "error legacy implementation only use 1110" 15 "not available" 14 "error" 12 "starter inhibited  reason unknown" 8 "starter inhibited due to starter overtemp" 7 "starter inhibited due to active immobilizer" 6 "starter inhibited due to driveline engaged or other transmission inhibit" 5 "starter inhibited due to engine not ready for start preheating" 4 "starter inhibited due to engine already running" 3 "start finished starter not active after having been actively engaged after 50ms mode goes to 0000" 2 "starter active gear engaged" 1 "starter active gear not engaged" 0 "start not requested" ;
VAL_ 2364539904 ActlEngPrcntTorqueHighResolution 7 "0875" 1 "0125" 0 "0000" ;
VAL_ 2566834770 FlashRedStopLamp 3 "Unavailable / Do Not Flash" 2 "Reserved" 1 "Fast Flash" 0 "Slow Flash" ;
VAL_ 2566834770 FlashProtectLamp 3 "Unavailable / Do Not Flash" 2 "Reserved" 1 "Fast Flash" 0 "Slow Flash" ;
VAL_ 2566834770 FlashMalfuncIndicatorLamp 3 "Unavailable / Do Not Flash" 2 "Reserved" 1 "Fast Flash" 0 "Slow Flash" ;
VAL_ 2566834770 FlashAmberWarningLamp 3 "Unavailable / Do Not Flash" 2 "Reserved" 1 "Fast Flash" 0 "Slow Flash" ;
VAL_ 2566834770 MalfunctionIndicatorLampStatus 3 "Not available" 2 "Reserved" 1 "Lamp on" 0 "Lamp off" ;
VAL_ 2566834770 AmberWarningLampStatus 3 "Not available" 2 "Reserved" 1 "Lamp on" 0 "Lamp off" ;
VAL_ 2566834770 RedStopLampState 3 "Not available" 2 "Reserved" 1 "Lamp on" 0 "Lamp off" ;
VAL_ 2566834770 ProtectLampStatus 3 "Not available" 2 "Reserved" 1 "Lamp on" 0 "Lamp off" ;
VAL_ 2566834699 FlashRedStopLamp 3 "Unavailable / Do Not Flash" 2 "Reserved" 1 "Fast Flash" 0 "Slow Flash" ;
VAL_ 2566834699 FlashProtectLamp 3 "Unavailable / Do Not Flash" 2 "Reserved" 1 "Fast Flash" 0 "Slow Flash" ;
VAL_ 2566834699 FlashMalfuncIndicatorLamp 3 "Unavailable / Do Not Flash" 2 "Reserved" 1 "Fast Flash" 0 "Slow Flash" ;
VAL_ 2566834699 FlashAmberWarningLamp 3 "Unavailable / Do Not Flash" 2 "Reserved" 1 "Fast Flash" 0 "Slow Flash" ;
VAL_ 2566834699 MalfunctionIndicatorLampStatus 3 "Not available" 2 "Reserved" 1 "Lamp on" 0 "Lamp off" ;
VAL_ 2566834699 AmberWarningLampStatus 3 "Not available" 2 "Reserved" 1 "Lamp on" 0 "Lamp off" ;
VAL_ 2566834699 RedStopLampState 3 "Not available" 2 "Reserved" 1 "Lamp on" 0 "Lamp off" ;
VAL_ 2566834699 ProtectLampStatus 3 "Not available" 2 "Reserved" 1 "Lamp on" 0 "Lamp off" ;
VAL_ 2566834691 FlashRedStopLamp 3 "Unavailable / Do Not Flash" 2 "Reserved" 1 "Fast Flash" 0 "Slow Flash" ;
VAL_ 2566834691 FlashProtectLamp 3 "Unavailable / Do Not Flash" 2 "Reserved" 1 "Fast Flash" 0 "Slow Flash" ;
VAL_ 2566834691 FlashMalfuncIndicatorLamp 3 "Unavailable / Do Not Flash" 2 "Reserved" 1 "Fast Flash" 0 "Slow Flash" ;
VAL_ 2566834691 FlashAmberWarningLamp 3 "Unavailable / Do Not Flash" 2 "Reserved" 1 "Fast Flash" 0 "Slow Flash" ;
VAL_ 2566834691 MalfunctionIndicatorLampStatus 3 "Not available" 2 "Reserved" 1 "Lamp on" 0 "Lamp off" ;
VAL_ 2566834691 AmberWarningLampStatus 3 "Not available" 2 "Reserved" 1 "Lamp on" 0 "Lamp off" ;
VAL_ 2566834691 RedStopLampState 3 "Not available" 2 "Reserved" 1 "Lamp on" 0 "Lamp off" ;
VAL_ 2566834691 ProtectLampStatus 3 "Not available" 2 "Reserved" 1 "Lamp on" 0 "Lamp off" ;
VAL_ 2566834688 FlashRedStopLamp 3 "Unavailable / Do Not Flash" 2 "Reserved" 1 "Fast Flash" 0 "Slow Flash" ;
VAL_ 2566834688 FlashProtectLamp 3 "Unavailable / Do Not Flash" 2 "Reserved" 1 "Fast Flash" 0 "Slow Flash" ;
VAL_ 2566834688 FlashMalfuncIndicatorLamp 3 "Unavailable / Do Not Flash" 2 "Reserved" 1 "Fast Flash" 0 "Slow Flash" ;
VAL_ 2566834688 FlashAmberWarningLamp 3 "Unavailable / Do Not Flash" 2 "Reserved" 1 "Fast Flash" 0 "Slow Flash" ;
VAL_ 2566834688 MalfunctionIndicatorLampStatus 3 "Not available" 2 "Reserved" 1 "Lamp on" 0 "Lamp off" ;
VAL_ 2566834688 AmberWarningLampStatus 3 "Not available" 2 "Reserved" 1 "Lamp on" 0 "Lamp off" ;
VAL_ 2566834688 RedStopLampState 3 "Not available" 2 "Reserved" 1 "Lamp on" 0 "Lamp off" ;
VAL_ 2566834688 ProtectLampStatus 3 "Not available" 2 "Reserved" 1 "Lamp on" 0 "Lamp off" ;
VAL_ 2348875267 EngRequestedTorqueHighResolution 7 "0875" 1 "0125" 0 "0000" ;
VAL_ 2348875267 TSC1CtrlPurpose 31 "P32  Temporary Power Train Control Original use of TSC1 Command" 4 "P5  Engine Protection" 3 "P4  Road Speed Governor" 2 "P3  PTO Governor" 1 "P2  Cruise Control" 0 "P1  Accelerator Pedal/Operator Selection" ;
VAL_ 2348875267 TSC1TransRate 7 "Use standard TSC1 transmission rates of 10 ms to engine" 6 "20 ms transmission rate" 5 "50 ms transmission rate" 4 "100 ms transmission rate" 3 "250 ms transmission rate" 2 "500 ms transmission rate" 1 "750 ms transmission rate" 0 "1000 ms transmission rate" ;
VAL_ 2348875267 OverrideCtrlModePriority 3 "Low priority" 2 "Medium priority" 1 "High priority" 0 "Highest priority" ;
VAL_ 2348875267 EngRequestedSpeedCtrlConditions 2 "Stability Optimized for driveline engaged and/or in lockup condition 1 eg vehicle driveline" 3 "Stability Optimized for driveline engaged and/or in lockup condition 2 eg PTO driveline" 1 "Stability Optimized for driveline disengaged and nonlockup conditions" 0 "Transient Optimized for driveline disengaged and nonlockup conditions" ;
VAL_ 2348875267 EngOverrideCtrlMode 3 "Speed/torque limit control  Limit speed and/or torque based on the included limit values  The speed limit governor is" 2 "Torque control  Control torque to the included desired torque value" 1 "Speed control  Govern speed to the included desired speed value" 0 "Override disabled  Disable any existing control commanded by the source of this command" ;
VAL_ 2348875275 EngRequestedTorqueHighResolution 7 "0875" 1 "0125" 0 "0000" ;
VAL_ 2348875275 TSC1CtrlPurpose 31 "P32  Temporary Power Train Control Original use of TSC1 Command" 4 "P5  Engine Protection" 3 "P4  Road Speed Governor" 2 "P3  PTO Governor" 1 "P2  Cruise Control" 0 "P1  Accelerator Pedal/Operator Selection" ;
VAL_ 2348875275 TSC1TransRate 7 "Use standard TSC1 transmission rates of 10 ms to engine" 6 "20 ms transmission rate" 5 "50 ms transmission rate" 4 "100 ms transmission rate" 3 "250 ms transmission rate" 2 "500 ms transmission rate" 1 "750 ms transmission rate" 0 "1000 ms transmission rate" ;
VAL_ 2348875275 OverrideCtrlModePriority 3 "Low priority" 2 "Medium priority" 1 "High priority" 0 "Highest priority" ;
VAL_ 2348875275 EngRequestedSpeedCtrlConditions 2 "Stability Optimized for driveline engaged and/or in lockup condition 1 eg vehicle driveline" 3 "Stability Optimized for driveline engaged and/or in lockup condition 2 eg PTO driveline" 1 "Stability Optimized for driveline disengaged and nonlockup conditions" 0 "Transient Optimized for driveline disengaged and nonlockup conditions" ;
VAL_ 2348875275 EngOverrideCtrlMode 3 "Speed/torque limit control  Limit speed and/or torque based on the included limit values  The speed limit governor is" 2 "Torque control  Control torque to the included desired torque value" 1 "Speed control  Govern speed to the included desired speed value" 0 "Override disabled  Disable any existing control commanded by the source of this command" ;
VAL_ 2364473091 IndustryGroup 6 "Reserved for SAE" 7 "Reserved for SAE" 5 "IndustrialProcessCtrlStationary" 4 "Marine" 3 "Construction" 2 "Agricultural and Forestry" 1 "On-Highway" 0 "Global" ;
VAL_ 2364473091 Function 127 "Reserved" 126 "Reserved" 125 "Reserved" 124 "Reserved" 123 "Reserved" 122 "Reserved" 121 "Reserved" 120 "Reserved" 119 "Reserved" 118 "Reserved" 117 "Reserved" 116 "Reserved" 115 "Reserved" 114 "Reserved" 113 "Reserved" 112 "Reserved" 111 "Reserved" 110 "Reserved" 109 "Reserved" 108 "Reserved" 107 "Reserved" 106 "Reserved" 105 "Reserved" 104 "Reserved" 103 "Reserved" 102 "Reserved" 101 "Reserved" 42 "Water Pump Control" 41 "Lighting - Operator Controls" 40 "Seat Control" 39 "Ignition Control Module" 38 "Tire Pressure Control" 37 "Cab Controller" 36 "Pneumatic - System Controller" 35 "Suspension - System Controller" 34 "Hydraulic Pump Controller" 33 "System Monitor" 32 "Headway Controller" 31 "Propulsion Battery Charger" 30 "Management Computer" 29 "Virtual Terminal (in cab)" 28 "Off Vehicle Gateway" 27 "Power TakeOff (Secondary or Front)" 26 "Body Controller" 25 "Network Interconnect ECU" 24 "Vehicle Security" 23 "Vehicle Navigation" 22 "Aerodynamic Control" 21 "Cab Climate Control" 20 "Trip Recorder" 19 "Instrument Cluster" 18 "Suspension - Drive Axle" 17 "Suspension - Steer Axle" 16 "Steering Controller" 15 "Fuel System" 14 "Cruise Control" 13 "Retarder - Driveline" 12 "Retarder - Engine" 11 "Brakes - Drive Axle" 10 "Brakes - Steer Axle" 9 "Brakes - System Controller" 8 "Axle - Drive" 7 "Axle - Steering" 6 "Power TakeOff - (Main or Rear)" 5 "Shift Control/Console" 4 "Battery Pack Monitor" 3 "Transmission" 2 "Electric Propulsion Control" 1 "Auxiliary Power Unit (APU)" 0 "Engine" 100 "Reserved" 99 "Reserved" 98 "Reserved" 97 "Reserved" 96 "Reserved" 95 "Reserved" 94 "Reserved" 93 "Reserved" 92 "Reserved" 91 "Reserved" 90 "Reserved" 89 "Reserved" 88 "Reserved" 87 "Reserved" 86 "Reserved" 85 "Reserved" 84 "Reserved" 83 "Reserved" 82 "Reserved" 81 "Reserved" 80 "Reserved" 79 "Reserved" 78 "Fire Suppression System" 77 "Fuel Properties Sensor" 76 "Temperature Sensor" 75 "Supplemental Fan" 74 "Lubrication System" 73 "Rollover Detection Control" 72 "Coolant Valve Controller" 71 "Transfer Case Control" 70 "Auxiliary Regeneration Device" 69 "Engine Emission Aftertreatement System" 68 "Aftertreatment system gas measurement" 67 "Electrical System Controller" 66 "I/O Controller" 65 "Gas Flow Measurement" 64 "Endurance Braking" 63 "Engine Valve Controller" 62 "On-Board Diagnostic Unit" 61 "File Server/Printer" 60 "Cab Display" 59 "Starter" 58 "Fan Drive Control" 57 "Steering Column Unit" 56 "Communications Unit, Radio" 55 "Communications Unit, Satellite" 54 "Communications Unit, Cellular" 53 "Alternator/Charging System" 52 "Chassis Controller" 51 "Forward-Looking Collision Warning System" 50 "Auxiliary Heater" 49 "Clutch/Converter Control" 48 "Ramp Control" 47 "Information System Controller" 46 "Oil Sensor Unit" 45 "Vehicle Dynamic Stability Control" 44 "Exhaust Emission Control" 43 "Transmission Display" ;
VAL_ 2364473091 ManufacturerCode 454 "NGK Spark Plug Co. Ltd" 453 "Cooper Bussmann" 452 "WIKA Alexander Wiegand SE & Co. KG" 451 "Parker Hannifin Corp" 450 "Dycor Technologies Ltd." 449 "Polaris Industries Inc" 448 "Stanadyne Corporation, Electronics Systems" 447 "Great Plains Mfg." 446 "CertTech, L.L.C." 445 "KAT MECHATRONIC, Electronic Product Division" 444 "ITT Power Solutions" 443 "SignalQuest, Inc." 442 "Horsch Maschinen GmbH" 441 "PTG Reifendruckregelsysteme GmbH" 440 "Cummins Power Generation" 439 "Hyundai Heavy Industries" 438 "Comar Systems Ltd" 437 "Digital Yacht Limited" 436 "Kinze Manufacturing" 435 "Zunhammer GmbH" 434 "Stored Energy Systems" 433 "Rowe Electronics" 432 "S&A Systems, Inc." 431 "Tohatsu Corporation" 430 "Auteq Telematica S.A." 520 "Trapeze" 519 "Peeters Landbouwmachines b.v." 518 "Transas USA Inc." 517 "Noland Engineering" 516 "AVAT Automation GmbH" 515 "GINAF Trucks Nederland B.V." 514 "DISTek Integration, Inc." 513 "FarmscanAg" 512 "Inpower LLC" 511 "Sulky" 510 "Marinesoft Co. Ltd" 509 "MOTORTECH GmbH" 508 "Transtech Innovations" 507 "Test Center ISOBUS" 506 "IHI STAR Machinery Corporation" 505 "Yetter Farm Equipment" 504 "Vesper Marine" 503 "Naviop S.R.L." 502 "Attwood Corporation" 501 "Agrotronix S.A." 500 "Oxbo International Corporation" 499 "LCJ Capteurs" 498 "Innovative Design Solutions, Inc" 497 "SENTRON Sistemas Embarcados" 496 "W. Gessmann GmbH" 495 "HOLMER Maschinenbau GmbH" 494 "Synerject" 493 "Watcheye" 492 "Inergy Automotive Systems" 491 "Penny and Giles Ltd" 490 "QuikQ" 489 "Appareo Systems" 488 "The Charles Machine Works, Inc." 487 "DSE Test Solutions A/S" 486 "Westport Innovations Inc." 485 "MATT automotive" 484 "Headsight Inc." 483 "Valeo" 482 "Tricon Electronics" 481 "Chetco Digital Instruments" 480 "EnerDel, Inc." 479 "Vapor Bus International" 478 "OceanSat BV" 477 "OilQuick AB" 476 "Hummingbird Marine Electronics" 475 "GME" 474 "Persen Technologies Inc." 473 "Boss Industries, Inc." 472 "Tenneco Inc." 471 "Sea Cross Marine AB" 470 "SI-TEX Marine Electronics" 469 "RA Consulting GmbH" 468 "Tyco Fire Protection Products" 467 "Lely Industries N.V." 466 "Veethree Electronics and Marine LLC" 465 "Ashcroft Inc" 464 "Leach International Corporation" 463 "PROBOTIQ" 462 "IHI Shibaura Machinery Corporation" 461 "HAWE Hydraulik SE" 460 "San Giorgio S.E.I.N." 459 "Alltek Marine Electronics Corp" 458 "Control Solutions, Inc." 457 "RUSELPROM-ElectricDrive Ltd" 456 "General Kinetics" 455 "ADZ NAGANO GmbH" 429 "Rota Engineering Ltd." 428 "Mfg_428" 427 "em-trak Marine Electronics Ltd" 426 "Egersund Marine Electronics AS" 425 "Methode Electronics Inc, MDI" 424 "Odyne LLC" 423 "BSM Wireless, Inc." 422 "True Heading AB" 421 "Vertex Standard Co, Ltd" 420 "Vermeer Corporation, ACS Group" 419 "Fusion Electronics Ltd" 418 "Intellistick Inc" 417 "KZValve" 416 "Kubota Corporation" 415 "Valid Manufacturing Ltd." 414 "Cattron Group International" 413 "Datapross Nijbroek bv" 412 "WebTech Wireless Inc." 411 "Hy-Drive Technologies Ltd." 410 "COBO S.p.A. Divisione 3B6" 409 "Transfluid S.r.L." 408 "Corvus Energy Ltd." 407 "Comtech Mobile Datacom" 406 "Vecima Networks Inc." 405 "Wema System AS" 404 "Com Nav Marine Ltd" 403 "Trackwell ADS, Inc." 402 "Simma Software, Inc." 401 "Torqeedo GmbH" 400 "Livorsi Marine" 399 "ISEKI & Co., Ltd." 398 "Hilite International" 397 "Sanyo-kiki Co Ltd." 396 "Beyond Measure" 395 "GENTEC S.R.L." 394 "Capi 2 Nederland BV" 393 "Harvest Tec, Inc" 392 "Tianyuan Technology Co Ltd." 391 "Electronic Design for Industry, Inc" 390 "Partech Inc." 389 "Benchmark Electronics, Minnesota Division" 388 "Innomatix, LLC" 387 "Orscheln Products, LLC" 386 "JLG Automation BVBA" 385 "Johnson Outdoor Marine Electronics" 384 "Camano Light" 383 "MCL Industries" 382 "National Agricultural and Food Research Organization" 380 "Suntech International Ltd." 379 "Yamabiko Corporation" 378 "Glendinning Marine Products" 377 "ifm electronic gmbh" 376 "Quake Global" 375 "Williams Controls Inc." 372 "Delphi" 381 "B&G" 374 "Northern Lights, Inc." 373 "Electronic Design Inc." 371 "Heinzmann GmbH & Co. KG" 370 "Rolls-Royce Marine AS" 369 "Power Torque Engineering Ltd" 368 "HANSENHOF_electronic" 367 "Fliegl Agrartechnik" 366 "Viewnyx Corp." 365 "Digi-Star, LLC" 364 "OEM Controls Inc." 363 "BEI Duncan" 362 "Alois Poettinger Maschinenfabrik GmbH" 361 "InMach" 360 "HJS Emission Technology GmbH & Co KG" 359 "Ludwig Bergmann GmbH" 358 "Victron Energy BV" 357 "Hardi International A/S" 356 "Fischer Panda Generators, Inc" 355 "Mastervolt International B.V." 354 "Junkkari OY" 353 "Hegemon Electronics, Inc." 352 "SAME DEUTZ-FAHR" 351 "Thrane & Thrane" 350 "Noris Marine Systems GmbH & Co KG" 349 "Suonentiet" 348 "Amazonen Werke H. Dreyer" 347 "Honeywell" 346 "Control Solutions" 345 "Korean Maritime University" 344 "Parvus Corporation" 343 "Baumer Group" 342 "THOMAS MAGNETE GmbH" 341 "Boning GmbH & Co" 340 "Continental AG" 339 "Competence Center ISOBUS e.V." 338 "GRAF-SYTECO" 337 "Carraro S.p.A." 336 "APE s.r.o." 335 "Evo Electric Ltd" 334 "Takata-Petri AG" 333 "Hadley Products Corporation" 332 "HWH Corporation" 331 "Horton, Inc." 330 "Kidde Aerospace and Defense" 329 "Deif A/S" 328 "Qwerty Electronik AB" 252 "Sensor-Technik Wiedemann GmbH" 251 "German Agricultural Society" 250 "Kuhn Group" 249 "Schaltbau GmbH" 233 "Yacht Monitoring Solutions Inc." 232 "TSD Integrated Controls" 1863 "Thomas G. Faria Co." 1862 "Sanshin" 1861 "Vector CANtech" 1860 "MMP" 1859 "Kvasar AB" 1858 "Litton" 1857 "Simrad" 1856 "Trimble" 1855 "Furuno USA" 1854 "Northstar Technologies" 1853 "Japan Radio Co." 1852 "Navionics" 1851 "Raymarine" 1850 "Teleflex" 222 "Generac Power Systems, Inc." 221 "SiE" 220 "Beede Electrical Instrument Company, Inc." 219 "Cat OEM Solutions" 218 "Gits Manufacturing Company" 217 "RM Michaelides Software & Elektronik GmbH" 216 "Paneltronics Inc." 215 "Aetna Engineering/Fireboy-Xintex" 214 "MC elettronica Srl" 213 "CNH Belgium N.V." 212 "Sure Power Industries, Inc." 211 "DNA Group" 210 "Iteris, Inc." 209 "Bell Equip. Co. SA (PTY) LTD" 208 "Drew Technologies, Inc." 207 "Otto Engineering" 206 "port GmbH" 205 "SmarTire Systems Inc" 204 "The Morey Corporation" 203 "MILtronik GmbH" 202 "Curtis Instruments, Inc." 201 "Disenos y Tecnologia S.A." 200 "MGM Brakes" 199 "Actia Corp." 198 "Mystic Valley Communications" 197 "Mechron Power Systems" 196 "LEMKEN GmbH & Co. KG" 195 "General Engine Products" 194 "TriMark Corporation" 193 "Nobletec" 192 "Floscan" 191 "XRS Corporation" 190 "Hella KGaA Hueck & Co." 189 "QUALCOMM" 188 "EMP Corp." 187 "Air-Weigh" 186 "Altronic, Inc." 185 "Beede Electrical Instrument Company" 184 "EIA Electronics" 183 "KDS Controls, Inc." 182 "Vehicle Systems Engineering B.V." 181 "Coretronics, Inc." 180 "Smart Power Systems" 179 "TeeJet Technologies Denmark" 178 "Siemens VDO Automotive AG" 177 "Diagnostic System Associates" 176 "Moritz Aerospace" 175 "Veris Technologies, Inc." 174 "AB Volvo Penta" 173 "Ryeso, Inc." 172 "Yanmar Marine USA" 171 "Wachendorff Elektronik GmbH & Co. KG" 170 "Computronics Corporation Ltd." 169 "Marlin Technologies Inc." 168 "Xantrex" 167 "JLG Industries Inc." 166 "Phoenix International" 165 "CPAC Systems AB" 164 "DaimlerChrysler Off-Highway" 163 "BRP Inc." 162 "Axiomatic Technologies" 161 "Offshore Systems (UK) Limited" 160 "Nido" 159 "NTech Industries Inc." 158 "Firestone Industrial Products Company" 157 "ISSPRO Inc." 156 "ITT Industries - Cannon" 155 "Vetronix Corporation" 154 "Westerbeke Corporation" 153 "Woodward, Industrial Controls Division" 152 "elobau GmbH & Co. KG" 151 "Raven Industries Inc. - Flow Controls Division" 150 "Fleetguard" 149 "Holset" 148 "Blue Water Data, Inc." 147 "Nautibus Electronic GmbH" 146 "Maxima Technologies" 145 "MurCal Controls" 144 "Mercury Marine" 143 "W. Gmeiner GmbH & Co." 142 "TRW Automotive (Commercial Steering Systems)" 141 "Thales Navigation Ltd." 140 "Lowrance Electronics, Inc." 139 "Caterpillar Trimble Control Technologies (CTCT), LLC" 138 "Georg Fritzmeier GmbH & Co. KG" 137 "Maretron" 136 "Komatsu Ltd." 135 "Airmar Technology Corporation" 134 "Iris Technology Ltd." 133 "Bucher Schoerling GmbH" 132 "Mulag-Fahrzeugwerk" 131 "ITT Industries" 130 "Nido - Universal Machines B.V." 129 "OMNEX Control Systems, Inc." 128 "Gerhard Duecker GmbH & Co. KG" 127 "Holland USA" 126 "Driver Tech" 125 "Nevada Automotive Test Center" 124 "Hydac Electronic" 123 "Basler Electric" 122 "FG Wilson (Engineering) Limited" 121 "HED (Hydro Electronic Devices, Inc.)" 120 "RDS Technology Ltd." 119 "IntegriNautics" 118 "Intron GmbH" 117 "HUSCO International" 116 "BEELINE Technologies" 115 "NACCO Materials Handling Group, Inc." 114 "EControls, Inc." 113 "Stress-Tek, Inc." 112 "MECALAC" 111 "Maschinenfabrik Bernard Krone GmbH" 110 "EPIQ Sensor-Nite" 109 "TeeJet Technologies Denmark" 108 "WTK-Elecktronik GmbH" 107 "Grimme Landmaschinen GmbH & Co. KG" 106 "BAE Systems Controls, Inc." 105 "Kiepe Elektrik GmbH & Co. KG" 104 "Claas Selbstfahrende Erntemaschinen GmbH" 103 "CLAAS Agrosystems GmbH & Co. KG" 102 "AGCO GmbH & Co." 101 "Sensoria" 100 "VDO Technik AG" 99 "International Transmissions Ltd (ITL)" 98 "Mueller-Elektronik GmbH & Co." 97 "Ag Leader Technology, Inc." 96 "Mech@tronic IT GmbH" 95 "Pacific Insight Electronics Corp." 94 "CNH Global N.V." 93 "Perkins Engines Company Ltd." 92 "Ag-Chem Equipment Co., Inc." 91 "BSG Bodensee Steuergeraete GmbH" 90 "Knorr-Bremse SfN GmbH" 89 "Kverneland Group, Electronics Division" 88 "Satloc Precision GPS" 87 "J.C. Bamford Excavators Ltd (JCB)" 86 "C.E. Niehoff & Company" 85 "Kohler Co." 84 "New Holland UK Limited" 83 "Bendix VORAD Technologies" 82 "Bobcat/Ingersoll-Rand" 81 "Fire Research Corp" 80 "Twin Disc, Inc." 79 "Daimler Benz AG - Engine Division (PBM)" 78 "Frank W. Murphy Manufacturing, Inc." 77 "Deere Power Systems Group" 76 "unused" 75 "Deere & Co. Agricultural Division" 74 "Eaton Axle-Brake Division" 73 "LeTourneau, Inc." 72 "Sisu Corporation" 71 "Vansco Electronics Ltd." 70 "Flex-Coil Limited" 69 "Trimble Navigation" 68 "Scania" 67 "Funk Manufacturing Company" 66 "John Deere Construction Equipment Division" 65 "MAN Nutzfahrzeuge AG" 64 "unused" 63 "ZF Industries Inc." 62 "Wabco" 61 "Volvo Truck Corp." 60 "Volvo Trucks North America Inc." 59 "VES Inc." 58 "SPX Corporation, OTC Division" 57 "Sauer-Danfoss Co." 56 "SAIC" 55 "Ryder System Inc." 54 "Meritor Wabco" 53 "Continental Automotive Systems US, Inc." 52 "Meritor Automotive, Inc." 51 "Robert Bosch GmbH" 50 "Robert Bosch Corp" 49 "RE America Inc." 48 "Pollak Alphabet" 47 "Phillips Semiconductor" 46 "Noregon Systems, Inc" 45 "PACCAR" 44 "Nippondenso Co. Ltd." 43 "International Truck and Engine Corp. Vehicle Electronics" 42 "International Truck and Engine Corp. Engine Electronics" 41 "Motorola Inc." 40 "Motorola AIEG Inc." 39 "Microfirm Inc." 38 "Micro Processor Systems Inc." 37 "Mack Trucks Inc." 36 "Lucas Ltd." 35 "Kenworth Truck Co." 34 "Kelsey Hayes Co." 33 "John Deere" 32 "Jacobs Vehicle Systems" 31 "J Pollak Corp." 30 "Isuzu Motors Ltd." 29 "Hino Motors Ltd." 28 "Grote Ind. Inc." 27 "GMC" 26 "General Motors Corp., Service Technology Group" 25 "Daimler Trucks North America LLC" 24 "Ford Motor Co., Vehicle Controls" 23 "Ford Motor Co., Heavy Truck" 22 "Ford Motor Co., Electronic Concepts $ Systems" 21 "Echilin Inc., Midland Brake Inc." 20 "Eaton Ltd" 19 "Eaton Corp. Trucking Info Services" 18 "Eaton Corp, Transmission Division" 17 "Eaton Corp. Res & Dev" 16 "Eaton Corp." 15 "Dickey-John Corp." 14 "Detroit Diesel Corporation" 13 "Delco Electronics" 12 "Deere & Company, Precision Farming" 11 "Dearborn Group Inc." 10 "Cummins Engine Co." 9 "Chrysler Corp." 8 "Caterpillar Inc." 7 "Case Corp." 6 "Berifors Electronics AB" 5 "AMP Inc." 4 "Ametek-Dixson" 3 "Ametek, US Gauge Division" 2 "Allison Transmission, GMC" 1 "Allied Signal Inc." 0 "Reserved" 231 "Topcon Positioning Systems, Inc." 230 "Saucon Technologies" 229 "Garmin International Inc." 228 "ZF Marine Electronics" 227 "Lykketronic A/S" 226 "Monaco Coach Corporation" 225 "SKF" 224 "EMMI Network, S.L." 223 "Vaueo Retarder Co., Ltd." 263 "IMMI" 262 "HydraForce, Inc" 261 "Red Dot Corporation" 260 "Reichhardt GmbH" 259 "Jetter AG" 258 "ARAG" 257 "Honda Motor Co., Ltd" 256 "Tyco Electronics AMP" 255 "MEAS France" 254 "GE Sensing" 253 "Mobile Control Systems" 298 "Holley Performance" 297 "Zonar Systems Inc" 296 "micro dynamics GmbH" 295 "BEP Marine" 294 "Grayhill Inc." 293 "Spyder Controls Corp." 292 "IKUSI - Angel Iglesias S.A." 291 "Groeneveld Transport Efficiency BV" 290 "Kuebler GmbH" 289 "Watlow" 288 "Mitsubishi FUSO Truck & Bus Corp." 287 "NTech Industries, Inc" 286 "Coelmo srl" 285 "Sea Recovery Corp" 284 "Mobile Tech Chile" 283 "CWF Hamilton & Co Ltd" 282 "Medallion Instrumentation Systems" 281 "Precision Governors LLC" 311 "Patrick Power Products" 310 "TECNORD srl" 309 "Krauss-Maffei Wegmann GmbH & Co. KG" 308 "Cyntrx" 307 "MBW Technologies" 306 "Sleipner Motor AB" 305 "NovAtel Inc" 304 "EmpirBus AB" 303 "CTS Corporation" 302 "Nissin Kogyo Co., LTD" 301 "Parker Hannifin (UK) Ltd FDE group" 300 "Systron Donner Automotive" 299 "Rauch Landmaschinen GmbH" 280 "Leica Geosystems Pty Ltd" 279 "Geometris LP" 278 "Takata Electronics" 277 "LHP Telematics" 276 "Aqua-Hot Heating Systems" 275 "Navico Egersund AS" 274 "LTW Technology Co., LTD" 273 "Active Research Limited" 272 "Gross Mechanical Laboratories, Inc" 327 "Sonceboz SA" 326 "Akron Brass Company" 325 "ASM Automation Sensorik Messtechnik GmbH" 324 "Snap-on Diagnostics" 323 "Mobileye Vision Technologies Ltd." 322 "MICHENKA s.r.o." 321 "Ultra Electronics, Electrics" 320 "Miedema Landbouwwerktuigenfabriek B.V." 319 "Cadec Global" 318 "SAT Plan" 317 "Navtronics Bvba" 316 "ITT Flow Control" 315 "Icom Incorporated" 314 "CSM GmbH" 313 "Ilmor Engineering, Inc" 312 "Lectronix, Inc." 271 "Cole Hersee" 270 "Tennant" 269 "Saft America Inc.,  Space & Defense Division" 268 "Accurate Technologies" 267 "Red Lion Controls, Inc" 266 "International Thermal Research Ltd" 265 "MTS Sensor Technologie GmbH" 264 "Autolync" 248 "Cooper Standard Automotive Active Systems Group" 247 "ePULSE" 246 "Class 1, Inc" 245 "Capstan Ag Systems, Inc." 244 "Techno-Matic" 243 "eRide, Inc." 242 "Kokusandenki Co. Ltd" 241 "Schneider Automation SAS " 240 "Vanair Mfg" 239 "May & Scofield Ltd" 238 "ZF Friedrichshafen AG" 237 "Agtron Enterprises Inc" 236 "Norac Systems International Inc" 235 "SailorMade Marine Telemetry - Tetra Technology Ltd." 234 "Mondial electronic GmbH" ;
VAL_ 2364473091 VehicleSystem 0 "Non-specific System" 127 "Not Available" ;
VAL_ 2364473091 VehicleSystem5 127 "Not Available" 0 "Ind. Process Control Stationary" ;
VAL_ 2364473091 VehicleSystem4 125 "Entertainment" 120 "Display" 85 "External Environment" 75 "Sensor Communication Interface" 35 "Electrical Generation" 100 "Deck, Cargo and Fishing Equipment" 90 "Internal Environment" 80 "Instrumentation/General Systems (deprecate)" 70 "Communications" 60 "Navigation" 50 "Propulsion" 40 "Steering and Control Surfaces" 30 "Electrical Distribution" 25 "Inter/Intranetwork Device" 20 "Safety Systems" 10 "System Tools" 127 "Not Available" 0 "Non-specific System" ;
VAL_ 2364473091 VehicleSystem3 8 "Grader" 7 "Four Wheel Drive Loader" 6 "Forklift" 5 "Excavator" 4 "Crawler" 3 "Backhoe" 2 "Articulated Dump Truck" 1 "Skid Steer Loader" 127 "Not Available" 0 "Non-specific System" ;
VAL_ 2364473091 VehicleSystem2 25 "Slurry Applicators" 24 "Utility Vehicles" 23 "Mulchers" 22 "Timber Processing Machines" 21 "Timber loaders" 20 "Forwarders" 19 "Timber Harvesters" 17 "Sensor Systems" 16 "Skidder" 15 "Earth Work" 14 "Special Crops" 13 "Powered Auxiliary Device" 12 "Farm Yard Operations" 11 "Transport/Trailer" 10 "Irrigation" 9 "Forage" 8 "Root Harvesters" 7 "Harvesters" 6 "Sprayers" 5 "Fertilizers" 4 "Planters/Seeders" 3 "Secondary Tillage" 2 "Tillage" 1 "Tractor" 127 "Not Available" 0 "Non-specific System" ;
VAL_ 2364473091 VehicleSystem1 2 "Trailer" 1 "Tractor" 127 "Not Available" 0 "Non-specific System" ;
VAL_ 2364473088 IndustryGroup 6 "Reserved for SAE" 7 "Reserved for SAE" 5 "IndustrialProcessCtrlStationary" 4 "Marine" 3 "Construction" 2 "Agricultural and Forestry" 1 "On-Highway" 0 "Global" ;
VAL_ 2364473088 Function 127 "Reserved" 126 "Reserved" 125 "Reserved" 124 "Reserved" 123 "Reserved" 122 "Reserved" 121 "Reserved" 120 "Reserved" 119 "Reserved" 118 "Reserved" 117 "Reserved" 116 "Reserved" 115 "Reserved" 114 "Reserved" 113 "Reserved" 112 "Reserved" 111 "Reserved" 110 "Reserved" 109 "Reserved" 108 "Reserved" 107 "Reserved" 106 "Reserved" 105 "Reserved" 104 "Reserved" 103 "Reserved" 102 "Reserved" 101 "Reserved" 42 "Water Pump Control" 41 "Lighting - Operator Controls" 40 "Seat Control" 39 "Ignition Control Module" 38 "Tire Pressure Control" 37 "Cab Controller" 36 "Pneumatic - System Controller" 35 "Suspension - System Controller" 34 "Hydraulic Pump Controller" 33 "System Monitor" 32 "Headway Controller" 31 "Propulsion Battery Charger" 30 "Management Computer" 29 "Virtual Terminal (in cab)" 28 "Off Vehicle Gateway" 27 "Power TakeOff (Secondary or Front)" 26 "Body Controller" 25 "Network Interconnect ECU" 24 "Vehicle Security" 23 "Vehicle Navigation" 22 "Aerodynamic Control" 21 "Cab Climate Control" 20 "Trip Recorder" 19 "Instrument Cluster" 18 "Suspension - Drive Axle" 17 "Suspension - Steer Axle" 16 "Steering Controller" 15 "Fuel System" 14 "Cruise Control" 13 "Retarder - Driveline" 12 "Retarder - Engine" 11 "Brakes - Drive Axle" 10 "Brakes - Steer Axle" 9 "Brakes - System Controller" 8 "Axle - Drive" 7 "Axle - Steering" 6 "Power TakeOff - (Main or Rear)" 5 "Shift Control/Console" 4 "Battery Pack Monitor" 3 "Transmission" 2 "Electric Propulsion Control" 1 "Auxiliary Power Unit (APU)" 0 "Engine" 100 "Reserved" 99 "Reserved" 98 "Reserved" 97 "Reserved" 96 "Reserved" 95 "Reserved" 94 "Reserved" 93 "Reserved" 92 "Reserved" 91 "Reserved" 90 "Reserved" 89 "Reserved" 88 "Reserved" 87 "Reserved" 86 "Reserved" 85 "Reserved" 84 "Reserved" 83 "Reserved" 82 "Reserved" 81 "Reserved" 80 "Reserved" 79 "Reserved" 78 "Fire Suppression System" 77 "Fuel Properties Sensor" 76 "Temperature Sensor" 75 "Supplemental Fan" 74 "Lubrication System" 73 "Rollover Detection Control" 72 "Coolant Valve Controller" 71 "Transfer Case Control" 70 "Auxiliary Regeneration Device" 69 "Engine Emission Aftertreatement System" 68 "Aftertreatment system gas measurement" 67 "Electrical System Controller" 66 "I/O Controller" 65 "Gas Flow Measurement" 64 "Endurance Braking" 63 "Engine Valve Controller" 62 "On-Board Diagnostic Unit" 61 "File Server/Printer" 60 "Cab Display" 59 "Starter" 58 "Fan Drive Control" 57 "Steering Column Unit" 56 "Communications Unit, Radio" 55 "Communications Unit, Satellite" 54 "Communications Unit, Cellular" 53 "Alternator/Charging System" 52 "Chassis Controller" 51 "Forward-Looking Collision Warning System" 50 "Auxiliary Heater" 49 "Clutch/Converter Control" 48 "Ramp Control" 47 "Information System Controller" 46 "Oil Sensor Unit" 45 "Vehicle Dynamic Stability Control" 44 "Exhaust Emission Control" 43 "Transmission Display" ;
VAL_ 2364473088 ManufacturerCode 454 "NGK Spark Plug Co. Ltd" 453 "Cooper Bussmann" 452 "WIKA Alexander Wiegand SE & Co. KG" 451 "Parker Hannifin Corp" 450 "Dycor Technologies Ltd." 449 "Polaris Industries Inc" 448 "Stanadyne Corporation, Electronics Systems" 447 "Great Plains Mfg." 446 "CertTech, L.L.C." 445 "KAT MECHATRONIC, Electronic Product Division" 444 "ITT Power Solutions" 443 "SignalQuest, Inc." 442 "Horsch Maschinen GmbH" 441 "PTG Reifendruckregelsysteme GmbH" 440 "Cummins Power Generation" 439 "Hyundai Heavy Industries" 438 "Comar Systems Ltd" 437 "Digital Yacht Limited" 436 "Kinze Manufacturing" 435 "Zunhammer GmbH" 434 "Stored Energy Systems" 433 "Rowe Electronics" 432 "S&A Systems, Inc." 431 "Tohatsu Corporation" 430 "Auteq Telematica S.A." 520 "Trapeze" 519 "Peeters Landbouwmachines b.v." 518 "Transas USA Inc." 517 "Noland Engineering" 516 "AVAT Automation GmbH" 515 "GINAF Trucks Nederland B.V." 514 "DISTek Integration, Inc." 513 "FarmscanAg" 512 "Inpower LLC" 511 "Sulky" 510 "Marinesoft Co. Ltd" 509 "MOTORTECH GmbH" 508 "Transtech Innovations" 507 "Test Center ISOBUS" 506 "IHI STAR Machinery Corporation" 505 "Yetter Farm Equipment" 504 "Vesper Marine" 503 "Naviop S.R.L." 502 "Attwood Corporation" 501 "Agrotronix S.A." 500 "Oxbo International Corporation" 499 "LCJ Capteurs" 498 "Innovative Design Solutions, Inc" 497 "SENTRON Sistemas Embarcados" 496 "W. Gessmann GmbH" 495 "HOLMER Maschinenbau GmbH" 494 "Synerject" 493 "Watcheye" 492 "Inergy Automotive Systems" 491 "Penny and Giles Ltd" 490 "QuikQ" 489 "Appareo Systems" 488 "The Charles Machine Works, Inc." 487 "DSE Test Solutions A/S" 486 "Westport Innovations Inc." 485 "MATT automotive" 484 "Headsight Inc." 483 "Valeo" 482 "Tricon Electronics" 481 "Chetco Digital Instruments" 480 "EnerDel, Inc." 479 "Vapor Bus International" 478 "OceanSat BV" 477 "OilQuick AB" 476 "Hummingbird Marine Electronics" 475 "GME" 474 "Persen Technologies Inc." 473 "Boss Industries, Inc." 472 "Tenneco Inc." 471 "Sea Cross Marine AB" 470 "SI-TEX Marine Electronics" 469 "RA Consulting GmbH" 468 "Tyco Fire Protection Products" 467 "Lely Industries N.V." 466 "Veethree Electronics and Marine LLC" 465 "Ashcroft Inc" 464 "Leach International Corporation" 463 "PROBOTIQ" 462 "IHI Shibaura Machinery Corporation" 461 "HAWE Hydraulik SE" 460 "San Giorgio S.E.I.N." 459 "Alltek Marine Electronics Corp" 458 "Control Solutions, Inc." 457 "RUSELPROM-ElectricDrive Ltd" 456 "General Kinetics" 455 "ADZ NAGANO GmbH" 429 "Rota Engineering Ltd." 428 "Mfg_428" 427 "em-trak Marine Electronics Ltd" 426 "Egersund Marine Electronics AS" 425 "Methode Electronics Inc, MDI" 424 "Odyne LLC" 423 "BSM Wireless, Inc." 422 "True Heading AB" 421 "Vertex Standard Co, Ltd" 420 "Vermeer Corporation, ACS Group" 419 "Fusion Electronics Ltd" 418 "Intellistick Inc" 417 "KZValve" 416 "Kubota Corporation" 415 "Valid Manufacturing Ltd." 414 "Cattron Group International" 413 "Datapross Nijbroek bv" 412 "WebTech Wireless Inc." 411 "Hy-Drive Technologies Ltd." 410 "COBO S.p.A. Divisione 3B6" 409 "Transfluid S.r.L." 408 "Corvus Energy Ltd." 407 "Comtech Mobile Datacom" 406 "Vecima Networks Inc." 405 "Wema System AS" 404 "Com Nav Marine Ltd" 403 "Trackwell ADS, Inc." 402 "Simma Software, Inc." 401 "Torqeedo GmbH" 400 "Livorsi Marine" 399 "ISEKI & Co., Ltd." 398 "Hilite International" 397 "Sanyo-kiki Co Ltd." 396 "Beyond Measure" 395 "GENTEC S.R.L." 394 "Capi 2 Nederland BV" 393 "Harvest Tec, Inc" 392 "Tianyuan Technology Co Ltd." 391 "Electronic Design for Industry, Inc" 390 "Partech Inc." 389 "Benchmark Electronics, Minnesota Division" 388 "Innomatix, LLC" 387 "Orscheln Products, LLC" 386 "JLG Automation BVBA" 385 "Johnson Outdoor Marine Electronics" 384 "Camano Light" 383 "MCL Industries" 382 "National Agricultural and Food Research Organization" 380 "Suntech International Ltd." 379 "Yamabiko Corporation" 378 "Glendinning Marine Products" 377 "ifm electronic gmbh" 376 "Quake Global" 375 "Williams Controls Inc." 372 "Delphi" 381 "B&G" 374 "Northern Lights, Inc." 373 "Electronic Design Inc." 371 "Heinzmann GmbH & Co. KG" 370 "Rolls-Royce Marine AS" 369 "Power Torque Engineering Ltd" 368 "HANSENHOF_electronic" 367 "Fliegl Agrartechnik" 366 "Viewnyx Corp." 365 "Digi-Star, LLC" 364 "OEM Controls Inc." 363 "BEI Duncan" 362 "Alois Poettinger Maschinenfabrik GmbH" 361 "InMach" 360 "HJS Emission Technology GmbH & Co KG" 359 "Ludwig Bergmann GmbH" 358 "Victron Energy BV" 357 "Hardi International A/S" 356 "Fischer Panda Generators, Inc" 355 "Mastervolt International B.V." 354 "Junkkari OY" 353 "Hegemon Electronics, Inc." 352 "SAME DEUTZ-FAHR" 351 "Thrane & Thrane" 350 "Noris Marine Systems GmbH & Co KG" 349 "Suonentiet" 348 "Amazonen Werke H. Dreyer" 347 "Honeywell" 346 "Control Solutions" 345 "Korean Maritime University" 344 "Parvus Corporation" 343 "Baumer Group" 342 "THOMAS MAGNETE GmbH" 341 "Boning GmbH & Co" 340 "Continental AG" 339 "Competence Center ISOBUS e.V." 338 "GRAF-SYTECO" 337 "Carraro S.p.A." 336 "APE s.r.o." 335 "Evo Electric Ltd" 334 "Takata-Petri AG" 333 "Hadley Products Corporation" 332 "HWH Corporation" 331 "Horton, Inc." 330 "Kidde Aerospace and Defense" 329 "Deif A/S" 328 "Qwerty Electronik AB" 252 "Sensor-Technik Wiedemann GmbH" 251 "German Agricultural Society" 250 "Kuhn Group" 249 "Schaltbau GmbH" 233 "Yacht Monitoring Solutions Inc." 232 "TSD Integrated Controls" 1863 "Thomas G. Faria Co." 1862 "Sanshin" 1861 "Vector CANtech" 1860 "MMP" 1859 "Kvasar AB" 1858 "Litton" 1857 "Simrad" 1856 "Trimble" 1855 "Furuno USA" 1854 "Northstar Technologies" 1853 "Japan Radio Co." 1852 "Navionics" 1851 "Raymarine" 1850 "Teleflex" 222 "Generac Power Systems, Inc." 221 "SiE" 220 "Beede Electrical Instrument Company, Inc." 219 "Cat OEM Solutions" 218 "Gits Manufacturing Company" 217 "RM Michaelides Software & Elektronik GmbH" 216 "Paneltronics Inc." 215 "Aetna Engineering/Fireboy-Xintex" 214 "MC elettronica Srl" 213 "CNH Belgium N.V." 212 "Sure Power Industries, Inc." 211 "DNA Group" 210 "Iteris, Inc." 209 "Bell Equip. Co. SA (PTY) LTD" 208 "Drew Technologies, Inc." 207 "Otto Engineering" 206 "port GmbH" 205 "SmarTire Systems Inc" 204 "The Morey Corporation" 203 "MILtronik GmbH" 202 "Curtis Instruments, Inc." 201 "Disenos y Tecnologia S.A." 200 "MGM Brakes" 199 "Actia Corp." 198 "Mystic Valley Communications" 197 "Mechron Power Systems" 196 "LEMKEN GmbH & Co. KG" 195 "General Engine Products" 194 "TriMark Corporation" 193 "Nobletec" 192 "Floscan" 191 "XRS Corporation" 190 "Hella KGaA Hueck & Co." 189 "QUALCOMM" 188 "EMP Corp." 187 "Air-Weigh" 186 "Altronic, Inc." 185 "Beede Electrical Instrument Company" 184 "EIA Electronics" 183 "KDS Controls, Inc." 182 "Vehicle Systems Engineering B.V." 181 "Coretronics, Inc." 180 "Smart Power Systems" 179 "TeeJet Technologies Denmark" 178 "Siemens VDO Automotive AG" 177 "Diagnostic System Associates" 176 "Moritz Aerospace" 175 "Veris Technologies, Inc." 174 "AB Volvo Penta" 173 "Ryeso, Inc." 172 "Yanmar Marine USA" 171 "Wachendorff Elektronik GmbH & Co. KG" 170 "Computronics Corporation Ltd." 169 "Marlin Technologies Inc." 168 "Xantrex" 167 "JLG Industries Inc." 166 "Phoenix International" 165 "CPAC Systems AB" 164 "DaimlerChrysler Off-Highway" 163 "BRP Inc." 162 "Axiomatic Technologies" 161 "Offshore Systems (UK) Limited" 160 "Nido" 159 "NTech Industries Inc." 158 "Firestone Industrial Products Company" 157 "ISSPRO Inc." 156 "ITT Industries - Cannon" 155 "Vetronix Corporation" 154 "Westerbeke Corporation" 153 "Woodward, Industrial Controls Division" 152 "elobau GmbH & Co. KG" 151 "Raven Industries Inc. - Flow Controls Division" 150 "Fleetguard" 149 "Holset" 148 "Blue Water Data, Inc." 147 "Nautibus Electronic GmbH" 146 "Maxima Technologies" 145 "MurCal Controls" 144 "Mercury Marine" 143 "W. Gmeiner GmbH & Co." 142 "TRW Automotive (Commercial Steering Systems)" 141 "Thales Navigation Ltd." 140 "Lowrance Electronics, Inc." 139 "Caterpillar Trimble Control Technologies (CTCT), LLC" 138 "Georg Fritzmeier GmbH & Co. KG" 137 "Maretron" 136 "Komatsu Ltd." 135 "Airmar Technology Corporation" 134 "Iris Technology Ltd." 133 "Bucher Schoerling GmbH" 132 "Mulag-Fahrzeugwerk" 131 "ITT Industries" 130 "Nido - Universal Machines B.V." 129 "OMNEX Control Systems, Inc." 128 "Gerhard Duecker GmbH & Co. KG" 127 "Holland USA" 126 "Driver Tech" 125 "Nevada Automotive Test Center" 124 "Hydac Electronic" 123 "Basler Electric" 122 "FG Wilson (Engineering) Limited" 121 "HED (Hydro Electronic Devices, Inc.)" 120 "RDS Technology Ltd." 119 "IntegriNautics" 118 "Intron GmbH" 117 "HUSCO International" 116 "BEELINE Technologies" 115 "NACCO Materials Handling Group, Inc." 114 "EControls, Inc." 113 "Stress-Tek, Inc." 112 "MECALAC" 111 "Maschinenfabrik Bernard Krone GmbH" 110 "EPIQ Sensor-Nite" 109 "TeeJet Technologies Denmark" 108 "WTK-Elecktronik GmbH" 107 "Grimme Landmaschinen GmbH & Co. KG" 106 "BAE Systems Controls, Inc." 105 "Kiepe Elektrik GmbH & Co. KG" 104 "Claas Selbstfahrende Erntemaschinen GmbH" 103 "CLAAS Agrosystems GmbH & Co. KG" 102 "AGCO GmbH & Co." 101 "Sensoria" 100 "VDO Technik AG" 99 "International Transmissions Ltd (ITL)" 98 "Mueller-Elektronik GmbH & Co." 97 "Ag Leader Technology, Inc." 96 "Mech@tronic IT GmbH" 95 "Pacific Insight Electronics Corp." 94 "CNH Global N.V." 93 "Perkins Engines Company Ltd." 92 "Ag-Chem Equipment Co., Inc." 91 "BSG Bodensee Steuergeraete GmbH" 90 "Knorr-Bremse SfN GmbH" 89 "Kverneland Group, Electronics Division" 88 "Satloc Precision GPS" 87 "J.C. Bamford Excavators Ltd (JCB)" 86 "C.E. Niehoff & Company" 85 "Kohler Co." 84 "New Holland UK Limited" 83 "Bendix VORAD Technologies" 82 "Bobcat/Ingersoll-Rand" 81 "Fire Research Corp" 80 "Twin Disc, Inc." 79 "Daimler Benz AG - Engine Division (PBM)" 78 "Frank W. Murphy Manufacturing, Inc." 77 "Deere Power Systems Group" 76 "unused" 75 "Deere & Co. Agricultural Division" 74 "Eaton Axle-Brake Division" 73 "LeTourneau, Inc." 72 "Sisu Corporation" 71 "Vansco Electronics Ltd." 70 "Flex-Coil Limited" 69 "Trimble Navigation" 68 "Scania" 67 "Funk Manufacturing Company" 66 "John Deere Construction Equipment Division" 65 "MAN Nutzfahrzeuge AG" 64 "unused" 63 "ZF Industries Inc." 62 "Wabco" 61 "Volvo Truck Corp." 60 "Volvo Trucks North America Inc." 59 "VES Inc." 58 "SPX Corporation, OTC Division" 57 "Sauer-Danfoss Co." 56 "SAIC" 55 "Ryder System Inc." 54 "Meritor Wabco" 53 "Continental Automotive Systems US, Inc." 52 "Meritor Automotive, Inc." 51 "Robert Bosch GmbH" 50 "Robert Bosch Corp" 49 "RE America Inc." 48 "Pollak Alphabet" 47 "Phillips Semiconductor" 46 "Noregon Systems, Inc" 45 "PACCAR" 44 "Nippondenso Co. Ltd." 43 "International Truck and Engine Corp. Vehicle Electronics" 42 "International Truck and Engine Corp. Engine Electronics" 41 "Motorola Inc." 40 "Motorola AIEG Inc." 39 "Microfirm Inc." 38 "Micro Processor Systems Inc." 37 "Mack Trucks Inc." 36 "Lucas Ltd." 35 "Kenworth Truck Co." 34 "Kelsey Hayes Co." 33 "John Deere" 32 "Jacobs Vehicle Systems" 31 "J Pollak Corp." 30 "Isuzu Motors Ltd." 29 "Hino Motors Ltd." 28 "Grote Ind. Inc." 27 "GMC" 26 "General Motors Corp., Service Technology Group" 25 "Daimler Trucks North America LLC" 24 "Ford Motor Co., Vehicle Controls" 23 "Ford Motor Co., Heavy Truck" 22 "Ford Motor Co., Electronic Concepts $ Systems" 21 "Echilin Inc., Midland Brake Inc." 20 "Eaton Ltd" 19 "Eaton Corp. Trucking Info Services" 18 "Eaton Corp, Transmission Division" 17 "Eaton Corp. Res & Dev" 16 "Eaton Corp." 15 "Dickey-John Corp." 14 "Detroit Diesel Corporation" 13 "Delco Electronics" 12 "Deere & Company, Precision Farming" 11 "Dearborn Group Inc." 10 "Cummins Engine Co." 9 "Chrysler Corp." 8 "Caterpillar Inc." 7 "Case Corp." 6 "Berifors Electronics AB" 5 "AMP Inc." 4 "Ametek-Dixson" 3 "Ametek, US Gauge Division" 2 "Allison Transmission, GMC" 1 "Allied Signal Inc." 0 "Reserved" 231 "Topcon Positioning Systems, Inc." 230 "Saucon Technologies" 229 "Garmin International Inc." 228 "ZF Marine Electronics" 227 "Lykketronic A/S" 226 "Monaco Coach Corporation" 225 "SKF" 224 "EMMI Network, S.L." 223 "Vaueo Retarder Co., Ltd." 263 "IMMI" 262 "HydraForce, Inc" 261 "Red Dot Corporation" 260 "Reichhardt GmbH" 259 "Jetter AG" 258 "ARAG" 257 "Honda Motor Co., Ltd" 256 "Tyco Electronics AMP" 255 "MEAS France" 254 "GE Sensing" 253 "Mobile Control Systems" 298 "Holley Performance" 297 "Zonar Systems Inc" 296 "micro dynamics GmbH" 295 "BEP Marine" 294 "Grayhill Inc." 293 "Spyder Controls Corp." 292 "IKUSI - Angel Iglesias S.A." 291 "Groeneveld Transport Efficiency BV" 290 "Kuebler GmbH" 289 "Watlow" 288 "Mitsubishi FUSO Truck & Bus Corp." 287 "NTech Industries, Inc" 286 "Coelmo srl" 285 "Sea Recovery Corp" 284 "Mobile Tech Chile" 283 "CWF Hamilton & Co Ltd" 282 "Medallion Instrumentation Systems" 281 "Precision Governors LLC" 311 "Patrick Power Products" 310 "TECNORD srl" 309 "Krauss-Maffei Wegmann GmbH & Co. KG" 308 "Cyntrx" 307 "MBW Technologies" 306 "Sleipner Motor AB" 305 "NovAtel Inc" 304 "EmpirBus AB" 303 "CTS Corporation" 302 "Nissin Kogyo Co., LTD" 301 "Parker Hannifin (UK) Ltd FDE group" 300 "Systron Donner Automotive" 299 "Rauch Landmaschinen GmbH" 280 "Leica Geosystems Pty Ltd" 279 "Geometris LP" 278 "Takata Electronics" 277 "LHP Telematics" 276 "Aqua-Hot Heating Systems" 275 "Navico Egersund AS" 274 "LTW Technology Co., LTD" 273 "Active Research Limited" 272 "Gross Mechanical Laboratories, Inc" 327 "Sonceboz SA" 326 "Akron Brass Company" 325 "ASM Automation Sensorik Messtechnik GmbH" 324 "Snap-on Diagnostics" 323 "Mobileye Vision Technologies Ltd." 322 "MICHENKA s.r.o." 321 "Ultra Electronics, Electrics" 320 "Miedema Landbouwwerktuigenfabriek B.V." 319 "Cadec Global" 318 "SAT Plan" 317 "Navtronics Bvba" 316 "ITT Flow Control" 315 "Icom Incorporated" 314 "CSM GmbH" 313 "Ilmor Engineering, Inc" 312 "Lectronix, Inc." 271 "Cole Hersee" 270 "Tennant" 269 "Saft America Inc.,  Space & Defense Division" 268 "Accurate Technologies" 267 "Red Lion Controls, Inc" 266 "International Thermal Research Ltd" 265 "MTS Sensor Technologie GmbH" 264 "Autolync" 248 "Cooper Standard Automotive Active Systems Group" 247 "ePULSE" 246 "Class 1, Inc" 245 "Capstan Ag Systems, Inc." 244 "Techno-Matic" 243 "eRide, Inc." 242 "Kokusandenki Co. Ltd" 241 "Schneider Automation SAS " 240 "Vanair Mfg" 239 "May & Scofield Ltd" 238 "ZF Friedrichshafen AG" 237 "Agtron Enterprises Inc" 236 "Norac Systems International Inc" 235 "SailorMade Marine Telemetry - Tetra Technology Ltd." 234 "Mondial electronic GmbH" ;
VAL_ 2364473088 VehicleSystem 0 "Non-specific System" 127 "Not Available" ;
VAL_ 2364473088 VehicleSystem5 127 "Not Available" 0 "Ind. Process Control Stationary" ;
VAL_ 2364473088 VehicleSystem4 125 "Entertainment" 120 "Display" 85 "External Environment" 75 "Sensor Communication Interface" 35 "Electrical Generation" 100 "Deck, Cargo and Fishing Equipment" 90 "Internal Environment" 80 "Instrumentation/General Systems (deprecate)" 70 "Communications" 60 "Navigation" 50 "Propulsion" 40 "Steering and Control Surfaces" 30 "Electrical Distribution" 25 "Inter/Intranetwork Device" 20 "Safety Systems" 10 "System Tools" 127 "Not Available" 0 "Non-specific System" ;
VAL_ 2364473088 VehicleSystem3 8 "Grader" 7 "Four Wheel Drive Loader" 6 "Forklift" 5 "Excavator" 4 "Crawler" 3 "Backhoe" 2 "Articulated Dump Truck" 1 "Skid Steer Loader" 127 "Not Available" 0 "Non-specific System" ;
VAL_ 2364473088 VehicleSystem2 25 "Slurry Applicators" 24 "Utility Vehicles" 23 "Mulchers" 22 "Timber Processing Machines" 21 "Timber loaders" 20 "Forwarders" 19 "Timber Harvesters" 17 "Sensor Systems" 16 "Skidder" 15 "Earth Work" 14 "Special Crops" 13 "Powered Auxiliary Device" 12 "Farm Yard Operations" 11 "Transport/Trailer" 10 "Irrigation" 9 "Forage" 8 "Root Harvesters" 7 "Harvesters" 6 "Sprayers" 5 "Fertilizers" 4 "Planters/Seeders" 3 "Secondary Tillage" 2 "Tillage" 1 "Tractor" 127 "Not Available" 0 "Non-specific System" ;
VAL_ 2364473088 VehicleSystem1 2 "Trailer" 1 "Tractor" 127 "Not Available" 0 "Non-specific System" ;
VAL_ 2364473099 IndustryGroup 6 "Reserved for SAE" 7 "Reserved for SAE" 5 "IndustrialProcessCtrlStationary" 4 "Marine" 3 "Construction" 2 "Agricultural and Forestry" 1 "On-Highway" 0 "Global" ;
VAL_ 2364473099 Function 127 "Reserved" 126 "Reserved" 125 "Reserved" 124 "Reserved" 123 "Reserved" 122 "Reserved" 121 "Reserved" 120 "Reserved" 119 "Reserved" 118 "Reserved" 117 "Reserved" 116 "Reserved" 115 "Reserved" 114 "Reserved" 113 "Reserved" 112 "Reserved" 111 "Reserved" 110 "Reserved" 109 "Reserved" 108 "Reserved" 107 "Reserved" 106 "Reserved" 105 "Reserved" 104 "Reserved" 103 "Reserved" 102 "Reserved" 101 "Reserved" 42 "Water Pump Control" 41 "Lighting - Operator Controls" 40 "Seat Control" 39 "Ignition Control Module" 38 "Tire Pressure Control" 37 "Cab Controller" 36 "Pneumatic - System Controller" 35 "Suspension - System Controller" 34 "Hydraulic Pump Controller" 33 "System Monitor" 32 "Headway Controller" 31 "Propulsion Battery Charger" 30 "Management Computer" 29 "Virtual Terminal (in cab)" 28 "Off Vehicle Gateway" 27 "Power TakeOff (Secondary or Front)" 26 "Body Controller" 25 "Network Interconnect ECU" 24 "Vehicle Security" 23 "Vehicle Navigation" 22 "Aerodynamic Control" 21 "Cab Climate Control" 20 "Trip Recorder" 19 "Instrument Cluster" 18 "Suspension - Drive Axle" 17 "Suspension - Steer Axle" 16 "Steering Controller" 15 "Fuel System" 14 "Cruise Control" 13 "Retarder - Driveline" 12 "Retarder - Engine" 11 "Brakes - Drive Axle" 10 "Brakes - Steer Axle" 9 "Brakes - System Controller" 8 "Axle - Drive" 7 "Axle - Steering" 6 "Power TakeOff - (Main or Rear)" 5 "Shift Control/Console" 4 "Battery Pack Monitor" 3 "Transmission" 2 "Electric Propulsion Control" 1 "Auxiliary Power Unit (APU)" 0 "Engine" 100 "Reserved" 99 "Reserved" 98 "Reserved" 97 "Reserved" 96 "Reserved" 95 "Reserved" 94 "Reserved" 93 "Reserved" 92 "Reserved" 91 "Reserved" 90 "Reserved" 89 "Reserved" 88 "Reserved" 87 "Reserved" 86 "Reserved" 85 "Reserved" 84 "Reserved" 83 "Reserved" 82 "Reserved" 81 "Reserved" 80 "Reserved" 79 "Reserved" 78 "Fire Suppression System" 77 "Fuel Properties Sensor" 76 "Temperature Sensor" 75 "Supplemental Fan" 74 "Lubrication System" 73 "Rollover Detection Control" 72 "Coolant Valve Controller" 71 "Transfer Case Control" 70 "Auxiliary Regeneration Device" 69 "Engine Emission Aftertreatement System" 68 "Aftertreatment system gas measurement" 67 "Electrical System Controller" 66 "I/O Controller" 65 "Gas Flow Measurement" 64 "Endurance Braking" 63 "Engine Valve Controller" 62 "On-Board Diagnostic Unit" 61 "File Server/Printer" 60 "Cab Display" 59 "Starter" 58 "Fan Drive Control" 57 "Steering Column Unit" 56 "Communications Unit, Radio" 55 "Communications Unit, Satellite" 54 "Communications Unit, Cellular" 53 "Alternator/Charging System" 52 "Chassis Controller" 51 "Forward-Looking Collision Warning System" 50 "Auxiliary Heater" 49 "Clutch/Converter Control" 48 "Ramp Control" 47 "Information System Controller" 46 "Oil Sensor Unit" 45 "Vehicle Dynamic Stability Control" 44 "Exhaust Emission Control" 43 "Transmission Display" ;
VAL_ 2364473099 ManufacturerCode 454 "NGK Spark Plug Co. Ltd" 453 "Cooper Bussmann" 452 "WIKA Alexander Wiegand SE & Co. KG" 451 "Parker Hannifin Corp" 450 "Dycor Technologies Ltd." 449 "Polaris Industries Inc" 448 "Stanadyne Corporation, Electronics Systems" 447 "Great Plains Mfg." 446 "CertTech, L.L.C." 445 "KAT MECHATRONIC, Electronic Product Division" 444 "ITT Power Solutions" 443 "SignalQuest, Inc." 442 "Horsch Maschinen GmbH" 441 "PTG Reifendruckregelsysteme GmbH" 440 "Cummins Power Generation" 439 "Hyundai Heavy Industries" 438 "Comar Systems Ltd" 437 "Digital Yacht Limited" 436 "Kinze Manufacturing" 435 "Zunhammer GmbH" 434 "Stored Energy Systems" 433 "Rowe Electronics" 432 "S&A Systems, Inc." 431 "Tohatsu Corporation" 430 "Auteq Telematica S.A." 520 "Trapeze" 519 "Peeters Landbouwmachines b.v." 518 "Transas USA Inc." 517 "Noland Engineering" 516 "AVAT Automation GmbH" 515 "GINAF Trucks Nederland B.V." 514 "DISTek Integration, Inc." 513 "FarmscanAg" 512 "Inpower LLC" 511 "Sulky" 510 "Marinesoft Co. Ltd" 509 "MOTORTECH GmbH" 508 "Transtech Innovations" 507 "Test Center ISOBUS" 506 "IHI STAR Machinery Corporation" 505 "Yetter Farm Equipment" 504 "Vesper Marine" 503 "Naviop S.R.L." 502 "Attwood Corporation" 501 "Agrotronix S.A." 500 "Oxbo International Corporation" 499 "LCJ Capteurs" 498 "Innovative Design Solutions, Inc" 497 "SENTRON Sistemas Embarcados" 496 "W. Gessmann GmbH" 495 "HOLMER Maschinenbau GmbH" 494 "Synerject" 493 "Watcheye" 492 "Inergy Automotive Systems" 491 "Penny and Giles Ltd" 490 "QuikQ" 489 "Appareo Systems" 488 "The Charles Machine Works, Inc." 487 "DSE Test Solutions A/S" 486 "Westport Innovations Inc." 485 "MATT automotive" 484 "Headsight Inc." 483 "Valeo" 482 "Tricon Electronics" 481 "Chetco Digital Instruments" 480 "EnerDel, Inc." 479 "Vapor Bus International" 478 "OceanSat BV" 477 "OilQuick AB" 476 "Hummingbird Marine Electronics" 475 "GME" 474 "Persen Technologies Inc." 473 "Boss Industries, Inc." 472 "Tenneco Inc." 471 "Sea Cross Marine AB" 470 "SI-TEX Marine Electronics" 469 "RA Consulting GmbH" 468 "Tyco Fire Protection Products" 467 "Lely Industries N.V." 466 "Veethree Electronics and Marine LLC" 465 "Ashcroft Inc" 464 "Leach International Corporation" 463 "PROBOTIQ" 462 "IHI Shibaura Machinery Corporation" 461 "HAWE Hydraulik SE" 460 "San Giorgio S.E.I.N." 459 "Alltek Marine Electronics Corp" 458 "Control Solutions, Inc." 457 "RUSELPROM-ElectricDrive Ltd" 456 "General Kinetics" 455 "ADZ NAGANO GmbH" 429 "Rota Engineering Ltd." 428 "Mfg_428" 427 "em-trak Marine Electronics Ltd" 426 "Egersund Marine Electronics AS" 425 "Methode Electronics Inc, MDI" 424 "Odyne LLC" 423 "BSM Wireless, Inc." 422 "True Heading AB" 421 "Vertex Standard Co, Ltd" 420 "Vermeer Corporation, ACS Group" 419 "Fusion Electronics Ltd" 418 "Intellistick Inc" 417 "KZValve" 416 "Kubota Corporation" 415 "Valid Manufacturing Ltd." 414 "Cattron Group International" 413 "Datapross Nijbroek bv" 412 "WebTech Wireless Inc." 411 "Hy-Drive Technologies Ltd." 410 "COBO S.p.A. Divisione 3B6" 409 "Transfluid S.r.L." 408 "Corvus Energy Ltd." 407 "Comtech Mobile Datacom" 406 "Vecima Networks Inc." 405 "Wema System AS" 404 "Com Nav Marine Ltd" 403 "Trackwell ADS, Inc." 402 "Simma Software, Inc." 401 "Torqeedo GmbH" 400 "Livorsi Marine" 399 "ISEKI & Co., Ltd." 398 "Hilite International" 397 "Sanyo-kiki Co Ltd." 396 "Beyond Measure" 395 "GENTEC S.R.L." 394 "Capi 2 Nederland BV" 393 "Harvest Tec, Inc" 392 "Tianyuan Technology Co Ltd." 391 "Electronic Design for Industry, Inc" 390 "Partech Inc." 389 "Benchmark Electronics, Minnesota Division" 388 "Innomatix, LLC" 387 "Orscheln Products, LLC" 386 "JLG Automation BVBA" 385 "Johnson Outdoor Marine Electronics" 384 "Camano Light" 383 "MCL Industries" 382 "National Agricultural and Food Research Organization" 380 "Suntech International Ltd." 379 "Yamabiko Corporation" 378 "Glendinning Marine Products" 377 "ifm electronic gmbh" 376 "Quake Global" 375 "Williams Controls Inc." 372 "Delphi" 381 "B&G" 374 "Northern Lights, Inc." 373 "Electronic Design Inc." 371 "Heinzmann GmbH & Co. KG" 370 "Rolls-Royce Marine AS" 369 "Power Torque Engineering Ltd" 368 "HANSENHOF_electronic" 367 "Fliegl Agrartechnik" 366 "Viewnyx Corp." 365 "Digi-Star, LLC" 364 "OEM Controls Inc." 363 "BEI Duncan" 362 "Alois Poettinger Maschinenfabrik GmbH" 361 "InMach" 360 "HJS Emission Technology GmbH & Co KG" 359 "Ludwig Bergmann GmbH" 358 "Victron Energy BV" 357 "Hardi International A/S" 356 "Fischer Panda Generators, Inc" 355 "Mastervolt International B.V." 354 "Junkkari OY" 353 "Hegemon Electronics, Inc." 352 "SAME DEUTZ-FAHR" 351 "Thrane & Thrane" 350 "Noris Marine Systems GmbH & Co KG" 349 "Suonentiet" 348 "Amazonen Werke H. Dreyer" 347 "Honeywell" 346 "Control Solutions" 345 "Korean Maritime University" 344 "Parvus Corporation" 343 "Baumer Group" 342 "THOMAS MAGNETE GmbH" 341 "Boning GmbH & Co" 340 "Continental AG" 339 "Competence Center ISOBUS e.V." 338 "GRAF-SYTECO" 337 "Carraro S.p.A." 336 "APE s.r.o." 335 "Evo Electric Ltd" 334 "Takata-Petri AG" 333 "Hadley Products Corporation" 332 "HWH Corporation" 331 "Horton, Inc." 330 "Kidde Aerospace and Defense" 329 "Deif A/S" 328 "Qwerty Electronik AB" 252 "Sensor-Technik Wiedemann GmbH" 251 "German Agricultural Society" 250 "Kuhn Group" 249 "Schaltbau GmbH" 233 "Yacht Monitoring Solutions Inc." 232 "TSD Integrated Controls" 1863 "Thomas G. Faria Co." 1862 "Sanshin" 1861 "Vector CANtech" 1860 "MMP" 1859 "Kvasar AB" 1858 "Litton" 1857 "Simrad" 1856 "Trimble" 1855 "Furuno USA" 1854 "Northstar Technologies" 1853 "Japan Radio Co." 1852 "Navionics" 1851 "Raymarine" 1850 "Teleflex" 222 "Generac Power Systems, Inc." 221 "SiE" 220 "Beede Electrical Instrument Company, Inc." 219 "Cat OEM Solutions" 218 "Gits Manufacturing Company" 217 "RM Michaelides Software & Elektronik GmbH" 216 "Paneltronics Inc." 215 "Aetna Engineering/Fireboy-Xintex" 214 "MC elettronica Srl" 213 "CNH Belgium N.V." 212 "Sure Power Industries, Inc." 211 "DNA Group" 210 "Iteris, Inc." 209 "Bell Equip. Co. SA (PTY) LTD" 208 "Drew Technologies, Inc." 207 "Otto Engineering" 206 "port GmbH" 205 "SmarTire Systems Inc" 204 "The Morey Corporation" 203 "MILtronik GmbH" 202 "Curtis Instruments, Inc." 201 "Disenos y Tecnologia S.A." 200 "MGM Brakes" 199 "Actia Corp." 198 "Mystic Valley Communications" 197 "Mechron Power Systems" 196 "LEMKEN GmbH & Co. KG" 195 "General Engine Products" 194 "TriMark Corporation" 193 "Nobletec" 192 "Floscan" 191 "XRS Corporation" 190 "Hella KGaA Hueck & Co." 189 "QUALCOMM" 188 "EMP Corp." 187 "Air-Weigh" 186 "Altronic, Inc." 185 "Beede Electrical Instrument Company" 184 "EIA Electronics" 183 "KDS Controls, Inc." 182 "Vehicle Systems Engineering B.V." 181 "Coretronics, Inc." 180 "Smart Power Systems" 179 "TeeJet Technologies Denmark" 178 "Siemens VDO Automotive AG" 177 "Diagnostic System Associates" 176 "Moritz Aerospace" 175 "Veris Technologies, Inc." 174 "AB Volvo Penta" 173 "Ryeso, Inc." 172 "Yanmar Marine USA" 171 "Wachendorff Elektronik GmbH & Co. KG" 170 "Computronics Corporation Ltd." 169 "Marlin Technologies Inc." 168 "Xantrex" 167 "JLG Industries Inc." 166 "Phoenix International" 165 "CPAC Systems AB" 164 "DaimlerChrysler Off-Highway" 163 "BRP Inc." 162 "Axiomatic Technologies" 161 "Offshore Systems (UK) Limited" 160 "Nido" 159 "NTech Industries Inc." 158 "Firestone Industrial Products Company" 157 "ISSPRO Inc." 156 "ITT Industries - Cannon" 155 "Vetronix Corporation" 154 "Westerbeke Corporation" 153 "Woodward, Industrial Controls Division" 152 "elobau GmbH & Co. KG" 151 "Raven Industries Inc. - Flow Controls Division" 150 "Fleetguard" 149 "Holset" 148 "Blue Water Data, Inc." 147 "Nautibus Electronic GmbH" 146 "Maxima Technologies" 145 "MurCal Controls" 144 "Mercury Marine" 143 "W. Gmeiner GmbH & Co." 142 "TRW Automotive (Commercial Steering Systems)" 141 "Thales Navigation Ltd." 140 "Lowrance Electronics, Inc." 139 "Caterpillar Trimble Control Technologies (CTCT), LLC" 138 "Georg Fritzmeier GmbH & Co. KG" 137 "Maretron" 136 "Komatsu Ltd." 135 "Airmar Technology Corporation" 134 "Iris Technology Ltd." 133 "Bucher Schoerling GmbH" 132 "Mulag-Fahrzeugwerk" 131 "ITT Industries" 130 "Nido - Universal Machines B.V." 129 "OMNEX Control Systems, Inc." 128 "Gerhard Duecker GmbH & Co. KG" 127 "Holland USA" 126 "Driver Tech" 125 "Nevada Automotive Test Center" 124 "Hydac Electronic" 123 "Basler Electric" 122 "FG Wilson (Engineering) Limited" 121 "HED (Hydro Electronic Devices, Inc.)" 120 "RDS Technology Ltd." 119 "IntegriNautics" 118 "Intron GmbH" 117 "HUSCO International" 116 "BEELINE Technologies" 115 "NACCO Materials Handling Group, Inc." 114 "EControls, Inc." 113 "Stress-Tek, Inc." 112 "MECALAC" 111 "Maschinenfabrik Bernard Krone GmbH" 110 "EPIQ Sensor-Nite" 109 "TeeJet Technologies Denmark" 108 "WTK-Elecktronik GmbH" 107 "Grimme Landmaschinen GmbH & Co. KG" 106 "BAE Systems Controls, Inc." 105 "Kiepe Elektrik GmbH & Co. KG" 104 "Claas Selbstfahrende Erntemaschinen GmbH" 103 "CLAAS Agrosystems GmbH & Co. KG" 102 "AGCO GmbH & Co." 101 "Sensoria" 100 "VDO Technik AG" 99 "International Transmissions Ltd (ITL)" 98 "Mueller-Elektronik GmbH & Co." 97 "Ag Leader Technology, Inc." 96 "Mech@tronic IT GmbH" 95 "Pacific Insight Electronics Corp." 94 "CNH Global N.V." 93 "Perkins Engines Company Ltd." 92 "Ag-Chem Equipment Co., Inc." 91 "BSG Bodensee Steuergeraete GmbH" 90 "Knorr-Bremse SfN GmbH" 89 "Kverneland Group, Electronics Division" 88 "Satloc Precision GPS" 87 "J.C. Bamford Excavators Ltd (JCB)" 86 "C.E. Niehoff & Company" 85 "Kohler Co." 84 "New Holland UK Limited" 83 "Bendix VORAD Technologies" 82 "Bobcat/Ingersoll-Rand" 81 "Fire Research Corp" 80 "Twin Disc, Inc." 79 "Daimler Benz AG - Engine Division (PBM)" 78 "Frank W. Murphy Manufacturing, Inc." 77 "Deere Power Systems Group" 76 "unused" 75 "Deere & Co. Agricultural Division" 74 "Eaton Axle-Brake Division" 73 "LeTourneau, Inc." 72 "Sisu Corporation" 71 "Vansco Electronics Ltd." 70 "Flex-Coil Limited" 69 "Trimble Navigation" 68 "Scania" 67 "Funk Manufacturing Company" 66 "John Deere Construction Equipment Division" 65 "MAN Nutzfahrzeuge AG" 64 "unused" 63 "ZF Industries Inc." 62 "Wabco" 61 "Volvo Truck Corp." 60 "Volvo Trucks North America Inc." 59 "VES Inc." 58 "SPX Corporation, OTC Division" 57 "Sauer-Danfoss Co." 56 "SAIC" 55 "Ryder System Inc." 54 "Meritor Wabco" 53 "Continental Automotive Systems US, Inc." 52 "Meritor Automotive, Inc." 51 "Robert Bosch GmbH" 50 "Robert Bosch Corp" 49 "RE America Inc." 48 "Pollak Alphabet" 47 "Phillips Semiconductor" 46 "Noregon Systems, Inc" 45 "PACCAR" 44 "Nippondenso Co. Ltd." 43 "International Truck and Engine Corp. Vehicle Electronics" 42 "International Truck and Engine Corp. Engine Electronics" 41 "Motorola Inc." 40 "Motorola AIEG Inc." 39 "Microfirm Inc." 38 "Micro Processor Systems Inc." 37 "Mack Trucks Inc." 36 "Lucas Ltd." 35 "Kenworth Truck Co." 34 "Kelsey Hayes Co." 33 "John Deere" 32 "Jacobs Vehicle Systems" 31 "J Pollak Corp." 30 "Isuzu Motors Ltd." 29 "Hino Motors Ltd." 28 "Grote Ind. Inc." 27 "GMC" 26 "General Motors Corp., Service Technology Group" 25 "Daimler Trucks North America LLC" 24 "Ford Motor Co., Vehicle Controls" 23 "Ford Motor Co., Heavy Truck" 22 "Ford Motor Co., Electronic Concepts $ Systems" 21 "Echilin Inc., Midland Brake Inc." 20 "Eaton Ltd" 19 "Eaton Corp. Trucking Info Services" 18 "Eaton Corp, Transmission Division" 17 "Eaton Corp. Res & Dev" 16 "Eaton Corp." 15 "Dickey-John Corp." 14 "Detroit Diesel Corporation" 13 "Delco Electronics" 12 "Deere & Company, Precision Farming" 11 "Dearborn Group Inc." 10 "Cummins Engine Co." 9 "Chrysler Corp." 8 "Caterpillar Inc." 7 "Case Corp." 6 "Berifors Electronics AB" 5 "AMP Inc." 4 "Ametek-Dixson" 3 "Ametek, US Gauge Division" 2 "Allison Transmission, GMC" 1 "Allied Signal Inc." 0 "Reserved" 231 "Topcon Positioning Systems, Inc." 230 "Saucon Technologies" 229 "Garmin International Inc." 228 "ZF Marine Electronics" 227 "Lykketronic A/S" 226 "Monaco Coach Corporation" 225 "SKF" 224 "EMMI Network, S.L." 223 "Vaueo Retarder Co., Ltd." 263 "IMMI" 262 "HydraForce, Inc" 261 "Red Dot Corporation" 260 "Reichhardt GmbH" 259 "Jetter AG" 258 "ARAG" 257 "Honda Motor Co., Ltd" 256 "Tyco Electronics AMP" 255 "MEAS France" 254 "GE Sensing" 253 "Mobile Control Systems" 298 "Holley Performance" 297 "Zonar Systems Inc" 296 "micro dynamics GmbH" 295 "BEP Marine" 294 "Grayhill Inc." 293 "Spyder Controls Corp." 292 "IKUSI - Angel Iglesias S.A." 291 "Groeneveld Transport Efficiency BV" 290 "Kuebler GmbH" 289 "Watlow" 288 "Mitsubishi FUSO Truck & Bus Corp." 287 "NTech Industries, Inc" 286 "Coelmo srl" 285 "Sea Recovery Corp" 284 "Mobile Tech Chile" 283 "CWF Hamilton & Co Ltd" 282 "Medallion Instrumentation Systems" 281 "Precision Governors LLC" 311 "Patrick Power Products" 310 "TECNORD srl" 309 "Krauss-Maffei Wegmann GmbH & Co. KG" 308 "Cyntrx" 307 "MBW Technologies" 306 "Sleipner Motor AB" 305 "NovAtel Inc" 304 "EmpirBus AB" 303 "CTS Corporation" 302 "Nissin Kogyo Co., LTD" 301 "Parker Hannifin (UK) Ltd FDE group" 300 "Systron Donner Automotive" 299 "Rauch Landmaschinen GmbH" 280 "Leica Geosystems Pty Ltd" 279 "Geometris LP" 278 "Takata Electronics" 277 "LHP Telematics" 276 "Aqua-Hot Heating Systems" 275 "Navico Egersund AS" 274 "LTW Technology Co., LTD" 273 "Active Research Limited" 272 "Gross Mechanical Laboratories, Inc" 327 "Sonceboz SA" 326 "Akron Brass Company" 325 "ASM Automation Sensorik Messtechnik GmbH" 324 "Snap-on Diagnostics" 323 "Mobileye Vision Technologies Ltd." 322 "MICHENKA s.r.o." 321 "Ultra Electronics, Electrics" 320 "Miedema Landbouwwerktuigenfabriek B.V." 319 "Cadec Global" 318 "SAT Plan" 317 "Navtronics Bvba" 316 "ITT Flow Control" 315 "Icom Incorporated" 314 "CSM GmbH" 313 "Ilmor Engineering, Inc" 312 "Lectronix, Inc." 271 "Cole Hersee" 270 "Tennant" 269 "Saft America Inc.,  Space & Defense Division" 268 "Accurate Technologies" 267 "Red Lion Controls, Inc" 266 "International Thermal Research Ltd" 265 "MTS Sensor Technologie GmbH" 264 "Autolync" 248 "Cooper Standard Automotive Active Systems Group" 247 "ePULSE" 246 "Class 1, Inc" 245 "Capstan Ag Systems, Inc." 244 "Techno-Matic" 243 "eRide, Inc." 242 "Kokusandenki Co. Ltd" 241 "Schneider Automation SAS " 240 "Vanair Mfg" 239 "May & Scofield Ltd" 238 "ZF Friedrichshafen AG" 237 "Agtron Enterprises Inc" 236 "Norac Systems International Inc" 235 "SailorMade Marine Telemetry - Tetra Technology Ltd." 234 "Mondial electronic GmbH" ;
VAL_ 2364473099 VehicleSystem 0 "Non-specific System" 127 "Not Available" ;
VAL_ 2364473099 VehicleSystem5 127 "Not Available" 0 "Ind. Process Control Stationary" ;
VAL_ 2364473099 VehicleSystem4 125 "Entertainment" 120 "Display" 85 "External Environment" 75 "Sensor Communication Interface" 35 "Electrical Generation" 100 "Deck, Cargo and Fishing Equipment" 90 "Internal Environment" 80 "Instrumentation/General Systems (deprecate)" 70 "Communications" 60 "Navigation" 50 "Propulsion" 40 "Steering and Control Surfaces" 30 "Electrical Distribution" 25 "Inter/Intranetwork Device" 20 "Safety Systems" 10 "System Tools" 127 "Not Available" 0 "Non-specific System" ;
VAL_ 2364473099 VehicleSystem3 8 "Grader" 7 "Four Wheel Drive Loader" 6 "Forklift" 5 "Excavator" 4 "Crawler" 3 "Backhoe" 2 "Articulated Dump Truck" 1 "Skid Steer Loader" 127 "Not Available" 0 "Non-specific System" ;
VAL_ 2364473099 VehicleSystem2 25 "Slurry Applicators" 24 "Utility Vehicles" 23 "Mulchers" 22 "Timber Processing Machines" 21 "Timber loaders" 20 "Forwarders" 19 "Timber Harvesters" 17 "Sensor Systems" 16 "Skidder" 15 "Earth Work" 14 "Special Crops" 13 "Powered Auxiliary Device" 12 "Farm Yard Operations" 11 "Transport/Trailer" 10 "Irrigation" 9 "Forage" 8 "Root Harvesters" 7 "Harvesters" 6 "Sprayers" 5 "Fertilizers" 4 "Planters/Seeders" 3 "Secondary Tillage" 2 "Tillage" 1 "Tractor" 127 "Not Available" 0 "Non-specific System" ;
VAL_ 2364473099 VehicleSystem1 2 "Trailer" 1 "Tractor" 127 "Not Available" 0 "Non-specific System" ;
